VERSION "1.11.2"

NS_ :

BS_:

BU_: TCU BRK ESP MCU RDD GP TMS GW KPD1 RDE FNR ECU KPD2 ATSGO ACU IMU1 IMU2 IMU3 IMU4 IMU5 AGW PMI HDOQS EGOQS OBC EEC CBSW EJRH EJLH EPDLT EPDL2 EPDLR EPDLA TRBDZ ECU1 CLST LC510 EGDL JS SMB KPAC ACCU Audio TGU RDRR RDLH RDRH AVM CHMSL CTC SMK EVC MCU2 PHM MC3D AMBLMP RCTGU RDU PT3D XCU can1 can2

BO_ 2566879562 TGU_TGUID: 35 TGU
 SG_ ProdDt : 208|72@1+ (1,0) [0|4.72236648286965E+21] "ASCII-FN" Vector__XXX
 SG_ TguId : 48|160@1+ (1,0) [0|1.4615016373309E+48] "ASCII-FN" Vector__XXX
 SG_ TypeCd : 0|48@1+ (1,0) [0|281474976710655] "ASCII-FN" Vector__XXX

BO_ 2583645002 TGU_GPSINFO: 13 TGU
 SG_ GpsSt : 96|8@1+ (1,0) [0|255] "" Vector__XXX
 SG_ NoOfGpsSat : 88|8@1+ (1,0) [0|255] "" Vector__XXX
 SG_ Z : 64|16@1+ (0.125,-2500) [-2500|5531.875] "m" Vector__XXX
 SG_ Y : 32|32@1+ (1E-07,-210) [-210|211.1081215] "deg" Vector__XXX
 SG_ X : 0|32@1+ (1E-07,-210) [-210|211.1081215] "deg" Vector__XXX

BO_ 2583644490 TGU_CINFO: 145 TGU
 SG_ GsmdBm : 1128|32@1+ (1,0) [0|4294967295] "ASCII-FN" Vector__XXX
 SG_ GsmType : 1120|8@1+ (1,0) [0|255] "" Vector__XXX
 SG_ CurNw : 1048|72@1+ (1,0) [0|4.72236648286965E+21] "ASCII-FN" Vector__XXX
 SG_ TmnIpAdr : 920|128@1+ (1,0) [0|3.40282366920938E+38] "ASCII-FN" Vector__XXX
 SG_ ServerAdr : 792|128@1+ (1,0) [0|3.40282366920938E+38] "ASCII-FN" Vector__XXX
 SG_ Apn : 288|504@1+ (1,0) [0|5.23742497263383E+151] "ASCII-FN" Vector__XXX
 SG_ Imei : 168|120@1+ (1,0) [0|1.32922799578492E+36] "ASCII-FN" Vector__XXX
 SG_ SimIccid : 0|168@1+ (1,0) [0|3.74144419156711E+50] "ASCII-FN" Vector__XXX

BO_ 2566878282 TGU_SAT: 18 TGU
 SG_ Install : 136|4@1+ (1,0) [0|3] "" Vector__XXX
 SG_ Imei : 16|120@1+ (1,0) [0|1.32922799578492E+36] "ASCII" Vector__XXX
 SG_ Rssi : 8|8@1+ (1,0) [0|255] "" Vector__XXX
 SG_ Type : 4|4@1+ (1,0) [0|3] "" Vector__XXX
 SG_ Enable : 0|4@1+ (1,0) [0|3] "" Vector__XXX

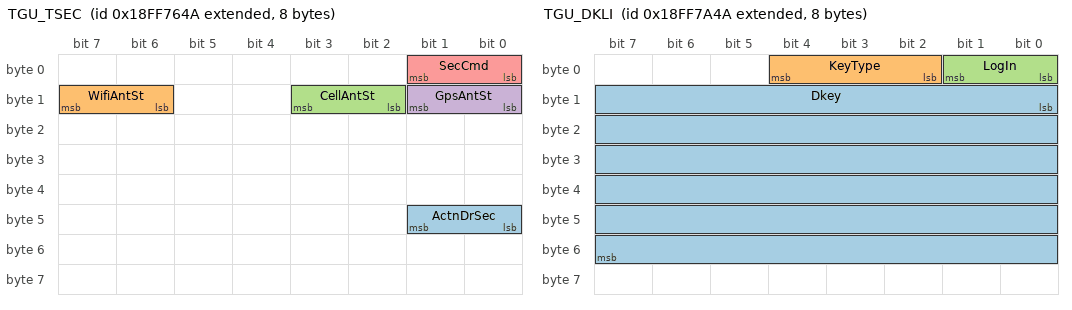
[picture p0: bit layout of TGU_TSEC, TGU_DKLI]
BO_ 2566878794 TGU_TSEC: 8 TGU
 SG_ ActnDrSec : 40|2@1+ (1,0) [0|3] "" Vector__XXX
 SG_ WifiAntSt : 14|2@1+ (1,0) [0|3] "" Vector__XXX
 SG_ CellAntSt : 10|2@1+ (1,0) [0|3] "" Vector__XXX
 SG_ GpsAntSt : 8|2@1+ (1,0) [0|3] "" Vector__XXX
 SG_ SecCmd : 0|2@1+ (1,0) [0|3] "" Vector__XXX

BO_ 2583644746 TGU_TGUTM: 8 TGU
 SG_ UtcTm : 32|32@1+ (1,0) [0|4294967295] "sec" Vector__XXX
 SG_ LocalTmOffset : 0|32@1+ (1,0) [-2147483647|2147483647] "sec" Vector__XXX

BO_ 2566879272 GP_TMSTP: 8 GP

BO_ 2566879306 TGU_TMSTP: 8 TGU

BO_ 2566879818 TGU_DKLI: 8 TGU
 SG_ Dkey : 8|48@1+ (1,0) [0|0] "binary" Vector__XXX
 SG_ KeyType : 2|3@1+ (1,0) [0|7] "" Vector__XXX
 SG_ LogIn : 0|2@1+ (1,0) [0|3] "" Vector__XXX

BO_ 2566880074 TGU_DKLD: 37 TGU
 SG_ DkeyList : 8|288@1+ (1,0) [0|4.97323236409787E+86] "binary" Vector__XXX
 SG_ Cnt : 0|8@1+ (1,0) [0|255] "" Vector__XXX

BO_ 2566880296 GP_DKSEL: 8 GP
 SG_ DigitalKey : 8|48@1+ (1,0) [0|281474976710655] "" Vector__XXX
 SG_ SelType : 0|3@1+ (1,0) [0|7] "" Vector__XXX

BO_ 2566880586 TGU_TACK: 8 TGU
 SG_ Ack : 0|2@1+ (1,0) [0|3] "" Vector__XXX

BO_ 2566880842 TGU_TMSPUC: 8 TGU
 SG_ TmsPmntUnlockCd : 0|32@1+ (1,0) [0|4294967295] "" Vector__XXX

BO_ 2566881064 GP_TMSPP: 8 GP

BO_ 2566881098 TGU_TMSPP: 8 TGU

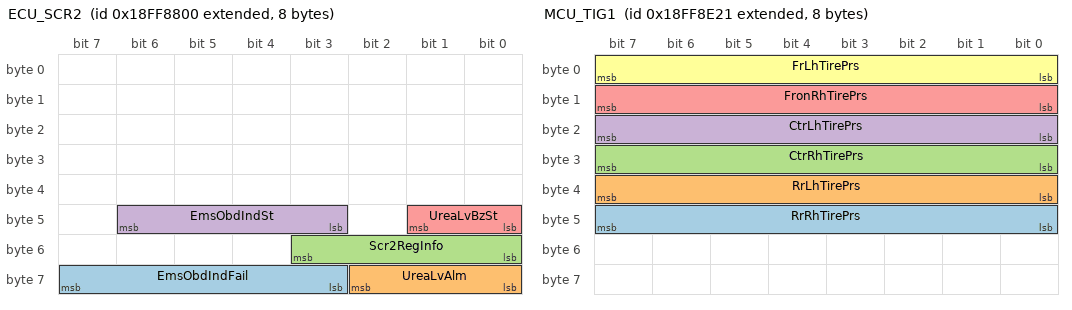
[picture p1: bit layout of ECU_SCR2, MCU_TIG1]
BO_ 2566883328 ECU_SCR2: 8 ECU
 SG_ EmsObdIndFail : 59|5@1+ (1,0) [0|31] "" Vector__XXX
 SG_ UreaLvAlm : 56|3@1+ (1,0) [0|7] "" Vector__XXX
 SG_ Scr2RegInfo : 48|4@1+ (1,0) [0|15] "" Vector__XXX
 SG_ EmsObdIndSt : 43|4@1+ (1,0) [0|15] "" Vector__XXX
 SG_ UreaLvBzSt : 40|2@1+ (1,0) [0|3] "" Vector__XXX

BO_ 2583625761 MCU_AASI: 70 MCU
 SG_ RrSspnLhSsPrs : 544|16@1+ (0.0625,0) [0|500] "bar" Vector__XXX
 SG_ RrSspnRhSsPrs : 528|16@1+ (0.0625,0) [0|500] "bar" Vector__XXX
 SG_ AcpSsPrs : 512|16@1+ (16,0) [0|4000] "kPa" Vector__XXX
 SG_ BatVlt : 496|16@1+ (1,0) [0|40000] "V" Vector__XXX
 SG_ AltVlt : 480|16@1+ (0.001,0) [0|64.255] "V" Vector__XXX
 SG_ Rr2BrkSsPrs : 464|16@1+ (0.0625,0) [0|500] "bar" Vector__XXX
 SG_ BoomCylRodSsPrs : 448|16@1+ (0.0625,0) [0|500] "bar" Vector__XXX
 SG_ BoomCylHeadSsPrs : 432|16@1+ (0.0625,0) [0|500] "bar" Vector__XXX
 SG_ CtrPinAngSs1Vlt : 416|16@1+ (0.001,0) [0|64.255] "V" Vector__XXX
 SG_ AccPdlSs2Vlt : 400|16@1+ (0.001,0) [0|64.255] "V" Vector__XXX
 SG_ DumpBedAngSs2Vlt : 384|16@1+ (0.001,0) [0|64.255] "V" Vector__XXX
 SG_ DumpBedAngSs1Vlt : 368|16@1+ (0.001,0) [0|64.255] "V" Vector__XXX
 SG_ BrkInchPdlSs1Vlt : 352|16@1+ (0.001,0) [0|64.255] "V" Vector__XXX
 SG_ TipJoySs1Vlt : 336|16@1+ (0.001,0) [0|64.255] "V" Vector__XXX
 SG_ RhCylSsPrs : 320|16@1+ (0.0625,0) [0|500] "bar" Vector__XXX
 SG_ EmgStrSsPrs : 304|16@1+ (0.0625,0) [0|500] "bar" Vector__XXX
 SG_ AxleOilSsTmp : 288|16@1- (1,-40) [-40|210] "celsius" Vector__XXX
 SG_ FuelSsLv : 272|16@1+ (1,0) [0|250] "percent" Vector__XXX
 SG_ Rr1BrkSsPrs : 256|16@1+ (0.0625,0) [0|500] "bar" Vector__XXX
 SG_ FrBrkSsPrs : 240|16@1+ (0.0625,0) [0|500] "bar" Vector__XXX
 SG_ AccPdlSs1Vlt : 224|16@1+ (0.001,0) [0|64.255] "V" Vector__XXX
 SG_ CtrPinAngSs2Vlt : 208|16@1+ (0.001,0) [0|64.255] "V" Vector__XXX
 SG_ TmsSecVlt : 192|16@1+ (0.001,0) [0|64.255] "V" Vector__XXX
 SG_ LhCylSsPrs : 176|16@1+ (0.0625,0) [0|500] "bar" Vector__XXX
 SG_ Acc3SsPrs : 160|16@1+ (0.0625,0) [0|500] "bar" Vector__XXX
 SG_ BrkInchPdlSs2Vlt : 144|16@1+ (0.001,0) [0|64.255] "V" Vector__XXX
 SG_ CacFanSsPrs : 128|16@1+ (0.0625,0) [0|500] "bar" Vector__XXX
 SG_ Acc2SsPrs : 112|16@1+ (0.0625,0) [0|500] "bar" Vector__XXX
 SG_ TipJoySs2Vlt : 96|16@1+ (0.001,0) [0|64.255] "V" Vector__XXX
 SG_ TocFanSsPrs : 80|16@1+ (0.0625,0) [0|500] "bar" Vector__XXX
 SG_ Acc1SsPrs : 64|16@1+ (0.0625,0) [0|500] "bar" Vector__XXX
 SG_ PrkBrkSsPrs : 48|16@1+ (0.0625,0) [0|500] "bar" Vector__XXX
 SG_ MainSsPrs : 32|16@1+ (0.0625,0) [0|500] "bar" Vector__XXX
 SG_ WifSsVlt : 16|16@1+ (0.001,0) [0|64.255] "V" Vector__XXX
 SG_ HydOilSsTmp : 0|16@1- (1,-40) [-40|210] "celsius" Vector__XXX

BO_ 2583626017 MCU_AAAI: 16 MCU
 SG_ FanDrvTocEvc : 112|16@1+ (1,0) [0|2000] "mA" Vector__XXX
 SG_ eFan2DutyRatio : 96|16@1- (0.01,-321.27) [-321.27|321.28] "percent" Vector__XXX
 SG_ eFan3DutyRatio : 80|16@1- (0.01,-321.27) [-321.27|321.28] "percent" Vector__XXX
 SG_ eBrkEvc : 64|16@1+ (1,0) [0|2000] "mA" Vector__XXX
 SG_ eFan1DutyRatio : 48|16@1- (0.01,-321.27) [-321.27|321.28] "percent" Vector__XXX
 SG_ FanDrvRadCacEvc : 32|16@1+ (1,0) [0|2000] "mA" Vector__XXX
 SG_ BodyDnEvc : 16|16@1+ (1,0) [0|2000] "mA" Vector__XXX
 SG_ BodyUpEvc : 0|16@1+ (1,0) [0|2000] "mA" Vector__XXX

BO_ 2583626273 MCU_ADSI: 250 MCU
 SG_ BrkholdSw : 44|2@1+ (1,0) [0|3] "" Vector__XXX
 SG_ DhlMnSw : 42|2@1+ (1,0) [0|3] "" Vector__XXX
 SG_ CoolTankLvSw : 40|2@1+ (1,0) [0|3] "" Vector__XXX
 SG_ StartCrkSw : 38|2@1+ (1,0) [0|3] "" Vector__XXX
 SG_ GrSelSw : 36|2@1+ (1,0) [0|3] "" Vector__XXX
 SG_ GrSelNtrlSw : 34|2@1+ (1,0) [0|3] "" Vector__XXX
 SG_ PrkSw : 32|2@1+ (1,0) [0|3] "" Vector__XXX
 SG_ GrSelRvsSw : 30|2@1+ (1,0) [0|3] "" Vector__XXX
 SG_ GrSelShftDnSw : 28|2@1+ (1,0) [0|3] "" Vector__XXX
 SG_ GrSelShftUpSw : 26|2@1+ (1,0) [0|3] "" Vector__XXX
 SG_ GrSelFwdSw : 24|2@1+ (1,0) [0|3] "" Vector__XXX
 SG_ DustIndSw : 22|2@1+ (1,0) [0|3] "" Vector__XXX
 SG_ StartAccSw : 20|2@1+ (1,0) [0|3] "" Vector__XXX
 SG_ AtsForceRgnSw : 18|2@1+ (1,0) [0|3] "" Vector__XXX
 SG_ AtsRgnIhbsw : 16|2@1+ (1,0) [0|3] "" Vector__XXX
 SG_ eFan3ErrSt : 14|2@1+ (1,0) [0|3] "" Vector__XXX
 SG_ KeyBrSw : 12|2@1+ (1,0) [0|3] "" Vector__XXX
 SG_ TipJoySw : 10|2@1+ (1,0) [0|3] "" Vector__XXX
 SG_ AgsSw : 8|2@1+ (1,0) [0|3] "" Vector__XXX
 SG_ eFan2ErrSt : 6|2@1+ (1,0) [0|3] "" Vector__XXX
 SG_ eFan1ErrSt : 4|2@1+ (1,0) [0|3] "" Vector__XXX
 SG_ SeatBeltSt : 2|2@1+ (1,0) [0|3] "" Vector__XXX
 SG_ FrWiperStpSw : 0|2@1+ (1,0) [0|3] "" Vector__XXX

BO_ 2583626529 MCU_ADAI: 250 MCU
 SG_ RrSspnRhDn : 48|2@1+ (1,0) [0|3] "" Vector__XXX
 SG_ RrSspnRhUp : 46|2@1+ (1,0) [0|3] "" Vector__XXX
 SG_ RrSspnLhDn : 44|2@1+ (1,0) [0|3] "" Vector__XXX
 SG_ RrSspnLhUp : 42|2@1+ (1,0) [0|3] "" Vector__XXX
 SG_ SusRhDn : 40|2@1+ (1,0) [0|3] "" Vector__XXX
 SG_ TocRvs : 38|2@1+ (1,0) [0|3] "" Vector__XXX
 SG_ TurnSigRhRly : 36|2@1+ (1,0) [0|3] "" Vector__XXX
 SG_ TurnSigLhRly : 34|2@1+ (1,0) [0|3] "" Vector__XXX
 SG_ SusRhUp : 32|2@1+ (1,0) [0|3] "" Vector__XXX
 SG_ EgRunOutSig : 30|2@1+ (1,0) [0|3] "" Vector__XXX
 SG_ SusLhDn : 28|2@1+ (1,0) [0|3] "" Vector__XXX
 SG_ UreaSuperChgWrnSig : 26|2@1+ (1,0) [0|3] "" Vector__XXX
 SG_ FanStpSv : 24|2@1+ (1,0) [0|3] "" Vector__XXX
 SG_ SusLhUp : 18|2@1+ (1,0) [0|3] "" Vector__XXX
 SG_ PrkBrkRlsSv : 16|2@1+ (1,0) [0|3] "" Vector__XXX
 SG_ AxleOilCoolSv : 14|2@1+ (1,0) [0|3] "" Vector__XXX
 SG_ TocUnloading : 12|2@1+ (1,0) [0|3] "" Vector__XXX
 SG_ AccRly : 10|2@1+ (1,0) [0|3] "" Vector__XXX
 SG_ LiftArmFlt : 6|2@1+ (1,0) [0|3] "" Vector__XXX
 SG_ AutoShutOffRly : 4|2@1+ (1,0) [0|3] "" Vector__XXX
 SG_ BrkChgSv : 2|2@1+ (1,0) [0|3] "" Vector__XXX

BO_ 2566884897 MCU_TIG1: 8 MCU
 SG_ RrRhTirePrs : 40|8@1+ (4,0) [0|1000] "kPa" Vector__XXX
 SG_ RrLhTirePrs : 32|8@1+ (4,0) [0|1000] "kPa" Vector__XXX
 SG_ CtrRhTirePrs : 24|8@1+ (4,0) [0|1000] "kPa" Vector__XXX
 SG_ CtrLhTirePrs : 16|8@1+ (4,0) [0|1000] "kPa" Vector__XXX
 SG_ FronRhTirePrs : 8|8@1+ (4,0) [0|1000] "kPa" Vector__XXX
 SG_ FrLhTirePrs : 0|8@1+ (4,0) [0|1000] "kPa" Vector__XXX

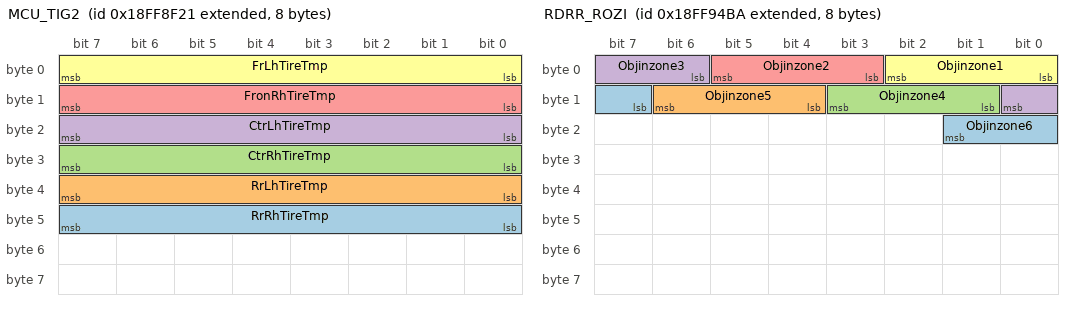
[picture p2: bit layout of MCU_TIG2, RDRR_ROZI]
BO_ 2566885153 MCU_TIG2: 8 MCU
 SG_ RrRhTireTmp : 40|8@1- (1,-40) [-40|210] "celsius" Vector__XXX
 SG_ RrLhTireTmp : 32|8@1- (1,-40) [-40|210] "celsius" Vector__XXX
 SG_ CtrRhTireTmp : 24|8@1- (1,-40) [-40|210] "celsius" Vector__XXX
 SG_ CtrLhTireTmp : 16|8@1- (1,-40) [-40|210] "celsius" Vector__XXX
 SG_ FronRhTireTmp : 8|8@1- (1,-40) [-40|210] "celsius" Vector__XXX
 SG_ FrLhTireTmp : 0|8@1- (1,-40) [-40|210] "celsius" Vector__XXX

BO_ 2566885409 MCU_QRCI: 55 MCU
 SG_ PartNo : 312|128@1+ (1,0) [0|3.40282366920938E+38] "ASCII-FN" Vector__XXX
 SG_ SerialNo : 184|128@1+ (1,0) [0|3.40282366920938E+38] "ASCII-FN" Vector__XXX
 SG_ MnftCode : 120|64@1+ (1,0) [0|1.84467440737096E+19] "ASCII-FN" Vector__XXX
 SG_ ComCode : 56|64@1+ (1,0) [0|1.84467440737096E+19] "ASCII-FN" Vector__XXX
 SG_ Year : 48|8@1+ (1,1985) [1985|2235] "year" Vector__XXX
 SG_ Day : 40|8@1+ (0.25,0) [0|62.5] "days" Vector__XXX
 SG_ Month : 32|8@1+ (1,0) [0|250] "month" Vector__XXX
 SG_ SwVer : 0|32@1+ (1,0) [0|4294967295] "ASCII" Vector__XXX

BO_ 2566885665 MCU_ECORI: 30 MCU
 SG_ TotAvgReliefOprPct : 232|8@1+ (1,0) [0|250] "percent" Vector__XXX
 SG_ TotAvgLwIdleOprPct : 224|8@1+ (1,0) [0|250] "percent" Vector__XXX
 SG_ TotAvgHhIdleOprPct : 216|8@1+ (1,0) [0|250] "percent" Vector__XXX
 SG_ Day7ReliefOprPct : 208|8@1+ (1,0) [0|250] "percent" Vector__XXX
 SG_ Day7LwIdleOprPct : 200|8@1+ (1,0) [0|250] "percent" Vector__XXX
 SG_ Day7HhIdleOprPct : 192|8@1+ (1,0) [0|250] "percent" Vector__XXX
 SG_ Day6ReliefOprPct : 184|8@1+ (1,0) [0|250] "percent" Vector__XXX
 SG_ Day6LwIdleOprPct : 176|8@1+ (1,0) [0|250] "percent" Vector__XXX
 SG_ Day6HhIdleOprPct : 168|8@1+ (1,0) [0|250] "percent" Vector__XXX
 SG_ Day5ReliefOprPct : 160|8@1+ (1,0) [0|250] "percent" Vector__XXX
 SG_ Day5LwIdleOprPct : 152|8@1+ (1,0) [0|250] "percent" Vector__XXX
 SG_ Day5HhIdleOprPct : 144|8@1+ (1,0) [0|250] "percent" Vector__XXX
 SG_ Day4ReliefOprPct : 136|8@1+ (1,0) [0|250] "percent" Vector__XXX
 SG_ Day4LwIdleOprPct : 128|8@1+ (1,0) [0|250] "percent" Vector__XXX
 SG_ Day4HhIdleOprPct : 120|8@1+ (1,0) [0|250] "percent" Vector__XXX
 SG_ Day3ReliefOprPct : 112|8@1+ (1,0) [0|250] "percent" Vector__XXX
 SG_ Day3LwIdleOprPct : 104|8@1+ (1,0) [0|250] "percent" Vector__XXX
 SG_ Day3HhIdleOprPct : 96|8@1+ (1,0) [0|250] "percent" Vector__XXX
 SG_ Day2ReliefOprPct : 88|8@1+ (1,0) [0|250] "percent" Vector__XXX
 SG_ Day2LwIdleOprPct : 80|8@1+ (1,0) [0|250] "percent" Vector__XXX
 SG_ Day2HhIdleOprPct : 72|8@1+ (1,0) [0|250] "percent" Vector__XXX
 SG_ Day1ReliefOprPct : 64|8@1+ (1,0) [0|250] "percent" Vector__XXX
 SG_ Day1LwIdleOprPct : 56|8@1+ (1,0) [0|250] "percent" Vector__XXX
 SG_ Day1HhIdleOprPct : 48|8@1+ (1,0) [0|250] "percent" Vector__XXX
 SG_ NowReliefOprLv : 40|8@1+ (1,0) [0|250] "percent" Vector__XXX
 SG_ NowLwIdleOprLv : 32|8@1+ (1,0) [0|250] "percent" Vector__XXX
 SG_ NowHhIdleOprLv : 24|8@1+ (1,0) [0|250] "percent" Vector__XXX
 SG_ NowReliefOprPct : 16|8@1+ (1,0) [0|250] "percent" Vector__XXX
 SG_ NowLwIdleOprPct : 8|8@1+ (1,0) [0|250] "percent" Vector__XXX
 SG_ NowHhIdleOprPct : 0|8@1+ (1,0) [0|250] "percent" Vector__XXX

BO_ 2566886586 RDRR_ROZI: 8 RDRR
 SG_ Objinzone6 : 15|3@1+ (1,0) [0|7] "" Vector__XXX
 SG_ Objinzone5 : 12|3@1+ (1,0) [0|7] "" Vector__XXX
 SG_ Objinzone4 : 9|3@1+ (1,0) [0|7] "" Vector__XXX
 SG_ Objinzone3 : 6|3@1+ (1,0) [0|7] "" Vector__XXX
 SG_ Objinzone2 : 3|3@1+ (1,0) [0|7] "" Vector__XXX
 SG_ Objinzone1 : 0|3@1+ (1,0) [0|7] "" Vector__XXX

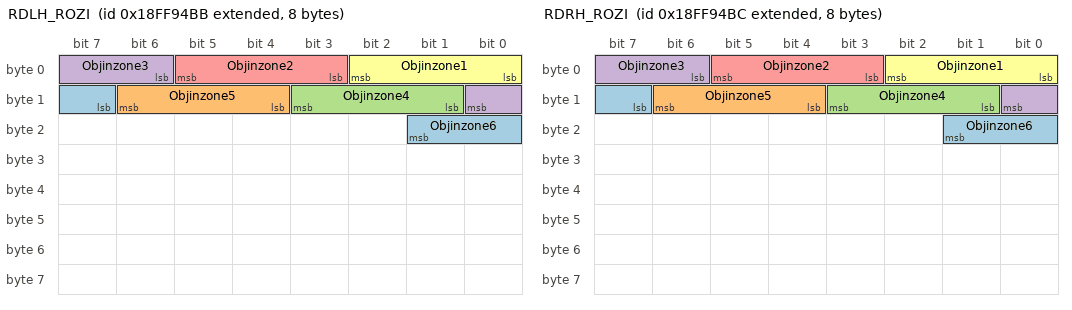
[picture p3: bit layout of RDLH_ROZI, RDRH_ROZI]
BO_ 2566886587 RDLH_ROZI: 8 RDLH
 SG_ Objinzone6 : 15|3@1+ (1,0) [0|7] "" Vector__XXX
 SG_ Objinzone5 : 12|3@1+ (1,0) [0|7] "" Vector__XXX
 SG_ Objinzone4 : 9|3@1+ (1,0) [0|7] "" Vector__XXX
 SG_ Objinzone3 : 6|3@1+ (1,0) [0|7] "" Vector__XXX
 SG_ Objinzone2 : 3|3@1+ (1,0) [0|7] "" Vector__XXX
 SG_ Objinzone1 : 0|3@1+ (1,0) [0|7] "" Vector__XXX

BO_ 2566886588 RDRH_ROZI: 8 RDRH
 SG_ Objinzone6 : 15|3@1+ (1,0) [0|7] "" Vector__XXX
 SG_ Objinzone5 : 12|3@1+ (1,0) [0|7] "" Vector__XXX
 SG_ Objinzone4 : 9|3@1+ (1,0) [0|7] "" Vector__XXX
 SG_ Objinzone3 : 6|3@1+ (1,0) [0|7] "" Vector__XXX
 SG_ Objinzone2 : 3|3@1+ (1,0) [0|7] "" Vector__XXX
 SG_ Objinzone1 : 0|3@1+ (1,0) [0|7] "" Vector__XXX

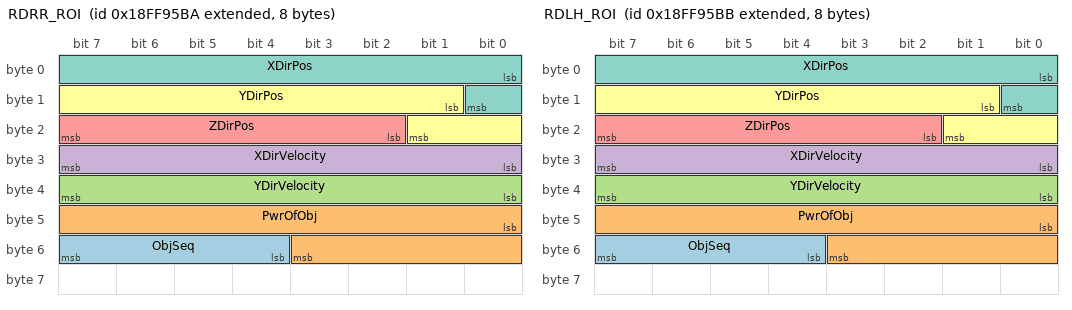
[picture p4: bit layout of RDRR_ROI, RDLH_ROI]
BO_ 2566886842 RDRR_ROI: 8 RDRR
 SG_ ObjSeq : 52|4@1+ (1,0) [0|10] "" Vector__XXX
 SG_ PwrOfObj : 40|12@1+ (1,0) [0|2500] "" Vector__XXX
 SG_ YDirVelocity : 32|8@1+ (0.2,-12) [-12|12] "mps" Vector__XXX
 SG_ XDirVelocity : 24|8@1+ (0.2,-12) [-12|12] "mps" Vector__XXX
 SG_ ZDirPos : 18|6@1+ (0.1,-3) [-3|3] "m" Vector__XXX
 SG_ YDirPos : 9|9@1+ (0.1,-16) [-16|16] "m" Vector__XXX
 SG_ XDirPos : 0|9@1+ (0.1,-16) [-16|16] "m" Vector__XXX

BO_ 2566886843 RDLH_ROI: 8 RDLH
 SG_ ObjSeq : 52|4@1+ (1,0) [0|10] "" Vector__XXX
 SG_ PwrOfObj : 40|12@1+ (1,0) [0|2500] "" Vector__XXX
 SG_ YDirVelocity : 32|8@1+ (0.2,-12) [-12|12] "mps" Vector__XXX
 SG_ XDirVelocity : 24|8@1+ (0.2,-12) [-12|12] "mps" Vector__XXX
 SG_ ZDirPos : 18|6@1+ (0.1,-3) [-3|3] "m" Vector__XXX
 SG_ YDirPos : 9|9@1+ (0.1,-16) [-16|16] "m" Vector__XXX
 SG_ XDirPos : 0|9@1+ (0.1,-16) [-16|16] "m" Vector__XXX

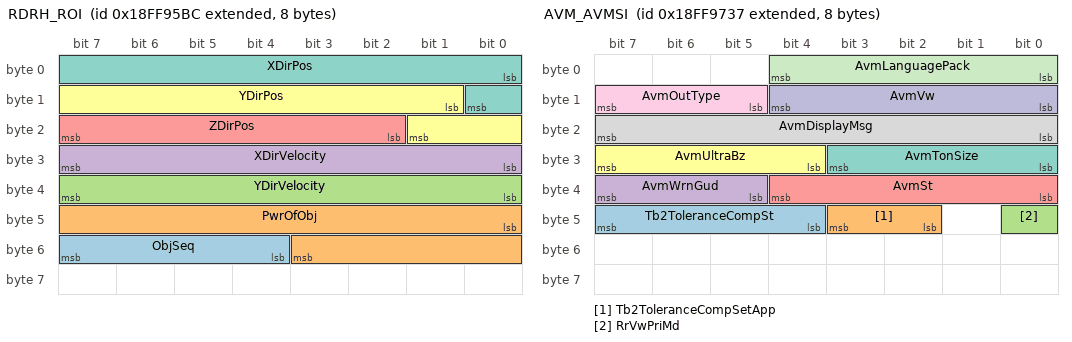
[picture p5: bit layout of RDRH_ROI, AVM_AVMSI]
BO_ 2566886844 RDRH_ROI: 8 RDRH
 SG_ ObjSeq : 52|4@1+ (1,0) [0|10] "" Vector__XXX
 SG_ PwrOfObj : 40|12@1+ (1,0) [0|2500] "" Vector__XXX
 SG_ YDirVelocity : 32|8@1+ (0.2,-12) [-12|12] "mps" Vector__XXX
 SG_ XDirVelocity : 24|8@1+ (0.2,-12) [-12|12] "mps" Vector__XXX
 SG_ ZDirPos : 18|6@1+ (0.1,-3) [-3|3] "m" Vector__XXX
 SG_ YDirPos : 9|9@1+ (0.1,-16) [-16|16] "m" Vector__XXX
 SG_ XDirPos : 0|9@1+ (0.1,-16) [-16|16] "m" Vector__XXX

BO_ 2566886952 GP_AVMVM: 8 GP
 SG_ RrVwPriMd : 4|1@1+ (1,0) [0|1] "" Vector__XXX
 SG_ VwMd : 0|4@1+ (1,0) [0|15] "" Vector__XXX

BO_ 2566887223 AVM_AVMSI: 8 AVM
 SG_ Tb2ToleranceCompSt : 44|4@1+ (1,0) [0|15] "" Vector__XXX
 SG_ Tb2ToleranceCompSetApp : 42|2@1+ (1,0) [0|3] "" Vector__XXX
 SG_ RrVwPriMd : 40|1@1+ (1,0) [0|1] "" Vector__XXX
 SG_ AvmWrnGud : 37|3@1+ (1,0) [0|7] "" Vector__XXX
 SG_ AvmSt : 32|5@1+ (1,0) [0|31] "" Vector__XXX
 SG_ AvmUltraBz : 28|4@1+ (1,0) [0|15] "" Vector__XXX
 SG_ AvmTonSize : 24|4@1+ (1,0) [0|15] "" Vector__XXX
 SG_ AvmDisplayMsg : 16|8@1+ (1,0) [0|255] "" Vector__XXX
 SG_ AvmOutType : 13|3@1+ (1,0) [0|7] "" Vector__XXX
 SG_ AvmVw : 8|5@1+ (1,0) [0|31] "" Vector__XXX
 SG_ AvmLanguagePack : 0|5@1+ (1,0) [0|31] "" Vector__XXX

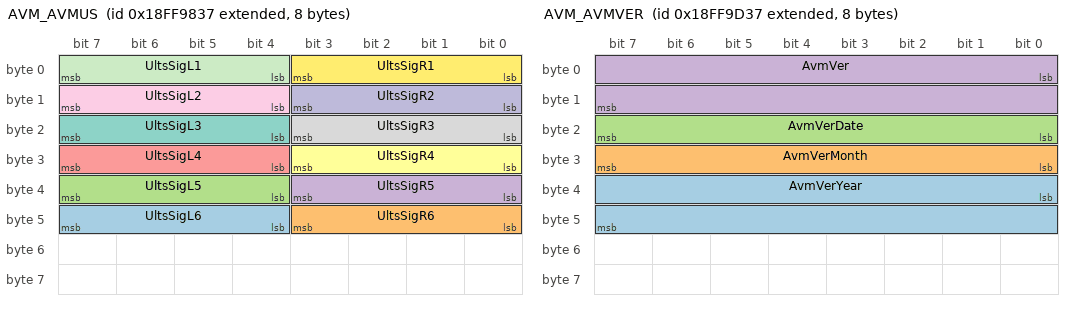
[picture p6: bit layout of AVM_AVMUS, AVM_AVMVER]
BO_ 2566887479 AVM_AVMUS: 8 AVM
 SG_ UltsSigL6 : 44|4@1+ (1,0) [0|15] "" Vector__XXX
 SG_ UltsSigR6 : 40|4@1+ (1,0) [0|15] "" Vector__XXX
 SG_ UltsSigL5 : 36|4@1+ (1,0) [0|15] "" Vector__XXX
 SG_ UltsSigR5 : 32|4@1+ (1,0) [0|15] "" Vector__XXX
 SG_ UltsSigL4 : 28|4@1+ (1,0) [0|15] "" Vector__XXX
 SG_ UltsSigR4 : 24|4@1+ (1,0) [0|15] "" Vector__XXX
 SG_ UltsSigL3 : 20|4@1+ (1,0) [0|15] "" Vector__XXX
 SG_ UltsSigR3 : 16|4@1+ (1,0) [0|15] "" Vector__XXX
 SG_ UltsSigL2 : 12|4@1+ (1,0) [0|15] "" Vector__XXX
 SG_ UltsSigR2 : 8|4@1+ (1,0) [0|15] "" Vector__XXX
 SG_ UltsSigL1 : 4|4@1+ (1,0) [0|15] "" Vector__XXX
 SG_ UltsSigR1 : 0|4@1+ (1,0) [0|15] "" Vector__XXX

BO_ 2566887720 GP_AVMRM: 8 GP
 SG_ CamPrmtCorCompleteSt : 63|1@1+ (1,0) [0|1] "" Vector__XXX
 SG_ CamPrmtVerMsb : 56|7@1+ (1,0) [0|127] "" Vector__XXX
 SG_ CamPrmtVerLsb : 48|8@1+ (1,0) [0|255] "" Vector__XXX
 SG_ Language : 42|6@1+ (1,0) [0|63] "" Vector__XXX
 SG_ ToleranceCorMenuentryCmd : 41|1@1+ (1,0) [0|1] "" Vector__XXX
 SG_ WrnGudSetCmd : 40|1@1+ (1,0) [0|1] "" Vector__XXX
 SG_ UltsSs08Cmd : 39|1@1+ (1,0) [0|1] "" Vector__XXX
 SG_ UltsSs07Cmd : 38|1@1+ (1,0) [0|1] "" Vector__XXX
 SG_ UltsSs06Cmd : 37|1@1+ (1,0) [0|1] "" Vector__XXX
 SG_ UltsSs05Cmd : 36|1@1+ (1,0) [0|1] "" Vector__XXX
 SG_ UltsSs04Cmd : 35|1@1+ (1,0) [0|1] "" Vector__XXX
 SG_ UltsSs03Cmd : 34|1@1+ (1,0) [0|1] "" Vector__XXX
 SG_ UltsSs02Cmd : 33|1@1+ (1,0) [0|1] "" Vector__XXX
 SG_ UltsSs01Cmd : 32|1@1+ (1,0) [0|1] "" Vector__XXX
 SG_ UltsSs12Cmd : 31|1@1+ (1,0) [0|1] "" Vector__XXX
 SG_ UltsSs11Cmd : 30|1@1+ (1,0) [0|1] "" Vector__XXX
 SG_ UltsSs10Cmd : 29|1@1+ (1,0) [0|1] "" Vector__XXX
 SG_ UltsSs09Cmd : 28|1@1+ (1,0) [0|1] "" Vector__XXX
 SG_ SetApplicationCmd : 27|1@1+ (1,0) [0|1] "" Vector__XXX
 SG_ ToleranceCorCmd : 25|2@1+ (1,0) [0|3] "" Vector__XXX
 SG_ FactoryReCmd : 24|1@1+ (1,0) [0|1] "" Vector__XXX
 SG_ UltsSsOpt : 23|1@1+ (1,0) [0|1] "" Vector__XXX
 SG_ UltsBuzzerStopSig : 22|1@1+ (1,0) [0|1] "" Vector__XXX
 SG_ BoomCamOpt : 21|1@1+ (1,0) [0|1] "" Vector__XXX
 SG_ UltsBzOffSig : 20|1@1+ (1,0) [0|1] "" Vector__XXX
 SG_ UltsRecognitionDistanceSet : 19|1@1+ (1,0) [0|1] "" Vector__XXX
 SG_ VhcType2 : 17|2@1+ (1,0) [0|3] "" Vector__XXX
 SG_ VhcType1 : 16|1@1+ (1,0) [0|1] "" Vector__XXX
 SG_ TonsOftheTensDigit : 12|4@1+ (1,0) [0|15] "" Vector__XXX
 SG_ TonsOftheUnitsDigit : 8|4@1+ (1,0) [0|15] "" Vector__XXX
 SG_ FactoryType : 4|4@1+ (1,0) [0|15] "" Vector__XXX
 SG_ VwMd : 0|4@1+ (1,0) [0|15] "" Vector__XXX

BO_ 2566887991 AVM_AVMSM: 8 AVM
 SG_ CamPrmtCorCompleteSt : 63|1@1+ (1,0) [0|1] "" Vector__XXX
 SG_ CamPrmtVerMsb : 56|7@1+ (1,0) [0|127] "" Vector__XXX
 SG_ CamPrmtVerLsb : 48|8@1+ (1,0) [0|255] "" Vector__XXX
 SG_ Language : 42|6@1+ (1,0) [0|63] "" Vector__XXX
 SG_ ToleranceCorMenuentryCmd : 41|1@1+ (1,0) [0|1] "" Vector__XXX
 SG_ WrnGudSetCmd : 40|1@1+ (1,0) [0|1] "" Vector__XXX
 SG_ UltsSs08Cmd : 39|1@1+ (1,0) [0|1] "" Vector__XXX
 SG_ UltsSs07Cmd : 38|1@1+ (1,0) [0|1] "" Vector__XXX
 SG_ UltsSs06Cmd : 37|1@1+ (1,0) [0|1] "" Vector__XXX
 SG_ UltsSs05Cmd : 36|1@1+ (1,0) [0|1] "" Vector__XXX
 SG_ UltsSs04Cmd : 35|1@1+ (1,0) [0|1] "" Vector__XXX
 SG_ UltsSs03Cmd : 34|1@1+ (1,0) [0|1] "" Vector__XXX
 SG_ UltsSs02Cmd : 33|1@1+ (1,0) [0|1] "" Vector__XXX
 SG_ UltsSs01Cmd : 32|1@1+ (1,0) [0|1] "" Vector__XXX
 SG_ UltsSs12Cmd : 31|1@1+ (1,0) [0|1] "" Vector__XXX
 SG_ UltsSs11Cmd : 30|1@1+ (1,0) [0|1] "" Vector__XXX
 SG_ UltsSs10Cmd : 29|1@1+ (1,0) [0|1] "" Vector__XXX
 SG_ UltsSs09Cmd : 28|1@1+ (1,0) [0|1] "" Vector__XXX
 SG_ SetAppCmd : 27|1@1+ (1,0) [0|1] "" Vector__XXX
 SG_ ToleranceCorCmd : 25|2@1+ (1,0) [0|3] "" Vector__XXX
 SG_ FactoryResetCmd : 24|1@1+ (1,0) [0|1] "" Vector__XXX
 SG_ UltsSsOpt : 23|1@1+ (1,0) [0|1] "" Vector__XXX
 SG_ UltsBzStopSig : 22|1@1+ (1,0) [0|1] "" Vector__XXX
 SG_ BoomCamOpt : 21|1@1+ (1,0) [0|1] "" Vector__XXX
 SG_ UltsBzOffSig : 20|1@1+ (1,0) [0|1] "" Vector__XXX
 SG_ UltsRecognitionDistanceSet : 19|1@1+ (1,0) [0|1] "" Vector__XXX
 SG_ VhcType2 : 17|2@1+ (1,0) [0|3] "" Vector__XXX
 SG_ VhcType1 : 16|1@1+ (1,0) [0|1] "" Vector__XXX
 SG_ TonsOftheTensDigit : 12|4@1+ (1,0) [0|15] "" Vector__XXX
 SG_ TonsOftheUnitsDigit : 8|4@1+ (1,0) [0|15] "" Vector__XXX
 SG_ FactoryType : 4|4@1+ (1,0) [0|15] "" Vector__XXX
 SG_ VwMd : 0|4@1+ (1,0) [0|15] "" Vector__XXX

BO_ 2566888503 AVM_AVMCP: 124 AVM

BO_ 2566888759 AVM_AVMVER: 8 AVM
 SG_ AvmVerYear : 32|16@1+ (16,0) [0|0] "" Vector__XXX
 SG_ AvmVerMonth : 24|8@1+ (8,0) [0|0] "" Vector__XXX
 SG_ AvmVerDate : 16|8@1+ (8,0) [0|0] "" Vector__XXX
 SG_ AvmVer : 0|16@1+ (16,0) [0|0] "" Vector__XXX

BO_ 2566889388 CHMSL_CHMSLI: 8 CHMSL

BO_ 2566889512 GP_GPCMD: 8 GP
 SG_ RvsWarnSt : 42|2@1+ (1,0) [0|3] "" Vector__XXX
 SG_ MirrorHtOprtgSig : 40|2@1+ (1,0) [0|3] "" Vector__XXX
 SG_ EvMdCmd : 38|2@1+ (1,0) [0|3] "" Vector__XXX
 SG_ ObjectSsChmsl : 37|1@1+ (1,0) [0|1] "" Vector__XXX
 SG_ KeylessCrankEnbSt : 36|1@1+ (1,0) [0|1] "" Vector__XXX
 SG_ DaacmdSt : 35|1@1+ (1,0) [0|1] "" Vector__XXX
 SG_ QuickCoolMdSt : 34|1@1+ (1,0) [0|1] "" Vector__XXX
 SG_ DzAstMdSt : 33|1@1+ (1,0) [0|1] "" Vector__XXX
 SG_ KeyPadPri : 32|1@1+ (1,0) [0|1] "" Vector__XXX
 SG_ RpmCmdbyJD : 16|16@1+ (0.001,0) [0|64.255] "" Vector__XXX
 SG_ TractionMdSt : 12|4@1+ (1,0) [0|15] "" Vector__XXX
 SG_ ExternalSoundCmd : 11|1@1+ (1,0) [0|1] "" Vector__XXX
 SG_ EgLckSt : 10|1@1+ (1,0) [0|1] "" Vector__XXX
 SG_ JduseStforRpm : 9|1@1+ (1,0) [0|1] "" Vector__XXX
 SG_ AutoIdleMdSt : 8|1@1+ (1,0) [0|1] "" Vector__XXX
 SG_ WrkMdSt : 4|4@1+ (1,0) [0|15] "" Vector__XXX
 SG_ PwrMdSt : 0|4@1+ (1,0) [0|15] "" Vector__XXX

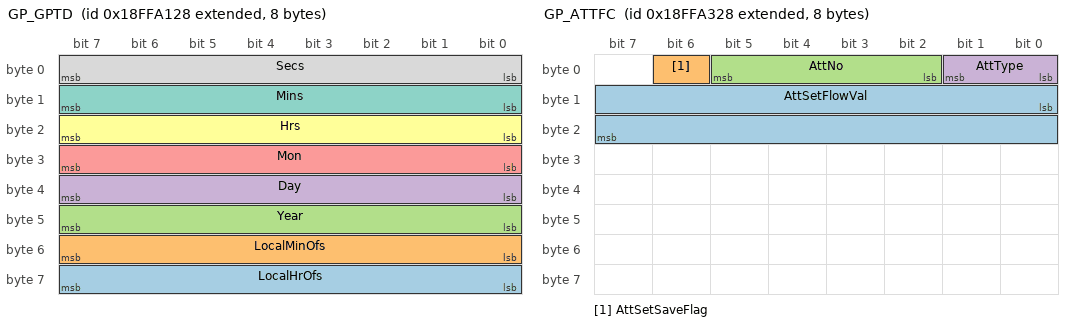
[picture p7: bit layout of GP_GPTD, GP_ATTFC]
BO_ 2566889768 GP_GPTD: 8 GP
 SG_ LocalHrOfs : 56|8@1- (1,-125) [-125|125] "" Vector__XXX
 SG_ LocalMinOfs : 48|8@1- (1,-125) [-125|125] "" Vector__XXX
 SG_ Year : 40|8@1+ (1,1985) [1985|2235] "" Vector__XXX
 SG_ Day : 32|8@1+ (0.25,0) [0|62.5] "" Vector__XXX
 SG_ Mon : 24|8@1+ (1,0) [0|250] "" Vector__XXX
 SG_ Hrs : 16|8@1+ (1,0) [0|250] "" Vector__XXX
 SG_ Mins : 8|8@1+ (1,0) [0|250] "" Vector__XXX
 SG_ Secs : 0|8@1+ (0.25,0) [0|62.5] "" Vector__XXX

BO_ 2566890024 GP_SVGP: 21 GP
 SG_ AvmSwVer : 136|32@1+ (1,0) [0|4294967295] "ASCII" Vector__XXX
 SG_ AvmSwVerYear : 128|8@1+ (1,1985) [1985|2235] "" Vector__XXX
 SG_ AvmSwVerDay : 120|8@1+ (0.25,0) [0|62.5] "" Vector__XXX
 SG_ AvmSwVerMon : 112|8@1+ (1,0) [0|250] "" Vector__XXX
 SG_ GpOsSwVer : 80|32@1+ (1,0) [0|4294967295] "ASCII" Vector__XXX
 SG_ GpOsSwVerYear : 72|8@1+ (1,1985) [1985|2235] "" Vector__XXX
 SG_ GpOsSwVerDay : 64|8@1+ (0.25,0) [0|62.5] "" Vector__XXX
 SG_ GpOsSwVerMon : 56|8@1+ (1,0) [0|250] "" Vector__XXX
 SG_ GpAppSwVer : 24|32@1+ (1,0) [0|4294967295] "ASCII" Vector__XXX
 SG_ GpAppSwVerYear : 16|8@1+ (1,1985) [1985|2235] "" Vector__XXX
 SG_ GpAppSwVerDay : 8|8@1+ (0.25,0) [0|62.5] "" Vector__XXX
 SG_ GpAppSwVerMon : 0|8@1+ (1,0) [0|250] "" Vector__XXX

BO_ 2566890280 GP_ATTFC: 8 GP
 SG_ AttSetFlowVal : 8|16@1+ (1,0) [0|65000] "lpm" Vector__XXX
 SG_ AttSetSaveFlag : 6|1@1+ (1,0) [0|1] "" Vector__XXX
 SG_ AttNo : 2|4@1+ (1,0) [0|15] "" Vector__XXX
 SG_ AttType : 0|2@1+ (1,0) [0|3] "" Vector__XXX

BO_ 2566890536 GP_MG2DBC: 8 GP
 SG_ MgSoundGudStep : 3|4@1+ (1,0) [0|15] "" Vector__XXX
 SG_ AlmSt : 0|3@1+ (1,0) [0|7] "" Vector__XXX

BO_ 2566890561 GW_MG2DBC: 11 GW
 SG_ MgSoundGudStep : 3|4@1+ (1,0) [0|15] "" Vector__XXX
 SG_ AlmSt : 0|3@1+ (1,0) [0|7] "" Vector__XXX

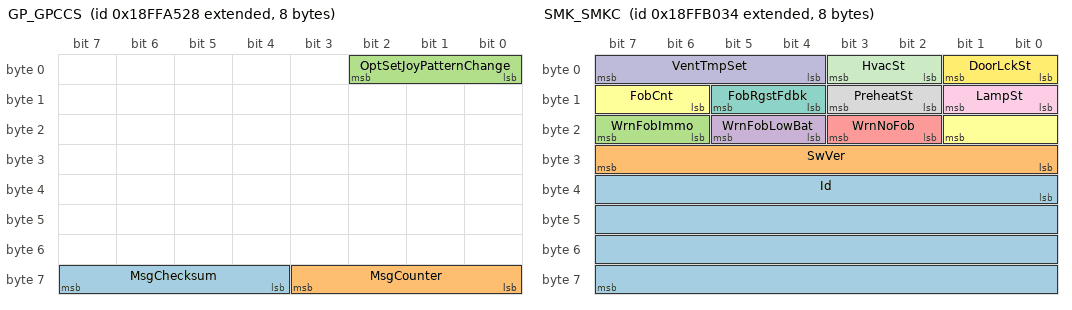
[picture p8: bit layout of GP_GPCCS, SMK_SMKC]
BO_ 2566890792 GP_GPCCS: 8 GP
 SG_ MsgChecksum : 60|4@1+ (1,0) [0|15] "count" Vector__XXX
 SG_ MsgCounter : 56|4@1+ (1,0) [0|15] "count" Vector__XXX
 SG_ OptSetJoyPatternChange : 0|3@1+ (1,0) [0|7] "" Vector__XXX

BO_ 2566891041 MCU_ZFIMP: 8 MCU

BO_ 2566891688 CTC_CAV: 8 CTC

BO_ 2566892072 GP_DCAP: 8 GP
 SG_ ReqCallIndex : 48|4@1+ (1,0) [0|15] "" Vector__XXX
 SG_ PairingReq : 46|2@1+ (1,0) [0|3] "" Vector__XXX
 SG_ HangUpBtn : 44|2@1+ (1,0) [0|3] "" Vector__XXX
 SG_ DabSel : 42|2@1+ (1,0) [0|3] "" Vector__XXX
 SG_ MdSel : 40|2@1+ (1,0) [0|3] "" Vector__XXX
 SG_ AdoVolDownSel : 38|2@1+ (1,0) [0|3] "" Vector__XXX
 SG_ AdoVolUpSel : 36|2@1+ (1,0) [0|3] "" Vector__XXX
 SG_ BandSel : 34|2@1+ (1,0) [0|3] "" Vector__XXX
 SG_ TalkBtn : 32|2@1+ (1,0) [0|3] "" Vector__XXX
 SG_ AdoTuneDownSel : 30|2@1+ (1,0) [0|3] "" Vector__XXX
 SG_ AdoCallListPopupSt : 28|2@1+ (1,0) [0|3] "" Vector__XXX
 SG_ AdoMenuSel : 26|2@1+ (1,0) [0|3] "" Vector__XXX
 SG_ AdoPowerSel : 24|2@1+ (1,0) [0|3] "" Vector__XXX
 SG_ AdoP5Sel : 22|2@1+ (1,0) [0|3] "" Vector__XXX
 SG_ AdoP6Sel : 20|2@1+ (1,0) [0|3] "" Vector__XXX
 SG_ AdoTuneSel : 18|2@1+ (1,0) [0|3] "" Vector__XXX
 SG_ AdoTuneUpSel : 16|2@1+ (1,0) [0|3] "" Vector__XXX
 SG_ AdoP1Sel : 14|2@1+ (1,0) [0|3] "" Vector__XXX
 SG_ AdoP2Sel : 12|2@1+ (1,0) [0|3] "" Vector__XXX
 SG_ AdoP3Sel : 10|2@1+ (1,0) [0|3] "" Vector__XXX
 SG_ AdoP4Sel : 8|2@1+ (1,0) [0|3] "" Vector__XXX
 SG_ AdoAmSel : 6|2@1+ (1,0) [0|3] "" Vector__XXX
 SG_ AdoFmSel : 4|2@1+ (1,0) [0|3] "" Vector__XXX
 SG_ AdoUsbSel : 2|2@1+ (1,0) [0|3] "" Vector__XXX
 SG_ AdoAuxSel : 0|2@1+ (1,0) [0|3] "" Vector__XXX

BO_ 2566892448 Audio_APLGP: 1785 Audio
 SG_ PhoneBookListText : 0|64@1+ (1,0) [0|0] "ASCII-VN" Vector__XXX

BO_ 2566892704 Audio_ALITGP: 1785 Audio
 SG_ LargeIndexText : 0|64@1+ (1,0) [0|0] "ASCII-VN" Vector__XXX

BO_ 2566892960 Audio_ADLSGP: 1785 Audio
 SG_ DabDlsMsg : 0|64@1+ (1,0) [0|0] "ASCII-VN" Vector__XXX

BO_ 2566893216 Audio_AICTGP: 1785 Audio
 SG_ IncomingCallText : 0|64@1+ (1,0) [0|0] "ASCII-VN" Vector__XXX

BO_ 2566893472 Audio_ATG: 1785 Audio

BO_ 2566893620 SMK_SMKC: 8 SMK
 SG_ Id : 32|32@1+ (1,0) [0|999999999] "" Vector__XXX
 SG_ SwVer : 24|8@1+ (0.01,0) [0|255] "Ver" Vector__XXX
 SG_ WrnFobImmo : 22|2@1+ (1,0) [0|3] "" Vector__XXX
 SG_ WrnFobLowBat : 20|2@1+ (1,0) [0|3] "" Vector__XXX
 SG_ WrnNoFob : 18|2@1+ (1,0) [0|3] "" Vector__XXX
 SG_ FobCnt : 14|4@1+ (1,0) [0|15] "count" Vector__XXX
 SG_ FobRgstFdbk : 12|2@1+ (1,0) [0|3] "" Vector__XXX
 SG_ PreheatSt : 10|2@1+ (1,0) [0|3] "" Vector__XXX
 SG_ LampSt : 8|2@1+ (1,0) [0|3] "" Vector__XXX
 SG_ VentTmpSet : 4|4@1+ (1,17) [17|31] "celsius" Vector__XXX
 SG_ HvacSt : 2|2@1+ (1,0) [0|3] "" Vector__XXX
 SG_ DoorLckSt : 0|2@1+ (1,0) [0|3] "" Vector__XXX

BO_ 2566893876 SMK_SMKFOB: 8 SMK

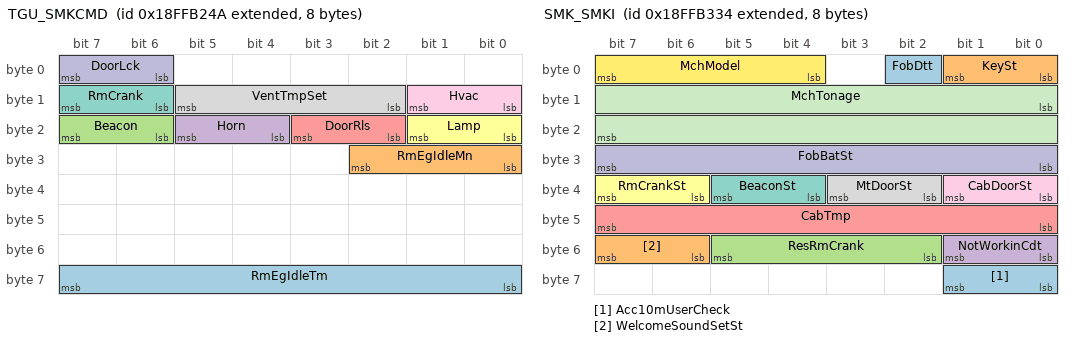
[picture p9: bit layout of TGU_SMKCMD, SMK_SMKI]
BO_ 2566894154 TGU_SMKCMD: 8 TGU
 SG_ RmEgIdleTm : 56|8@1+ (1,0) [0|250] "minutes" Vector__XXX
 SG_ RmEgIdleMn : 24|3@1+ (1,0) [0|7] "" Vector__XXX
 SG_ Beacon : 22|2@1+ (1,0) [0|3] "" Vector__XXX
 SG_ Horn : 20|2@1+ (1,0) [0|3] "" Vector__XXX
 SG_ DoorRls : 18|2@1+ (1,0) [0|3] "" Vector__XXX
 SG_ Lamp : 16|2@1+ (1,0) [0|3] "" Vector__XXX
 SG_ RmCrank : 14|2@1+ (1,0) [0|3] "" Vector__XXX
 SG_ VentTmpSet : 10|4@1+ (1,17) [17|31] "celsius" Vector__XXX
 SG_ Hvac : 8|2@1+ (1,0) [0|3] "" Vector__XXX
 SG_ DoorLck : 6|2@1+ (1,0) [0|3] "" Vector__XXX

BO_ 2566894388 SMK_SMKI: 8 SMK
 SG_ Acc10mUserCheck : 56|2@1+ (1,0) [0|3] "" Vector__XXX
 SG_ WelcomeSoundSetSt : 54|2@1+ (1,0) [0|3] "" Vector__XXX
 SG_ ResRmCrank : 50|4@1+ (1,0) [0|15] "" Vector__XXX
 SG_ NotWorkinCdt : 48|2@1+ (1,0) [0|3] "" Vector__XXX
 SG_ CabTmp : 40|8@1- (0.5,-40) [-40|86] "celsius" Vector__XXX
 SG_ RmCrankSt : 38|2@1+ (1,0) [0|3] "" Vector__XXX
 SG_ BeaconSt : 36|2@1+ (1,0) [0|3] "" Vector__XXX
 SG_ MtDoorSt : 34|2@1+ (1,0) [0|3] "" Vector__XXX
 SG_ CabDoorSt : 32|2@1+ (1,0) [0|3] "" Vector__XXX
 SG_ FobBatSt : 24|8@1+ (0.1,0) [0|25] "V" Vector__XXX
 SG_ MchTonage : 8|16@1+ (0.1,0) [0|6502.3] "" Vector__XXX
 SG_ MchModel : 4|4@1+ (1,0) [0|15] "" Vector__XXX
 SG_ FobDtt : 2|1@1+ (1,0) [0|1] "" Vector__XXX
 SG_ KeySt : 0|2@1+ (1,0) [0|3] "" Vector__XXX

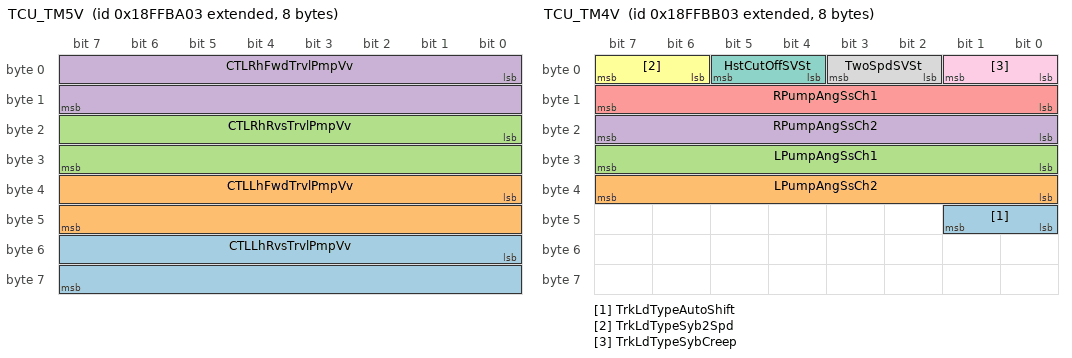
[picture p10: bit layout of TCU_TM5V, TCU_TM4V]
BO_ 2566896131 TCU_TM5V: 8 TCU
 SG_ CTLLhRvsTrvlPmpVv : 48|16@1+ (1,0) [0|64255] "mA" Vector__XXX
 SG_ CTLLhFwdTrvlPmpVv : 32|16@1+ (1,0) [0|64255] "mA" Vector__XXX
 SG_ CTLRhRvsTrvlPmpVv : 16|16@1+ (1,0) [0|64255] "mA" Vector__XXX
 SG_ CTLRhFwdTrvlPmpVv : 0|16@1+ (1,0) [0|64255] "mA" Vector__XXX

BO_ 2566896387 TCU_TM4V: 8 TCU
 SG_ TrkLdTypeAutoShift : 40|2@1+ (1,0) [0|3] "" Vector__XXX
 SG_ LPumpAngSsCh2 : 32|8@1+ (0.025,0) [0|6.25] "V" Vector__XXX
 SG_ LPumpAngSsCh1 : 24|8@1+ (0.025,0) [0|6.25] "V" Vector__XXX
 SG_ RPumpAngSsCh2 : 16|8@1+ (0.025,0) [0|6.25] "V" Vector__XXX
 SG_ RPumpAngSsCh1 : 8|8@1+ (0.025,0) [0|6.25] "V" Vector__XXX
 SG_ TrkLdTypeSyb2Spd : 6|2@1+ (1,0) [0|3] "" Vector__XXX
 SG_ HstCutOffSVSt : 4|2@1+ (1,0) [0|3] "" Vector__XXX
 SG_ TwoSpdSVSt : 2|2@1+ (1,0) [0|3] "" Vector__XXX
 SG_ TrkLdTypeSybCreep : 0|2@1+ (1,0) [0|3] "" Vector__XXX

BO_ 2566896643 TCU_TCUHG: 17 TCU
 SG_ TrvlSpdPreset4RvsExtd : 128|8@1+ (1,0) [0|250] "" Vector__XXX
 SG_ TrvlSpdPreset4FwdExtd : 120|8@1+ (1,0) [0|250] "" Vector__XXX
 SG_ TrvlSpdPreset3RvsExtd : 112|8@1+ (1,0) [0|250] "" Vector__XXX
 SG_ TrvlSpdPreset3FwdExtd : 104|8@1+ (1,0) [0|250] "" Vector__XXX
 SG_ TrvlSpdPreset2RvsExtd : 96|8@1+ (1,0) [0|250] "" Vector__XXX
 SG_ TrvlSpdPreset2FwdExtd : 88|8@1+ (1,0) [0|250] "" Vector__XXX
 SG_ TrvlSpdPreset1RvsExtd : 80|8@1+ (1,0) [0|250] "" Vector__XXX
 SG_ TrvlSpdPreset1FwdExtd : 72|8@1+ (1,0) [0|250] "" Vector__XXX
 SG_ JoyStrSsAdj : 66|4@1+ (1,0) [0|15] "" Vector__XXX
 SG_ TrvlSpdPrmtCor : 56|8@1+ (1,0) [0|250] "" Vector__XXX
 SG_ SetMaxSpdLimit : 48|8@1+ (1,0) [0|250] "" Vector__XXX
 SG_ SetStrDriftCompensation : 43|5@1+ (1,0) [0|31] "" Vector__XXX
 SG_ SetCreepMaxSpd : 38|5@1+ (1,0) [0|31] "" Vector__XXX
 SG_ SetJoyTrvlRLTrk : 36|2@1+ (1,0) [0|3] "" Vector__XXX
 SG_ TrvlSpdPreset4Rvs : 32|4@1+ (1,0) [0|15] "" Vector__XXX
 SG_ TrvlSpdPreset4Fwd : 28|4@1+ (1,0) [0|15] "" Vector__XXX
 SG_ TrvlSpdPreset3Rvs : 24|4@1+ (1,0) [0|15] "" Vector__XXX
 SG_ TrvlSpdPreset3Fwd : 20|4@1+ (1,0) [0|15] "" Vector__XXX
 SG_ TrvlSpdPreset2Rvs : 16|4@1+ (1,0) [0|15] "" Vector__XXX
 SG_ TrvlSpdPreset2Fwd : 12|4@1+ (1,0) [0|15] "" Vector__XXX
 SG_ TrvlSpdPreset1Rvs : 8|4@1+ (1,0) [0|15] "" Vector__XXX
 SG_ TrvlSpdPreset1Fwd : 4|4@1+ (1,0) [0|15] "" Vector__XXX
 SG_ TrvlSpdSet : 1|3@1+ (1,0) [0|7] "" Vector__XXX
 SG_ BrkPdlDecel : 0|1@1+ (1,0) [0|1] "" Vector__XXX

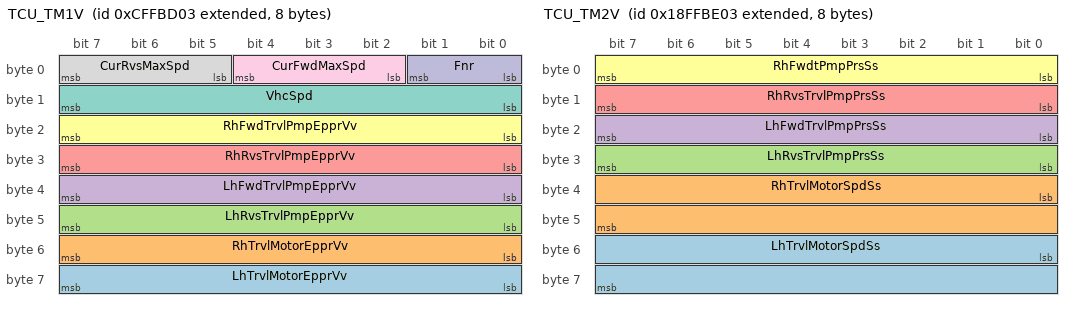
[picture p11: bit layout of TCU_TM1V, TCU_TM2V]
BO_ 2365570307 TCU_TM1V: 8 TCU
 SG_ LhTrvlMotorEpprVv : 56|8@1+ (5,0) [0|1250] "mA" Vector__XXX
 SG_ RhTrvlMotorEpprVv : 48|8@1+ (5,0) [0|1250] "mA" Vector__XXX
 SG_ LhRvsTrvlPmpEpprVv : 40|8@1+ (5,0) [0|1250] "mA" Vector__XXX
 SG_ LhFwdTrvlPmpEpprVv : 32|8@1+ (5,0) [0|1250] "mA" Vector__XXX
 SG_ RhRvsTrvlPmpEpprVv : 24|8@1+ (5,0) [0|1250] "mA" Vector__XXX
 SG_ RhFwdTrvlPmpEpprVv : 16|8@1+ (5,0) [0|1250] "mA" Vector__XXX
 SG_ VhcSpd : 8|8@1+ (0.125,0) [0|31.25] "kmph" Vector__XXX
 SG_ CurRvsMaxSpd : 5|3@1+ (1,0) [0|7] "" Vector__XXX
 SG_ CurFwdMaxSpd : 2|3@1+ (1,0) [0|7] "" Vector__XXX
 SG_ Fnr : 0|2@1+ (1,0) [0|3] "" Vector__XXX

BO_ 2566897155 TCU_TM2V: 8 TCU
 SG_ LhTrvlMotorSpdSs : 48|16@1+ (0.0078125,0) [0|501.9921875] "Hz" Vector__XXX
 SG_ RhTrvlMotorSpdSs : 32|16@1+ (0.0078125,0) [0|501.9921875] "Hz" Vector__XXX
 SG_ LhRvsTrvlPmpPrsSs : 24|8@1+ (0.025,0) [0|6.25] "V" Vector__XXX
 SG_ LhFwdTrvlPmpPrsSs : 16|8@1+ (0.025,0) [0|6.25] "V" Vector__XXX
 SG_ RhRvsTrvlPmpPrsSs : 8|8@1+ (0.025,0) [0|6.25] "V" Vector__XXX
 SG_ RhFwdtPmpPrsSs : 0|8@1+ (0.025,0) [0|6.25] "V" Vector__XXX

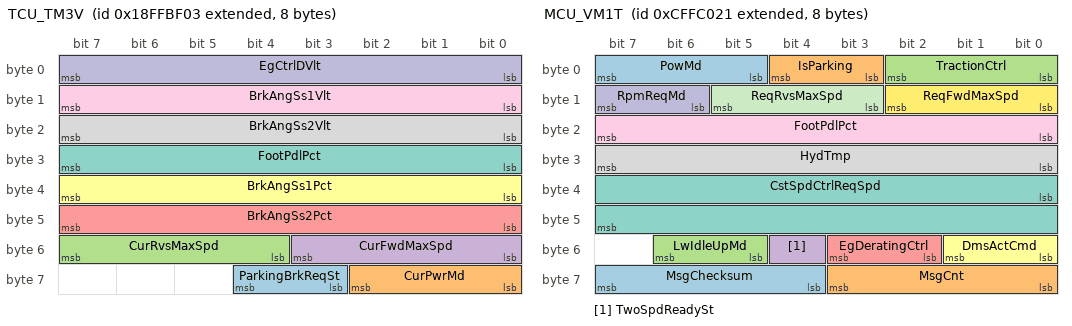
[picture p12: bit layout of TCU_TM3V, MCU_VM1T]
BO_ 2566897411 TCU_TM3V: 8 TCU
 SG_ ParkingBrkReqSt : 59|2@1+ (1,0) [0|3] "" Vector__XXX
 SG_ CurPwrMd : 56|3@1+ (1,0) [0|7] "" Vector__XXX
 SG_ CurRvsMaxSpd : 52|4@1+ (1,0) [0|15] "" Vector__XXX
 SG_ CurFwdMaxSpd : 48|4@1+ (1,0) [0|15] "" Vector__XXX
 SG_ BrkAngSs2Pct : 40|8@1+ (0.4,0) [0|100] "percent" Vector__XXX
 SG_ BrkAngSs1Pct : 32|8@1+ (0.4,0) [0|100] "percent" Vector__XXX
 SG_ FootPdlPct : 24|8@1+ (0.4,0) [0|100] "percent" Vector__XXX
 SG_ BrkAngSs2Vlt : 16|8@1+ (0.025,0) [0|6.25] "V" Vector__XXX
 SG_ BrkAngSs1Vlt : 8|8@1+ (0.025,0) [0|6.25] "V" Vector__XXX
 SG_ EgCtrlDVlt : 0|8@1+ (0.025,0) [0|6.25] "V" Vector__XXX

BO_ 2365571105 MCU_VM1T: 8 MCU
 SG_ MsgChecksum : 60|4@1+ (1,0) [0|15] "" Vector__XXX
 SG_ MsgCnt : 56|4@1+ (1,0) [0|15] "" Vector__XXX
 SG_ LwIdleUpMd : 53|2@1+ (1,0) [0|3] "" Vector__XXX
 SG_ TwoSpdReadySt : 52|1@1+ (1,0) [0|1] "" Vector__XXX
 SG_ EgDeratingCtrl : 50|2@1+ (1,0) [0|3] "" Vector__XXX
 SG_ DmsActCmd : 48|2@1+ (1,0) [0|3] "" Vector__XXX
 SG_ CstSpdCtrlReqSpd : 32|16@1+ (0.125,0) [0|8031.875] "rpm" Vector__XXX
 SG_ HydTmp : 24|8@1- (1,-40) [-40|210] "celsius" Vector__XXX
 SG_ FootPdlPct : 16|8@1+ (0.4,0) [0|100] "percent" Vector__XXX
 SG_ RpmReqMd : 14|2@1+ (1,0) [0|3] "" Vector__XXX
 SG_ ReqRvsMaxSpd : 11|3@1+ (1,0) [0|7] "" Vector__XXX
 SG_ ReqFwdMaxSpd : 8|3@1+ (1,0) [0|7] "" Vector__XXX
 SG_ PowMd : 5|3@1+ (1,0) [0|7] "" Vector__XXX
 SG_ IsParking : 3|2@1+ (1,0) [0|3] "" Vector__XXX
 SG_ TractionCtrl : 0|3@1+ (1,0) [0|7] "" Vector__XXX

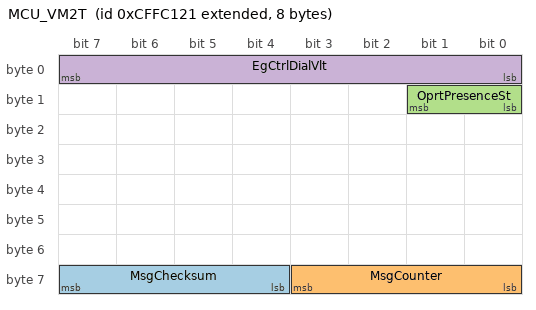
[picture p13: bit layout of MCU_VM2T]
BO_ 2365571361 MCU_VM2T: 8 MCU
 SG_ MsgChecksum : 60|4@1+ (1,0) [0|15] "" Vector__XXX
 SG_ MsgCounter : 56|4@1+ (1,0) [0|15] "" Vector__XXX
 SG_ OprtPresenceSt : 8|2@1+ (1,0) [0|3] "" Vector__XXX
 SG_ EgCtrlDialVlt : 0|8@1+ (0.02044,0) [0|5.11] "" Vector__XXX

BO_ 2365572608 ECU_VGTPosCmd: 8 ECU
 SG_ VgtCmdSt : 16|8@1+ (1,0) [0|26] "" Vector__XXX
 SG_ VgtNzPos : 0|16@1+ (0.1,0) [0|100] "" Vector__XXX

BO_ 2566901763 TCU_HSDI: 250 TCU
 SG_ RandomVal : 0|16@1+ (1,0) [0|65535] "" Vector__XXX

BO_ 2566901793 MCU_HSDI: 250 MCU
 SG_ RandomVal : 0|16@1+ (1,0) [0|65535] "" Vector__XXX

BO_ 2566902049 MCU_FSDI: 131 MCU
 SG_ DacTiltAutoMdSel : 1044|4@1+ (1,0) [0|15] "" Vector__XXX
 SG_ DacLiftAutoMdSel : 1040|4@1+ (1,0) [0|15] "" Vector__XXX
 SG_ BladeLoadTgSet : 1032|8@1+ (1,0) [0|255] "" Vector__XXX
 SG_ OverturnWarn : 1028|2@1+ (1,0) [0|3] "" Vector__XXX
 SG_ EmcvBckSsSet : 1024|4@1+ (1,0) [0|15] "" Vector__XXX
 SG_ MaxFlwRateofElecPwrStrSet : 1016|8@1+ (1,0) [0|255] "" Vector__XXX
 SG_ EmcvArmSsSet : 1012|4@1+ (1,0) [0|15] "" Vector__XXX
 SG_ ElecPwrStrSsSet : 1008|4@1+ (1,0) [0|15] "" Vector__XXX
 SG_ PriLogicValve : 1006|2@1+ (1,0) [0|3] "" Vector__XXX
 SG_ AdvancedWgh : 1004|2@1+ (1,0) [0|3] "" Vector__XXX
 SG_ HydAux2 : 1002|2@1+ (1,0) [0|3] "" Vector__XXX
 SG_ HhSpdDrvMd : 1000|2@1+ (1,0) [0|3] "" Vector__XXX
 SG_ SocChgLmt : 992|8@1+ (1,0) [0|255] "" Vector__XXX
 SG_ HeavyAtt : 988|4@1+ (1,0) [0|15] "" Vector__XXX
 SG_ AutoReturntoDig : 986|2@1+ (1,0) [0|3] "" Vector__XXX
 SG_ ExtraOilCool : 984|2@1+ (1,0) [0|3] "" Vector__XXX
 SG_ ArmDumpSplCmdOffset : 980|4@1+ (1,-5) [-5|5] "" Vector__XXX
 SG_ ArmCrowdSplCmdOffset : 976|4@1+ (1,-5) [-5|5] "" Vector__XXX
 SG_ BckDumpSplCmdOffset : 972|4@1+ (1,-5) [-5|5] "" Vector__XXX
 SG_ BckCrowdSplCmdOffset : 968|4@1+ (1,-5) [-5|5] "" Vector__XXX
 SG_ BoomDnSplCmdOffset : 964|4@1+ (1,-5) [-5|5] "" Vector__XXX
 SG_ BoomUpSplCmdOffset : 960|4@1+ (1,-5) [-5|5] "" Vector__XXX
 SG_ NonStdTireWhlSizeMn : 944|16@1+ (1,0) [0|64255] "" Vector__XXX
 SG_ StdTireSizeSel : 936|8@1+ (1,0) [0|255] "" Vector__XXX
 SG_ TireMaker : 932|4@1+ (1,0) [0|15] "" Vector__XXX
 SG_ FourthCstFlwStep : 928|4@1+ (1,0) [0|15] "" Vector__XXX
 SG_ ParallelLiftSsSet : 926|2@1+ (1,0) [0|3] "" Vector__XXX
 SG_ RlsofFlwRstrforCombiOpr : 924|2@1+ (1,0) [0|3] "" Vector__XXX
 SG_ RedPrsRmv : 918|2@1+ (1,0) [0|3] "" Vector__XXX
 SG_ GreenBeacon : 916|2@1+ (1,0) [0|3] "" Vector__XXX
 SG_ LockValve : 906|2@1+ (1,0) [0|3] "" Vector__XXX
 SG_ TiltRttExtra2Ivt : 900|2@1+ (1,0) [0|3] "" Vector__XXX
 SG_ TiltRttExtra1Ivt : 898|2@1+ (1,0) [0|3] "" Vector__XXX
 SG_ TiltRttIvt : 896|2@1+ (1,0) [0|3] "" Vector__XXX
 SG_ TiltRttTiltIvt : 894|2@1+ (1,0) [0|3] "" Vector__XXX
 SG_ AutoDig : 892|2@1+ (1,0) [0|3] "" Vector__XXX
 SG_ ShtShiftAst : 890|2@1+ (1,0) [0|3] "" Vector__XXX
 SG_ OptShtShiftAst : 888|2@1+ (1,0) [0|3] "" Vector__XXX
 SG_ Actjoy : 884|3@1+ (1,0) [0|7] "" Vector__XXX
 SG_ MultiFncBtnSelforWld : 880|4@1+ (1,0) [0|15] "" Vector__XXX
 SG_ KickDnShiftMd : 878|2@1+ (1,0) [0|3] "" Vector__XXX
 SG_ BckShake : 876|2@1+ (1,0) [0|3] "" Vector__XXX
 SG_ ElecExcvCableType : 874|2@1+ (1,0) [0|3] "" Vector__XXX
 SG_ EStop : 872|2@1+ (1,0) [0|3] "" Vector__XXX
 SG_ LineRedPrsRmvSet : 870|2@1+ (1,0) [0|3] "" Vector__XXX
 SG_ OutTrgFR : 868|2@1+ (1,0) [0|3] "" Vector__XXX
 SG_ OutTrgFL : 866|2@1+ (1,0) [0|3] "" Vector__XXX
 SG_ RrDz : 864|2@1+ (1,0) [0|3] "" Vector__XXX
 SG_ FrDz : 862|2@1+ (1,0) [0|3] "" Vector__XXX
 SG_ RrDzorOutTrg : 859|3@1+ (1,0) [0|7] "" Vector__XXX
 SG_ FrDzorOutTrg : 856|3@1+ (1,0) [0|7] "" Vector__XXX
 SG_ APMdPwrRngMax : 852|4@1+ (1,0) [0|15] "" Vector__XXX
 SG_ APMdPwrRngMin : 848|4@1+ (1,0) [0|15] "" Vector__XXX
 SG_ AgsIntervalTm : 832|16@1+ (0.1,0) [0|6425.5] "" Vector__XXX
 SG_ AgsOprTm : 824|8@1+ (1,0) [0|250] "" Vector__XXX
 SG_ RrAxleTirePrsTh : 816|8@1+ (4,0) [0|1000] "" Vector__XXX
 SG_ FrAxleTirePrsTh : 808|8@1+ (4,0) [0|1000] "" Vector__XXX
 SG_ OutTrgRR : 806|2@1+ (1,0) [0|3] "" Vector__XXX
 SG_ OutTrgRL : 804|2@1+ (1,0) [0|3] "" Vector__XXX
 SG_ CTLCanopy : 802|2@1+ (1,0) [0|3] "" Vector__XXX
 SG_ Radar : 800|2@1+ (1,0) [0|3] "" Vector__XXX
 SG_ Savm : 798|2@1+ (1,0) [0|3] "" Vector__XXX
 SG_ FineSwg : 796|2@1+ (1,0) [0|3] "" Vector__XXX
 SG_ HhlandOpt : 794|2@1+ (1,0) [0|3] "" Vector__XXX
 SG_ SmartAssist : 792|2@1+ (1,0) [0|3] "" Vector__XXX
 SG_ PhmPremium : 790|2@1+ (1,0) [0|3] "" Vector__XXX
 SG_ PhmBasic : 788|2@1+ (1,0) [0|3] "" Vector__XXX
 SG_ RrSspnAutoMd : 786|2@1+ (1,0) [0|3] "" Vector__XXX
 SG_ FrSspnMd : 784|2@1+ (1,0) [0|3] "" Vector__XXX
 SG_ AdtMaxCriterionWghVal : 768|16@1+ (2,0) [0|128510] "" Vector__XXX
 SG_ SetOwdActn : 766|2@1+ (1,0) [0|3] "" Vector__XXX
 SG_ RvsFanDurationTmData : 760|6@1+ (1,0) [0|63] "" Vector__XXX
 SG_ OptSetMaterialHandlerFr : 756|3@1+ (1,0) [0|7] "" Vector__XXX
 SG_ LHJoyStrSet : 755|1@1+ (1,0) [0|1] "" Vector__XXX
 SG_ AutoHold : 753|2@1+ (1,0) [0|3] "" Vector__XXX
 SG_ SetStickStr : 752|1@1+ (1,0) [0|1] "" Vector__XXX
 SG_ OptSetCdsRvsFanAutoPrd : 744|8@1+ (1,0) [0|250] "minutes" Vector__XXX
 SG_ OptSetTrailer : 742|1@1+ (1,0) [0|1] "" Vector__XXX
 SG_ OptSetEscortWrkLmp : 741|1@1+ (1,0) [0|1] "" Vector__XXX
 SG_ OptSetCdsRvsFanMd : 732|1@1+ (1,0) [0|1] "" Vector__XXX
 SG_ OptSetRttDir : 731|1@1+ (1,0) [0|1] "" Vector__XXX
 SG_ OptSetAdvLv : 730|1@1+ (1,0) [0|1] "" Vector__XXX
 SG_ OptSetGndSaw : 729|1@1+ (1,0) [0|1] "" Vector__XXX
 SG_ OptSetTpms : 728|1@1+ (1,0) [0|1] "" Vector__XXX
 SG_ OptSetAutoBrkrSens : 720|8@1+ (1,0) [0|255] "" Vector__XXX
 SG_ OptSetAntiBlankFire : 719|1@1+ (1,0) [0|1] "" Vector__XXX
 SG_ OptSetJoyBoom : 717|2@1+ (1,0) [0|3] "" Vector__XXX
 SG_ OptSetJoyTilt : 715|2@1+ (1,0) [0|3] "" Vector__XXX
 SG_ OptSetCoolFanType : 712|3@1+ (1,0) [0|7] "" Vector__XXX
 SG_ FourthCstFlwSet : 711|1@1+ (1,0) [0|1] "" Vector__XXX
 SG_ OptParallelLiftActn : 709|2@1+ (1,0) [0|3] "" Vector__XXX
 SG_ OptSetHhFw : 708|1@1+ (1,0) [0|1] "" Vector__XXX
 SG_ OptSet3DMgMc3rd : 704|4@1+ (1,0) [0|15] "" Vector__XXX
 SG_ OptSetRrCabLmp : 703|1@1+ (1,0) [0|1] "" Vector__XXX
 SG_ OptSetDzMc : 700|3@1+ (1,0) [0|7] "" Vector__XXX
 SG_ OptSetTrqCvtLckUp : 699|1@1+ (1,0) [0|1] "" Vector__XXX
 SG_ OptSetTwThwDir : 698|1@1+ (1,0) [0|1] "" Vector__XXX
 SG_ OptSetOptPdlType2 : 696|2@1+ (1,0) [0|3] "" Vector__XXX
 SG_ OptSetMaxTrvlSpd : 688|8@1+ (1,0) [0|250] "kmph" Vector__XXX
 SG_ OptSetRollSlope : 672|16@1- (1,-125) [-125|125] "percent" Vector__XXX
 SG_ OptSetDaac : 671|1@1+ (1,0) [0|1] "" Vector__XXX
 SG_ OptSetRvsLmpFuncAct : 670|1@1+ (1,0) [0|1] "" Vector__XXX
 SG_ OptSetBladeAngSens : 668|2@1+ (1,0) [0|3] "" Vector__XXX
 SG_ OptSetRaiseDnSens : 666|2@1+ (1,0) [0|3] "" Vector__XXX
 SG_ OptSetBladeTiltSens : 664|2@1+ (1,0) [0|3] "" Vector__XXX
 SG_ OptSetPchSlope : 648|16@1- (0.01,-321.27) [-321.27|321.28] "percent" Vector__XXX
 SG_ OptSetMrrHt : 647|1@1+ (1,0) [0|1] "" Vector__XXX
 SG_ OptSetQckCoolMd : 646|1@1+ (1,0) [0|1] "" Vector__XXX
 SG_ RttOptSet : 644|2@1+ (1,0) [0|3] "" Vector__XXX
 SG_ OptSetTrvlStrgtPdl : 643|1@1+ (1,0) [0|1] "" Vector__XXX
 SG_ OptSetJoyType : 640|3@1+ (1,0) [0|7] "" Vector__XXX
 SG_ OptSetAttCtrl : 638|2@1+ (1,0) [0|3] "" Vector__XXX
 SG_ OptSetTiltRttType : 635|3@1+ (1,0) [0|7] "" Vector__XXX
 SG_ OptSetArtiBoom : 634|1@1+ (1,0) [0|1] "" Vector__XXX
 SG_ OptSetDzBlade : 633|1@1+ (1,0) [0|1] "" Vector__XXX
 SG_ OptSetHhLift : 632|1@1+ (1,0) [0|1] "" Vector__XXX
 SG_ OptSetJoyPtnChange : 629|3@1+ (1,0) [0|7] "" Vector__XXX
 SG_ OptSetTrqCvtLookUp : 628|1@1+ (1,0) [0|1] "" Vector__XXX
 SG_ OptSetDhlAuto : 627|1@1+ (1,0) [0|1] "" Vector__XXX
 SG_ OptSet3DMG : 626|1@1+ (1,0) [0|1] "" Vector__XXX
 SG_ OptSetTrvlSwgAlm : 624|2@1+ (1,0) [0|3] "" Vector__XXX
 SG_ OptSetLaserReceiver : 622|2@1+ (1,0) [0|3] "" Vector__XXX
 SG_ OptSetMgMc : 619|3@1+ (1,0) [0|7] "" Vector__XXX
 SG_ OptSetDKey : 616|2@1+ (1,0) [0|3] "" Vector__XXX
 SG_ WghWith3D : 614|2@1+ (1,0) [0|3] "" Vector__XXX
 SG_ OptSetWirelessChg : 612|2@1+ (1,0) [0|3] "" Vector__XXX
 SG_ OptSetAgs : 610|2@1+ (1,0) [0|3] "" Vector__XXX
 SG_ OptSetCamLmp : 608|2@1+ (1,0) [0|3] "" Vector__XXX
 SG_ OptSetWiperType : 601|3@1+ (1,0) [0|7] "" Vector__XXX
 SG_ OptSetPrsCtrl : 600|1@1+ (1,0) [0|1] "" Vector__XXX
 SG_ OptSetRollOvr : 599|1@1+ (1,0) [0|1] "" Vector__XXX
 SG_ OptSet4WhlStr : 598|1@1+ (1,0) [0|1] "" Vector__XXX
 SG_ OptSetSpool4 : 597|1@1+ (1,0) [0|1] "" Vector__XXX
 SG_ ThirdCstFlwSet : 596|1@1+ (1,0) [0|1] "" Vector__XXX
 SG_ ThirdCstFlwStep : 592|4@1+ (1,0) [0|15] "" Vector__XXX
 SG_ OptSetLisRvsOprSpd : 584|8@1+ (1,0) [0|250] "kmph" Vector__XXX
 SG_ OptSetFrCabLmp : 583|1@1+ (1,0) [0|1] "" Vector__XXX
 SG_ OptSetOutRr : 582|1@1+ (1,0) [0|1] "" Vector__XXX
 SG_ OptSetOutRlRrDz : 581|1@1+ (1,0) [0|1] "" Vector__XXX
 SG_ OptSetOutFr : 580|1@1+ (1,0) [0|1] "" Vector__XXX
 SG_ OptSetOutFlFrDz : 579|1@1+ (1,0) [0|1] "" Vector__XXX
 SG_ OptSetJoyStr : 578|1@1+ (1,0) [0|1] "" Vector__XXX
 SG_ OptSetRvsTrvlSpdLmt : 577|1@1+ (1,0) [0|1] "" Vector__XXX
 SG_ OptSetEmcvBoomDnImpactPrevent : 576|1@1+ (1,0) [0|1] "" Vector__XXX
 SG_ OptSetEmcvBoomUpImpactPrevent : 575|1@1+ (1,0) [0|1] "" Vector__XXX
 SG_ OptSetEmcvBckDumpImpactPrevent : 574|1@1+ (1,0) [0|1] "" Vector__XXX
 SG_ OptSetEmcvBckCrowdImpactPrevent : 573|1@1+ (1,0) [0|1] "" Vector__XXX
 SG_ OptSetEmcvBckSens : 572|1@1+ (1,0) [0|1] "" Vector__XXX
 SG_ OptSetEmcvBoomSens : 571|1@1+ (1,0) [0|1] "" Vector__XXX
 SG_ OptSetEstrJoySens : 569|2@1+ (1,0) [0|3] "" Vector__XXX
 SG_ OptSetWrkLis : 568|1@1+ (1,0) [0|1] "" Vector__XXX
 SG_ OptSetLcInVal : 552|16@1+ (0.1,0) [0|6425.5] "mm" Vector__XXX
 SG_ OptSetR2InVal : 536|16@1+ (0.1,0) [0|6425.5] "mm" Vector__XXX
 SG_ OptSetR1InVal : 520|16@1+ (0.1,0) [0|6425.5] "mm" Vector__XXX
 SG_ OptSetBckWghInVlue : 504|16@1+ (0.1,0) [0|6425.5] "kg" Vector__XXX
 SG_ OptSetBoomWghInVal : 488|16@1+ (0.1,0) [0|6425.5] "kg" Vector__XXX
 SG_ OptSetMaxCritWghVal : 472|16@1+ (0.5,0) [0|32127.5] "kg" Vector__XXX
 SG_ OptSetHalfCritWghVal : 456|16@1+ (0.5,0) [0|32127.5] "kg" Vector__XXX
 SG_ OptSetElecStr : 455|1@1+ (1,0) [0|1] "" Vector__XXX
 SG_ OptSetRvsFan : 454|1@1+ (1,0) [0|1] "" Vector__XXX
 SG_ OptSetRcw : 453|1@1+ (1,0) [0|1] "" Vector__XXX
 SG_ OptSetQckCoupler : 452|1@1+ (1,0) [0|1] "" Vector__XXX
 SG_ OptSetTrvlOrSwgAlm : 451|1@1+ (1,0) [0|1] "" Vector__XXX
 SG_ OptSetSmk : 450|1@1+ (1,0) [0|1] "" Vector__XXX
 SG_ OptSetOwd : 449|1@1+ (1,0) [0|1] "" Vector__XXX
 SG_ OptSetMchNameInit : 448|1@1+ (1,0) [0|250] "" Vector__XXX
 SG_ OptSetEmvcPmcv : 447|1@1+ (1,0) [0|1] "" Vector__XXX
 SG_ OptSetAebReq : 446|1@1+ (1,0) [0|1] "" Vector__XXX
 SG_ OptSetRvsFanOn : 445|1@1+ (1,0) [0|1] "" Vector__XXX
 SG_ OptSetRvsFanMd : 444|1@1+ (1,0) [0|1] "" Vector__XXX
 SG_ OptSetWhgWld : 443|1@1+ (1,0) [0|1] "" Vector__XXX
 SG_ OptSetHydrostatCalbCmd : 442|1@1+ (1,0) [0|1] "" Vector__XXX
 SG_ OptSetClutchCalbCmd : 441|1@1+ (1,0) [0|1] "" Vector__XXX
 SG_ OptSetEmgMd : 440|1@1+ (1,0) [0|1] "" Vector__XXX
 SG_ OptSetCreepAct : 439|1@1+ (1,0) [0|1] "" Vector__XXX
 SG_ OptSetThw : 438|1@1+ (1,0) [0|1] "" Vector__XXX
 SG_ OptSetAxleOilCool : 437|1@1+ (1,0) [0|1] "" Vector__XXX
 SG_ OptSetAngSs : 434|3@1+ (1,0) [0|7] "" Vector__XXX
 SG_ OptSetBrkPdlCalb : 432|2@1+ (1,0) [0|3] "" Vector__XXX
 SG_ OptSetCreepGr : 424|8@1+ (1,0) [0|250] "" Vector__XXX
 SG_ OptSetLisOprSpd : 416|8@1+ (1,0) [0|250] "kmph" Vector__XXX
 SG_ OptSetRvsFanTm : 408|8@1+ (1,0) [0|250] "minutes" Vector__XXX
 SG_ OptSetLis : 407|1@1+ (1,0) [0|1] "" Vector__XXX
 SG_ OptSetEmgStr : 406|1@1+ (1,0) [0|1] "" Vector__XXX
 SG_ OptSetDhl : 405|1@1+ (1,0) [0|1] "" Vector__XXX
 SG_ OptSetFnr2LeverType : 403|2@1+ (1,0) [0|3] "" Vector__XXX
 SG_ OptSetTrmsLmtGr : 400|3@1+ (1,0) [0|7] "" Vector__XXX
 SG_ OptSetTransBck : 399|1@1+ (1,0) [0|1] "" Vector__XXX
 SG_ OptSetItgtFltBoom : 398|1@1+ (1,0) [0|1] "" Vector__XXX
 SG_ OptSetBeacon : 397|1@1+ (1,0) [0|1] "" Vector__XXX
 SG_ OptSetMultiFuncBtnSel : 393|4@1+ (1,0) [0|15] "" Vector__XXX
 SG_ OptSetAutoIdle : 392|1@1+ (1,0) [0|1] "" Vector__XXX
 SG_ MchNo11 : 384|8@1+ (1,0) [0|255] "" Vector__XXX
 SG_ MchNo10 : 376|8@1+ (1,0) [0|255] "" Vector__XXX
 SG_ MchNo9 : 368|8@1+ (1,0) [0|255] "" Vector__XXX
 SG_ MchNo8 : 360|8@1+ (1,0) [0|255] "" Vector__XXX
 SG_ MchNo7 : 352|8@1+ (1,0) [0|255] "" Vector__XXX
 SG_ MchNo6 : 344|8@1+ (1,0) [0|255] "" Vector__XXX
 SG_ MchNo5 : 336|8@1+ (1,0) [0|255] "" Vector__XXX
 SG_ MchNo4 : 328|8@1+ (1,0) [0|255] "" Vector__XXX
 SG_ MchNo3 : 320|8@1+ (1,0) [0|255] "" Vector__XXX
 SG_ MchNo2 : 312|8@1+ (1,0) [0|255] "" Vector__XXX
 SG_ MchNo1 : 304|8@1+ (1,0) [0|255] "" Vector__XXX
 SG_ AutoIdleTm : 288|16@1+ (1,0) [0|64255] "sec" Vector__XXX
 SG_ BrkrOprTm : 272|16@1+ (1,0) [0|64255] "sec" Vector__XXX
 SG_ OptSetAutoShutOffTm : 264|8@1+ (1,0) [0|250] "minutes" Vector__XXX
 SG_ OptSetAutoShutOff : 263|1@1+ (1,0) [0|1] "" Vector__XXX
 SG_ OptSetAutoShutOffCancel : 262|1@1+ (1,0) [0|1] "" Vector__XXX
 SG_ OptSetAutoIdleRpmTmp : 261|1@1+ (1,0) [0|1] "" Vector__XXX
 SG_ OptSetSpc : 260|1@1+ (1,0) [0|1] "" Vector__XXX
 SG_ OptSetVoiceWrnCmd : 259|1@1+ (1,0) [0|1] "" Vector__XXX
 SG_ OptSetBoomSwgUSe : 258|1@1+ (1,0) [0|1] "" Vector__XXX
 SG_ OptSetTrvl2PmpCmbRls : 257|1@1+ (1,0) [0|1] "" Vector__XXX
 SG_ OptSetTrvl1PmpUse : 256|1@1+ (1,0) [0|1] "" Vector__XXX
 SG_ OptSetTrmsMaxSpdLmtChk : 255|1@1+ (1,0) [0|1] "" Vector__XXX
 SG_ OptSetHhAlt : 254|1@1+ (1,0) [0|1] "" Vector__XXX
 SG_ OptSetRipperOpt : 253|1@1+ (1,0) [0|1] "" Vector__XXX
 SG_ OptSetRttOpt : 252|1@1+ (1,0) [0|1] "" Vector__XXX
 SG_ OptSetJoyThwRtt : 250|2@1+ (1,0) [0|3] "" Vector__XXX
 SG_ OptSetJoyThwTw : 248|2@1+ (1,0) [0|3] "" Vector__XXX
 SG_ OptSetTw : 246|2@1+ (1,0) [0|3] "" Vector__XXX
 SG_ OptSetOptPdl : 245|1@1+ (1,0) [0|1] "" Vector__XXX
 SG_ OptSetAttPdlJoySel : 243|2@1+ (1,0) [0|3] "" Vector__XXX
 SG_ OptSet2Pmp : 242|1@1+ (1,0) [0|1] "" Vector__XXX
 SG_ OptSetAttTw : 241|1@1+ (1,0) [0|1] "" Vector__XXX
 SG_ OptSetAttBrkr : 240|1@1+ (1,0) [0|1] "" Vector__XXX
 SG_ OptSetKeylessUse : 191|1@1+ (1,0) [0|1] "" Vector__XXX
 SG_ OptSetKeyless : 190|1@1+ (1,0) [0|1] "" Vector__XXX
 SG_ OptSetWiper : 189|1@1+ (1,0) [0|1] "" Vector__XXX
 SG_ OptSetTrvlMotOvrHtWrn : 188|1@1+ (1,0) [0|1] "" Vector__XXX
 SG_ OptSetFnrDefault : 187|1@1+ (1,0) [0|1] "" Vector__XXX
 SG_ OptSetFnrSel : 186|1@1+ (1,0) [0|1] "" Vector__XXX
 SG_ OptSetCanTypeCmbSw : 185|1@1+ (1,0) [0|1] "" Vector__XXX
 SG_ UserDtIdx : 176|8@1+ (1,0) [0|255] "" Vector__XXX
 SG_ VhcSerialNo : 120|56@1+ (1,0) [0|255] "" Vector__XXX
 SG_ OptSetAttWghFactor : 100|4@1+ (1,0) [0|15] "" Vector__XXX
 SG_ OptSetCanTypeFuelSs : 99|1@1+ (1,0) [0|1] "" Vector__XXX
 SG_ OptSetSubBrkLmp : 98|1@1+ (1,0) [0|1] "" Vector__XXX
 SG_ TiltRttMd : 97|1@1+ (1,0) [0|1] "" Vector__XXX
 SG_ USerLckUnlockSt : 96|1@1+ (1,0) [0|1] "" Vector__XXX
 SG_ UserPw : 64|32@1+ (1,0) [0|255] "" Vector__XXX
 SG_ OptWgh2D : 63|1@1+ (1,0) [0|1] "" Vector__XXX
 SG_ OptMC : 62|1@1+ (1,0) [0|1] "" Vector__XXX
 SG_ OptEgPostHtAct : 61|1@1+ (1,0) [0|1] "" Vector__XXX
 SG_ Opt2DMG : 60|1@1+ (1,0) [0|1] "" Vector__XXX
 SG_ AdminUse2 : 56|3@1+ (1,0) [0|7] "" Vector__XXX
 SG_ AdminUse1 : 48|3@1+ (1,0) [0|7] "" Vector__XXX
 SG_ AdminUse0 : 40|3@1+ (1,0) [0|7] "" Vector__XXX
 SG_ OwnerPw0UpTm : 33|2@1+ (1,0) [0|3] "" Vector__XXX
 SG_ OwnerPw0Use : 32|1@1+ (1,0) [0|1] "" Vector__XXX
 SG_ OwnerPw0 : 0|32@1+ (1,0) [0|255] "" Vector__XXX

CM_ BO_ 2566879562 "TGU Identification";
CM_ SG_ 2566879562 ProdDt "Production Date";
CM_ SG_ 2566879562 TguId "Terminal Serial Number";
CM_ SG_ 2566879562 TypeCd "Terminal Type Code";
CM_ BO_ 2583645002 "GPS Information";
CM_ SG_ 2583645002 GpsSt "GPS State";
CM_ SG_ 2583645002 NoOfGpsSat "Number of GPS Satellites";
CM_ SG_ 2583645002 Z "Altitude";
CM_ SG_ 2583645002 Y "Longitude";
CM_ SG_ 2583645002 X "Latitude";
CM_ BO_ 2583644490 "Cellular Information";
CM_ SG_ 2583644490 GsmdBm "GSM dBm";
CM_ SG_ 2583644490 GsmType "GSM Type Connected Details";
CM_ SG_ 2583644490 CurNw "Current Network";
CM_ SG_ 2583644490 TmnIpAdr "Terminal IP Address";
CM_ SG_ 2583644490 ServerAdr "Server Address";
CM_ SG_ 2583644490 Apn "APN";
CM_ SG_ 2583644490 Imei "Cell IMEI";
CM_ SG_ 2583644490 SimIccid "SIM ICCID";
CM_ BO_ 2566878282 "Satelite Info";
CM_ SG_ 2566878282 Install "Install";
CM_ SG_ 2566878282 Imei "IMEI";
CM_ SG_ 2566878282 Rssi "RSSI";
CM_ SG_ 2566878282 Type "Type";
CM_ SG_ 2566878282 Enable "Enable";
CM_ BO_ 2566878794 "Telematics Security";
CM_ SG_ 2566878794 ActnDrSec "Activation DR security";
CM_ SG_ 2566878794 WifiAntSt "WiFi Antenna Status";
CM_ SG_ 2566878794 CellAntSt "Cell Antenna Status";
CM_ SG_ 2566878794 GpsAntSt "GPS Antenna Status";
CM_ SG_ 2566878794 SecCmd "Security Command";
CM_ BO_ 2583644746 "TGU Time";
CM_ SG_ 2583644746 UtcTm "UTC Time";
CM_ SG_ 2583644746 LocalTmOffset "Local Time Offset";
CM_ BO_ 2566879272 "TMS Temporary Unlock Password Information";
CM_ BO_ 2566879306 "Temp Unlock";
CM_ BO_ 2566879818 "Digital Key Log In";
CM_ SG_ 2566879818 Dkey "DigitalKeyLoggedIn";
CM_ SG_ 2566879818 KeyType "KeyType";
CM_ SG_ 2566879818 LogIn "LogIn";
CM_ BO_ 2566880074 "Digital Key List Detected";
CM_ SG_ 2566880074 DkeyList "DigitalKeyList";
CM_ SG_ 2566880074 Cnt "DigitalKeyCount";
CM_ BO_ 2566880296 "Digital Key Select";
CM_ SG_ 2566880296 DigitalKey "DigitalKeySelected";
CM_ SG_ 2566880296 SelType "SelectType";
CM_ BO_ 2566880586 "Ack/Nack or Status";
CM_ SG_ 2566880586 Ack "Ack_Nack";
CM_ BO_ 2566880842 "P.Unlock Seed EPOS->GP/DMS/TGU";
CM_ SG_ 2566880842 TmsPmntUnlockCd "TMSPermanentUnlockCode";
CM_ BO_ 2566881064 "Security Status Information";
CM_ BO_ 2566881098 "Security Status Information";
CM_ BO_ 2566883328 "Transmission of Proprietary SCR2 frame over CAN";
CM_ SG_ 2566883328 EmsObdIndFail "EmissionOBDInducementfailurereason";
CM_ SG_ 2566883328 UreaLvAlm "Urealevelalarm";
CM_ SG_ 2566883328 Scr2RegInfo "SCR2RegulationInformation";
CM_ SG_ 2566883328 EmsObdIndSt "Emission-OBDinducementstate";
CM_ SG_ 2566883328 UreaLvBzSt "Urealevelbuzzerstatus";
CM_ BO_ 2583625761 "ADT Analog Sensor Information";
CM_ SG_ 2583625761 RrSspnLhSsPrs "Rear Suspension LH Sensor Press.";
CM_ SG_ 2583625761 RrSspnRhSsPrs "Rear Suspension RH Sensor Press.";
CM_ SG_ 2583625761 AcpSsPrs "ACP Sensor Pressure";
CM_ SG_ 2583625761 BatVlt "Battery Voltage [Default]";
CM_ SG_ 2583625761 AltVlt "AlternaterVoltage";
CM_ SG_ 2583625761 Rr2BrkSsPrs "Rear2BrakePress.SensorPress.";
CM_ SG_ 2583625761 BoomCylRodSsPrs "BoomCyclinderPress.(Rod)SensorPress.";
CM_ SG_ 2583625761 BoomCylHeadSsPrs "BoomCyclinderPress.(Head)SensorPress.";
CM_ SG_ 2583625761 CtrPinAngSs1Vlt "CenterPinAngleSensor1Voltage";
CM_ SG_ 2583625761 AccPdlSs2Vlt "AccelPedalSensor2Voltage";
CM_ SG_ 2583625761 DumpBedAngSs2Vlt "DumpBedAngleSensor2Voltage";
CM_ SG_ 2583625761 DumpBedAngSs1Vlt "DumpBedAngleSensor1Voltage";
CM_ SG_ 2583625761 BrkInchPdlSs1Vlt "Brake/InchPedalSensor1Voltage";
CM_ SG_ 2583625761 TipJoySs1Vlt "TipJoystickSensor1Voltage";
CM_ SG_ 2583625761 RhCylSsPrs "RHCyclinderPress.SensorPress.";
CM_ SG_ 2583625761 EmgStrSsPrs "EmergencySteer.Press.SensorPress.";
CM_ SG_ 2583625761 AxleOilSsTmp "AxleOilTemp.SensorTemp.";
CM_ SG_ 2583625761 FuelSsLv "FuelSensorLevel";
CM_ SG_ 2583625761 Rr1BrkSsPrs "Rear1BrakePress.SensorPress.";
CM_ SG_ 2583625761 FrBrkSsPrs "FrontBrakePress.SensorPress.";
CM_ SG_ 2583625761 AccPdlSs1Vlt "AccelPedalSensor1Voltage";
CM_ SG_ 2583625761 CtrPinAngSs2Vlt "CenterPinAngleSensor2Voltage";
CM_ SG_ 2583625761 TmsSecVlt "TMS3.5VLineVoltage";
CM_ SG_ 2583625761 LhCylSsPrs "LHCyclinderPress.SensorPress.";
CM_ SG_ 2583625761 Acc3SsPrs "ACC3Press.SensorPress.";
CM_ SG_ 2583625761 BrkInchPdlSs2Vlt "Brake/InchPedalSensor2Voltage";
CM_ SG_ 2583625761 CacFanSsPrs "CACFanPressSensorPress.";
CM_ SG_ 2583625761 Acc2SsPrs "ACC2Press.SensorPress.";
CM_ SG_ 2583625761 TipJoySs2Vlt "TipJoystickSensor2Voltage";
CM_ SG_ 2583625761 TocFanSsPrs "TOCFanPressSensorPress.";
CM_ SG_ 2583625761 Acc1SsPrs "ACC1Press.SensorPress.";
CM_ SG_ 2583625761 PrkBrkSsPrs "ParkingBrakeSensorPress.";
CM_ SG_ 2583625761 MainSsPrs "MainPress.SensorPress.";
CM_ SG_ 2583625761 WifSsVlt "WIFSensorVoltage";
CM_ SG_ 2583625761 HydOilSsTmp "HydraulicOilTemp.SensorTemp.";
CM_ BO_ 2583626017 "ADT Analog Actuator Information";
CM_ SG_ 2583626017 FanDrvTocEvc "FanDrive(TOC)EPPRV/VCurrent";
CM_ SG_ 2583626017 eFan2DutyRatio "E-Fan2DutyRatio";
CM_ SG_ 2583626017 eFan3DutyRatio "E-Fan3DutyRatio";
CM_ SG_ 2583626017 eBrkEvc "E-BrakeEPPRV/VCurrent";
CM_ SG_ 2583626017 eFan1DutyRatio "E-Fan1DutyRatio";
CM_ SG_ 2583626017 FanDrvRadCacEvc "FanDrive(RAD/CAC)EPPRV/VCurrent";
CM_ SG_ 2583626017 BodyDnEvc "BodyDownEPPRV/VCurrent";
CM_ SG_ 2583626017 BodyUpEvc "BodyUpEPPRV/VCurrent";
CM_ BO_ 2583626273 "ADT Digital Sensor Information";
CM_ SG_ 2583626273 BrkholdSw "Brake hold Switch";
CM_ SG_ 2583626273 DhlMnSw "DHL Manual Switch";
CM_ SG_ 2583626273 CoolTankLvSw "Coolant tank level Switch";
CM_ SG_ 2583626273 StartCrkSw "StarterCrankingSwitch";
CM_ SG_ 2583626273 GrSelSw "GearSelectorSwitch";
CM_ SG_ 2583626273 GrSelNtrlSw "GearSelectorNeutrualSwitch";
CM_ SG_ 2583626273 PrkSw "ParkingSwitch";
CM_ SG_ 2583626273 GrSelRvsSw "GearSelectorReverseSwitch";
CM_ SG_ 2583626273 GrSelShftDnSw "GearSelectorShiftDownSwitch";
CM_ SG_ 2583626273 GrSelShftUpSw "GearSelectorShiftUpSwitch";
CM_ SG_ 2583626273 GrSelFwdSw "GearSelectorForwardSwitch";
CM_ SG_ 2583626273 DustIndSw "DustIndicatorSwitch";
CM_ SG_ 2583626273 StartAccSw "StarterACCSwitch";
CM_ SG_ 2583626273 AtsForceRgnSw "ATSForcedRegenerationSwitch";
CM_ SG_ 2583626273 AtsRgnIhbsw "ATSRegenerationInhibitSwitch";
CM_ SG_ 2583626273 eFan3ErrSt "E-Fan3ErrorState";
CM_ SG_ 2583626273 KeyBrSw "Key(Br)Switch";
CM_ SG_ 2583626273 TipJoySw "TipJoystickSwitch";
CM_ SG_ 2583626273 AgsSw "AGSSwitch";
CM_ SG_ 2583626273 eFan2ErrSt "E-Fan2ErrorState";
CM_ SG_ 2583626273 eFan1ErrSt "E-Fan1ErrorState";
CM_ SG_ 2583626273 SeatBeltSt "SeatBeltState";
CM_ SG_ 2583626273 FrWiperStpSw "FrontWiperStopSwitch";
CM_ BO_ 2583626529 "ADT Digital Actuator Information";
CM_ SG_ 2583626529 RrSspnRhDn "Rear Suspension RH Down";
CM_ SG_ 2583626529 RrSspnRhUp "Rear Suspension RH Up";
CM_ SG_ 2583626529 RrSspnLhDn "Rear Suspension LH Down";
CM_ SG_ 2583626529 RrSspnLhUp "Rear Suspension LH Up";
CM_ SG_ 2583626529 SusRhDn "Sus.RHDown";
CM_ SG_ 2583626529 TocRvs "TOCReverse";
CM_ SG_ 2583626529 TurnSigRhRly "TurnSignalRHRelay";
CM_ SG_ 2583626529 TurnSigLhRly "TurnSignalLHRelay";
CM_ SG_ 2583626529 SusRhUp "Sus.RHUp";
CM_ SG_ 2583626529 EgRunOutSig "EngineRunningOutputSignal";
CM_ SG_ 2583626529 SusLhDn "Sus.LHDown";
CM_ SG_ 2583626529 UreaSuperChgWrnSig "UreaSuperchargingWarningSignal";
CM_ SG_ 2583626529 FanStpSv "FanStopS/V";
CM_ SG_ 2583626529 SusLhUp "Sus.LHUp";
CM_ SG_ 2583626529 PrkBrkRlsSv "ParkingBrakeReleaseS/V";
CM_ SG_ 2583626529 AxleOilCoolSv "AxleOilCoolerS/V";
CM_ SG_ 2583626529 TocUnloading "TOCUnloading";
CM_ SG_ 2583626529 AccRly "ACCRelay";
CM_ SG_ 2583626529 LiftArmFlt "LiftArmFloat";
CM_ SG_ 2583626529 AutoShutOffRly "AutoShutOffRelay";
CM_ SG_ 2583626529 BrkChgSv "BrakeChargeS/V";
CM_ BO_ 2566884897 "Tire Information Group 1";
CM_ SG_ 2566884897 RrRhTirePrs "RearRightTirePressure";
CM_ SG_ 2566884897 RrLhTirePrs "RearLeftTirePressure";
CM_ SG_ 2566884897 CtrRhTirePrs "CenterRightTirePressure";
CM_ SG_ 2566884897 CtrLhTirePrs "CenterLeftTirePressure";
CM_ SG_ 2566884897 FronRhTirePrs "FrontRightTirePressure";
CM_ SG_ 2566884897 FrLhTirePrs "FrontLeftTirePressure";
CM_ BO_ 2566885153 "Tire Information Group 2";
CM_ SG_ 2566885153 RrRhTireTmp "RearRightTireTemperature";
CM_ SG_ 2566885153 RrLhTireTmp "RearLeftTireTemperature";
CM_ SG_ 2566885153 CtrRhTireTmp "CenterRightTireTemperature";
CM_ SG_ 2566885153 CtrLhTireTmp "CenterLeftTireTemperature";
CM_ SG_ 2566885153 FronRhTireTmp "FrontRightTireTemperature";
CM_ SG_ 2566885153 FrLhTireTmp "FrontLeftTireTemperature";
CM_ BO_ 2566885409 "QR Code Information";
CM_ SG_ 2566885409 PartNo "PartNumber";
CM_ SG_ 2566885409 SerialNo "SerialNumber";
CM_ SG_ 2566885409 MnftCode "ManufacturerCode";
CM_ SG_ 2566885409 ComCode "ComponentCode";
CM_ SG_ 2566885409 Year "Year";
CM_ SG_ 2566885409 Day "Day";
CM_ SG_ 2566885409 Month "Month";
CM_ SG_ 2566885409 SwVer "SWVersion";
CM_ BO_ 2566885665 "ECO Report Information";
CM_ SG_ 2566885665 TotAvgReliefOprPct "TotalAverageofReliefIdleOperationPercentage";
CM_ SG_ 2566885665 TotAvgLwIdleOprPct "TotalAverageofLowIdleOperationPercentage";
CM_ SG_ 2566885665 TotAvgHhIdleOprPct "TotalAverageofHighIdleOperationPercentage";
CM_ SG_ 2566885665 Day7ReliefOprPct "7stDayReliefOperationPercentage";
CM_ SG_ 2566885665 Day7LwIdleOprPct "7stDayLowIdleOperationPercentage";
CM_ SG_ 2566885665 Day7HhIdleOprPct "7stDayHighIdleOperationPercentage";
CM_ SG_ 2566885665 Day6ReliefOprPct "6stDayReliefOperationPercentage";
CM_ SG_ 2566885665 Day6LwIdleOprPct "6stDayLowIdleOperationPercentage";
CM_ SG_ 2566885665 Day6HhIdleOprPct "6stDayHighIdleOperationPercentage";
CM_ SG_ 2566885665 Day5ReliefOprPct "5stDayReliefOperationPercentage";
CM_ SG_ 2566885665 Day5LwIdleOprPct "5stDayLowIdleOperationPercentage";
CM_ SG_ 2566885665 Day5HhIdleOprPct "5stDayHighIdleOperationPercentage";
CM_ SG_ 2566885665 Day4ReliefOprPct "4stDayReliefOperationPercentage";
CM_ SG_ 2566885665 Day4LwIdleOprPct "4stDayLowIdleOperationPercentage";
CM_ SG_ 2566885665 Day4HhIdleOprPct "4stDayHighIdleOperationPercentage";
CM_ SG_ 2566885665 Day3ReliefOprPct "3stDayReliefOperationPercentage";
CM_ SG_ 2566885665 Day3LwIdleOprPct "3stDayLowIdleOperationPercentage";
CM_ SG_ 2566885665 Day3HhIdleOprPct "3stDayHighIdleOperationPercentage";
CM_ SG_ 2566885665 Day2ReliefOprPct "2stDayReliefOperationPercentage";
CM_ SG_ 2566885665 Day2LwIdleOprPct "2stDayLowIdleOperationPercentage";
CM_ SG_ 2566885665 Day2HhIdleOprPct "2stDayHighIdleOperationPercentage";
CM_ SG_ 2566885665 Day1ReliefOprPct "1stDayReliefOperationPercentage";
CM_ SG_ 2566885665 Day1LwIdleOprPct "1stDayLowIdleOperationPercentage";
CM_ SG_ 2566885665 Day1HhIdleOprPct "1stDayHighIdleOperationPercentage";
CM_ SG_ 2566885665 NowReliefOprLv "ReliefOperationLevel";
CM_ SG_ 2566885665 NowLwIdleOprLv "LowIdleOperationLevel";
CM_ SG_ 2566885665 NowHhIdleOprLv "HighIdleOperationLevel";
CM_ SG_ 2566885665 NowReliefOprPct "ReliefOperationPercentage";
CM_ SG_ 2566885665 NowLwIdleOprPct "LowIdleOperationPercentage";
CM_ SG_ 2566885665 NowHhIdleOprPct "HighIdleOperationPercentage";
CM_ BO_ 2566886586 "Radar Object Zone Index ";
CM_ SG_ 2566886586 Objinzone6 "Object in zone 6";
CM_ SG_ 2566886586 Objinzone5 "Object in zone 5";
CM_ SG_ 2566886586 Objinzone4 "Object in zone 4";
CM_ SG_ 2566886586 Objinzone3 "Object in zone 3";
CM_ SG_ 2566886586 Objinzone2 "Object in zone 2";
CM_ SG_ 2566886586 Objinzone1 "Object in zone 1";
CM_ BO_ 2566886587 "Radar Object Zone Index ";
CM_ SG_ 2566886587 Objinzone6 "Object in zone 6";
CM_ SG_ 2566886587 Objinzone5 "Object in zone 5";
CM_ SG_ 2566886587 Objinzone4 "Object in zone 4";
CM_ SG_ 2566886587 Objinzone3 "Object in zone 3";
CM_ SG_ 2566886587 Objinzone2 "Object in zone 2";
CM_ SG_ 2566886587 Objinzone1 "Object in zone 1";
CM_ BO_ 2566886588 "Radar Object Zone Index ";
CM_ SG_ 2566886588 Objinzone6 "Object in zone 6";
CM_ SG_ 2566886588 Objinzone5 "Object in zone 5";
CM_ SG_ 2566886588 Objinzone4 "Object in zone 4";
CM_ SG_ 2566886588 Objinzone3 "Object in zone 3";
CM_ SG_ 2566886588 Objinzone2 "Object in zone 2";
CM_ SG_ 2566886588 Objinzone1 "Object in zone 1";
CM_ BO_ 2566886842 "Radar Object Information ";
CM_ SG_ 2566886842 ObjSeq "Object Sequence";
CM_ SG_ 2566886842 PwrOfObj "Power of Object";
CM_ SG_ 2566886842 YDirVelocity "Y-Direction Velocity";
CM_ SG_ 2566886842 XDirVelocity "X-Direction Velocity";
CM_ SG_ 2566886842 ZDirPos "Z-Direction Position";
CM_ SG_ 2566886842 YDirPos "Y-Direction Position";
CM_ SG_ 2566886842 XDirPos "X-Direction Position";
CM_ BO_ 2566886843 "Radar Object Information ";
CM_ SG_ 2566886843 ObjSeq "Object Sequence";
CM_ SG_ 2566886843 PwrOfObj "Power of Object";
CM_ SG_ 2566886843 YDirVelocity "Y-Direction Velocity";
CM_ SG_ 2566886843 XDirVelocity "X-Direction Velocity";
CM_ SG_ 2566886843 ZDirPos "Z-Direction Position";
CM_ SG_ 2566886843 YDirPos "Y-Direction Position";
CM_ SG_ 2566886843 XDirPos "X-Direction Position";
CM_ BO_ 2566886844 "Radar Object Information ";
CM_ SG_ 2566886844 ObjSeq "Object Sequence";
CM_ SG_ 2566886844 PwrOfObj "Power of Object";
CM_ SG_ 2566886844 YDirVelocity "Y-Direction Velocity";
CM_ SG_ 2566886844 XDirVelocity "X-Direction Velocity";
CM_ SG_ 2566886844 ZDirPos "Z-Direction Position";
CM_ SG_ 2566886844 YDirPos "Y-Direction Position";
CM_ SG_ 2566886844 XDirPos "X-Direction Position";
CM_ BO_ 2566886952 "AVM View Mode";
CM_ SG_ 2566886952 RrVwPriMd "RearViewPriorityMode";
CM_ SG_ 2566886952 VwMd "ViewMode";
CM_ BO_ 2566887223 "AVM Setting Information";
CM_ SG_ 2566887223 Tb2ToleranceCompSt "TB2.0 Tolerance Compensation Status";
CM_ SG_ 2566887223 Tb2ToleranceCompSetApp "TB2.0 Tolerance Compensation Setting Applied Status";
CM_ SG_ 2566887223 RrVwPriMd "RearViewPriorityMode";
CM_ SG_ 2566887223 AvmWrnGud "AVMWarningGuide";
CM_ SG_ 2566887223 AvmSt "AVMStatus";
CM_ SG_ 2566887223 AvmUltraBz "AVMUltraBuzzer";
CM_ SG_ 2566887223 AvmTonSize "AVMTonSize";
CM_ SG_ 2566887223 AvmDisplayMsg "AVMDisplayMessage";
CM_ SG_ 2566887223 AvmOutType "AVMOutputType";
CM_ SG_ 2566887223 AvmVw "AVMView";
CM_ SG_ 2566887223 AvmLanguagePack "AVMLanguagePack";
CM_ BO_ 2566887479 "AVM Ultral Sonic Sensor signal";
CM_ SG_ 2566887479 UltsSigL6 "UltraSonicSignalL6";
CM_ SG_ 2566887479 UltsSigR6 "UltraSonicSignalR6";
CM_ SG_ 2566887479 UltsSigL5 "UltraSonicSignalL5";
CM_ SG_ 2566887479 UltsSigR5 "UltraSonicSignalR5";
CM_ SG_ 2566887479 UltsSigL4 "UltraSonicSignalL4";
CM_ SG_ 2566887479 UltsSigR4 "UltraSonicSignalR4";
CM_ SG_ 2566887479 UltsSigL3 "UltraSonicSignalL3";
CM_ SG_ 2566887479 UltsSigR3 "UltraSonicSignalR3";
CM_ SG_ 2566887479 UltsSigL2 "UltraSonicSignalL2";
CM_ SG_ 2566887479 UltsSigR2 "UltraSonicSignalR2";
CM_ SG_ 2566887479 UltsSigL1 "UltraSonicSignalL1";
CM_ SG_ 2566887479 UltsSigR1 "UltraSonicSignalR1";
CM_ BO_ 2566887720 "AVM Cal Rx";
CM_ SG_ 2566887720 CamPrmtCorCompleteSt "CameraParametersCorrectionCompleteStatus";
CM_ SG_ 2566887720 CamPrmtVerMsb "CameraParametersVersion(MSB)";
CM_ SG_ 2566887720 CamPrmtVerLsb "CameraParametersVersion(LSB)";
CM_ SG_ 2566887720 Language "Language";
CM_ SG_ 2566887720 ToleranceCorMenuentryCmd "ToleranceCorrectionMenuentryCommand";
CM_ SG_ 2566887720 WrnGudSetCmd "WariningGuideSettingCommand";
CM_ SG_ 2566887720 UltsSs08Cmd "UltrasonicSensor08Command";
CM_ SG_ 2566887720 UltsSs07Cmd "UltrasonicSensor07Command";
CM_ SG_ 2566887720 UltsSs06Cmd "UltrasonicSensor06Command";
CM_ SG_ 2566887720 UltsSs05Cmd "UltrasonicSensor05Command";
CM_ SG_ 2566887720 UltsSs04Cmd "UltrasonicSensor04Command";
CM_ SG_ 2566887720 UltsSs03Cmd "UltrasonicSensor03Command";
CM_ SG_ 2566887720 UltsSs02Cmd "UltrasonicSensor02Command";
CM_ SG_ 2566887720 UltsSs01Cmd "UltrasonicSensor01Command";
CM_ SG_ 2566887720 UltsSs12Cmd "UltrasonicSensor12Command";
CM_ SG_ 2566887720 UltsSs11Cmd "UltrasonicSensor11Command";
CM_ SG_ 2566887720 UltsSs10Cmd "UltrasonicSensor10Command";
CM_ SG_ 2566887720 UltsSs09Cmd "UltrasonicSensor09Command";
CM_ SG_ 2566887720 SetApplicationCmd "SettingApplicationCommand";
CM_ SG_ 2566887720 ToleranceCorCmd "ToleranceCorrectionCommand";
CM_ SG_ 2566887720 FactoryReCmd "FactoryReset";
CM_ SG_ 2566887720 UltsSsOpt "UltrasonicSensorOption";
CM_ SG_ 2566887720 UltsBuzzerStopSig "UltrasonicBuzzerStopSignal";
CM_ SG_ 2566887720 BoomCamOpt "BoomCameraOption";
CM_ SG_ 2566887720 UltsBzOffSig "UltrasonicBuzzerOFFSignal";
CM_ SG_ 2566887720 UltsRecognitionDistanceSet "UltrasonicRecognitionDistanceSetting";
CM_ SG_ 2566887720 VhcType2 "VehicleType02";
CM_ SG_ 2566887720 VhcType1 "VehicleType01";
CM_ SG_ 2566887720 TonsOftheTensDigit "TonsOftheTensDigit";
CM_ SG_ 2566887720 TonsOftheUnitsDigit "TonsOftheUnitsDigit";
CM_ SG_ 2566887720 FactoryType "FactoryType";
CM_ SG_ 2566887720 VwMd "ViewMode";
CM_ BO_ 2566887991 "AVM Cal Tx";
CM_ SG_ 2566887991 CamPrmtCorCompleteSt "CameraParametersCorrectionCompleteStatus";
CM_ SG_ 2566887991 CamPrmtVerMsb "CameraParametersVersion(MSB)";
CM_ SG_ 2566887991 CamPrmtVerLsb "CameraParametersVersion(LSB)";
CM_ SG_ 2566887991 Language "Language";
CM_ SG_ 2566887991 ToleranceCorMenuentryCmd "ToleranceCorrectionMenuentryCommand";
CM_ SG_ 2566887991 WrnGudSetCmd "WariningGuideSettingCommand";
CM_ SG_ 2566887991 UltsSs08Cmd "UltraSonicSensor08Command";
CM_ SG_ 2566887991 UltsSs07Cmd "UltraSonicSensor07Command";
CM_ SG_ 2566887991 UltsSs06Cmd "UltraSonicSensor06Command";
CM_ SG_ 2566887991 UltsSs05Cmd "UltraSonicSensor05Command";
CM_ SG_ 2566887991 UltsSs04Cmd "UltraSonicSensor04Command";
CM_ SG_ 2566887991 UltsSs03Cmd "UltraSonicSensor03Command";
CM_ SG_ 2566887991 UltsSs02Cmd "UltraSonicSensor02Command";
CM_ SG_ 2566887991 UltsSs01Cmd "UltraSonicSensor01Command";
CM_ SG_ 2566887991 UltsSs12Cmd "UltraSonicSensor12Command";
CM_ SG_ 2566887991 UltsSs11Cmd "UltraSonicSensor11Command";
CM_ SG_ 2566887991 UltsSs10Cmd "UltraSonicSensor10Command";
CM_ SG_ 2566887991 UltsSs09Cmd "UltraSonicSensor09Command";
CM_ SG_ 2566887991 SetAppCmd "SettingApplicationCommand";
CM_ SG_ 2566887991 ToleranceCorCmd "ToleranceCorrectionCommand";
CM_ SG_ 2566887991 FactoryResetCmd "FactoryResetCommand";
CM_ SG_ 2566887991 UltsSsOpt "UltrasonicSensorOption";
CM_ SG_ 2566887991 UltsBzStopSig "UltrasonicBuzzerStopSignal";
CM_ SG_ 2566887991 BoomCamOpt "BoomCameraOption";
CM_ SG_ 2566887991 UltsBzOffSig "UltrasonicBuzzerOFFSignal";
CM_ SG_ 2566887991 UltsRecognitionDistanceSet "UltrasonicRecognitionDistanceSetting";
CM_ SG_ 2566887991 VhcType2 "VehicleType02";
CM_ SG_ 2566887991 VhcType1 "VehicleType01";
CM_ SG_ 2566887991 TonsOftheTensDigit "TonsOftheTensDigit";
CM_ SG_ 2566887991 TonsOftheUnitsDigit "TonsOftheUnitsDigit";
CM_ SG_ 2566887991 FactoryType "FactoryType";
CM_ SG_ 2566887991 VwMd "ViewMode";
CM_ BO_ 2566888503 "Camera Parameter";
CM_ BO_ 2566888759 "AVM Version";
CM_ SG_ 2566888759 AvmVerYear "AVMVersionYear";
CM_ SG_ 2566888759 AvmVerMonth "AVMVersionMonth";
CM_ SG_ 2566888759 AvmVerDate "AVMVersionDate";
CM_ SG_ 2566888759 AvmVer "AVMVersion";
CM_ BO_ 2566889388 "CHMSL Information";
CM_ BO_ 2566889512 "GP Command";
CM_ SG_ 2566889512 RvsWarnSt "Reverse Warning State";
CM_ SG_ 2566889512 MirrorHtOprtgSig "Mirror Heater Operating Signal";
CM_ SG_ 2566889512 EvMdCmd "EVModeCommand";
CM_ SG_ 2566889512 ObjectSsChmsl "ObjectSensing;CHMSL";
CM_ SG_ 2566889512 KeylessCrankEnbSt "KeylessCrankEnableState";
CM_ SG_ 2566889512 DaacmdSt "DAACModeState";
CM_ SG_ 2566889512 QuickCoolMdSt "QuickCoolingModeState";
CM_ SG_ 2566889512 DzAstMdSt "DozingAssistModeState";
CM_ SG_ 2566889512 KeyPadPri "KeyPadPriority";
CM_ SG_ 2566889512 RpmCmdbyJD "RpmCommandbyJogDial";
CM_ SG_ 2566889512 TractionMdSt "TractionModeState";
CM_ SG_ 2566889512 ExternalSoundCmd "ExternalVoiceCMD(ExternalSound)";
CM_ SG_ 2566889512 EgLckSt "EngineLockState";
CM_ SG_ 2566889512 JduseStforRpm "JogDialUseStateforRpm";
CM_ SG_ 2566889512 AutoIdleMdSt "AutoIdleModeState";
CM_ SG_ 2566889512 WrkMdSt "WorkModeState";
CM_ SG_ 2566889512 PwrMdSt "PowerModeState";
CM_ BO_ 2566889768 "GP Time/Date";
CM_ SG_ 2566889768 LocalHrOfs "Localhouroffset";
CM_ SG_ 2566889768 LocalMinOfs "Localminuteoffset";
CM_ SG_ 2566889768 Year "Year";
CM_ SG_ 2566889768 Day "Day";
CM_ SG_ 2566889768 Mon "Month";
CM_ SG_ 2566889768 Hrs "Hours";
CM_ SG_ 2566889768 Mins "Minutes";
CM_ SG_ 2566889768 Secs "Seconds";
CM_ BO_ 2566890024 "Software Version";
CM_ SG_ 2566890024 AvmSwVer "AVMSWVersion";
CM_ SG_ 2566890024 AvmSwVerYear "AVMSWVersion;Year";
CM_ SG_ 2566890024 AvmSwVerDay "AVMSWVersion;Day";
CM_ SG_ 2566890024 AvmSwVerMon "AVMSWVersion;Month";
CM_ SG_ 2566890024 GpOsSwVer "GPOSSWVersion";
CM_ SG_ 2566890024 GpOsSwVerYear "GPOSSWVersion;Year";
CM_ SG_ 2566890024 GpOsSwVerDay "GPOSSWVersion;Day";
CM_ SG_ 2566890024 GpOsSwVerMon "GPOSSWVersion;Month";
CM_ SG_ 2566890024 GpAppSwVer "GPAPPSWVersion";
CM_ SG_ 2566890024 GpAppSwVerYear "GPAPPSWVersion;Year";
CM_ SG_ 2566890024 GpAppSwVerDay "GPAPPSWVersion;Day";
CM_ SG_ 2566890024 GpAppSwVerMon "GPAPPSWVersion;Month";
CM_ BO_ 2566890280 "Attachment  Flow Command";
CM_ SG_ 2566890280 AttSetFlowVal "AttachmentSettingFlowValue";
CM_ SG_ 2566890280 AttSetSaveFlag "AttachmentSettingSaveFlag";
CM_ SG_ 2566890280 AttNo "AttachmentNumber";
CM_ SG_ 2566890280 AttType "AttachmentType";
CM_ BO_ 2566890536 "2D MG Buzzer Command";
CM_ SG_ 2566890536 MgSoundGudStep "MGSoundGuidanceStep";
CM_ SG_ 2566890536 AlmSt "AlarmState";
CM_ BO_ 2566890561 "2D MG Buzzer Command";
CM_ SG_ 2566890561 MgSoundGudStep "MGSoundGuidanceStep";
CM_ SG_ 2566890561 AlmSt "AlarmState";
CM_ BO_ 2566890792 "GP Command with check sum";
CM_ SG_ 2566890792 MsgChecksum "MessageChecksum";
CM_ SG_ 2566890792 MsgCounter "MessageCounter";
CM_ SG_ 2566890792 OptSetJoyPatternChange "OptSetting;JoystickPatternChange";
CM_ BO_ 2566891041 "ZFIMP";
CM_ BO_ 2566891688 "Converting Angle Value";
CM_ BO_ 2566892072 "Doosan CAN Audio Panel";
CM_ SG_ 2566892072 ReqCallIndex "RequestCallIndex";
CM_ SG_ 2566892072 PairingReq "PairingRequest";
CM_ SG_ 2566892072 HangUpBtn "HangUpButton";
CM_ SG_ 2566892072 DabSel "DABSelect";
CM_ SG_ 2566892072 MdSel "ModeSelect";
CM_ SG_ 2566892072 AdoVolDownSel "AudioVolumeDownSelect";
CM_ SG_ 2566892072 AdoVolUpSel "AudioVolumeUpSelect";
CM_ SG_ 2566892072 BandSel "BandSelect";
CM_ SG_ 2566892072 TalkBtn "TalkButton";
CM_ SG_ 2566892072 AdoTuneDownSel "AudioTuneDownSelect";
CM_ SG_ 2566892072 AdoCallListPopupSt "AudioCallListPopupState";
CM_ SG_ 2566892072 AdoMenuSel "AudioMenuSelect";
CM_ SG_ 2566892072 AdoPowerSel "AudioPowerSelect";
CM_ SG_ 2566892072 AdoP5Sel "AudioP5Select";
CM_ SG_ 2566892072 AdoP6Sel "AudioP6Select";
CM_ SG_ 2566892072 AdoTuneSel "AudioTuneSelect";
CM_ SG_ 2566892072 AdoTuneUpSel "AudioTuneUpSelect";
CM_ SG_ 2566892072 AdoP1Sel "AudioP1Select";
CM_ SG_ 2566892072 AdoP2Sel "AudioP2Select";
CM_ SG_ 2566892072 AdoP3Sel "AudioP3Select";
CM_ SG_ 2566892072 AdoP4Sel "AudioP4Select";
CM_ SG_ 2566892072 AdoAmSel "AudioAMSelect";
CM_ SG_ 2566892072 AdoFmSel "AudioFMSelect";
CM_ SG_ 2566892072 AdoUsbSel "AudioUSBSelect";
CM_ SG_ 2566892072 AdoAuxSel "AudioAUXSelect";
CM_ BO_ 2566892448 "Audio Phone Book List to GP";
CM_ SG_ 2566892448 PhoneBookListText "Phone Book List Text";
CM_ BO_ 2566892704 "Audio Large Index Text";
CM_ SG_ 2566892704 LargeIndexText "Large Index Text";
CM_ BO_ 2566892960 "Audio DLS Text";
CM_ SG_ 2566892960 DabDlsMsg "DAB DLS Message";
CM_ BO_ 2566893216 "Audio Incoming Call Text to GP";
CM_ SG_ 2566893216 IncomingCallText "Incoming Call Text";
CM_ BO_ 2566893472 "Audio Text to GP";
CM_ BO_ 2566893620 "Smart Key Command";
CM_ SG_ 2566893620 Id "SMK ID";
CM_ SG_ 2566893620 SwVer "Software Version";
CM_ SG_ 2566893620 WrnFobImmo "FOB Immobilizer Warning";
CM_ SG_ 2566893620 WrnFobLowBat "FOB Low Battery Warning";
CM_ SG_ 2566893620 WrnNoFob "No Detection FOB Inside Cabin Warning";
CM_ SG_ 2566893620 FobCnt "FOB Counts Registered";
CM_ SG_ 2566893620 FobRgstFdbk "FOB Registration Feedback";
CM_ SG_ 2566893620 PreheatSt "Preheat Status";
CM_ SG_ 2566893620 LampSt "Lamp Status";
CM_ SG_ 2566893620 VentTmpSet "Ventilation Temperature Setting";
CM_ SG_ 2566893620 HvacSt "HVAC Status";
CM_ SG_ 2566893620 DoorLckSt "Door Lock Status";
CM_ BO_ 2566893876 "Smart Key FOB";
CM_ BO_ 2566894154 "TMS Request to Smart Key Data";
CM_ SG_ 2566894154 RmEgIdleTm "Remote Engine Idle Time";
CM_ SG_ 2566894154 RmEgIdleMn "Remote Engine Idle Minutes";
CM_ SG_ 2566894154 Beacon "Beacon";
CM_ SG_ 2566894154 Horn "Horn";
CM_ SG_ 2566894154 DoorRls "Door Release";
CM_ SG_ 2566894154 Lamp "Lamp";
CM_ SG_ 2566894154 RmCrank "Remote Engine Start";
CM_ SG_ 2566894154 VentTmpSet "Ventilation Temperature Setting";
CM_ SG_ 2566894154 Hvac "HVAC";
CM_ SG_ 2566894154 DoorLck "Door Lock";
CM_ BO_ 2566894388 "Smart Key Info";
CM_ SG_ 2566894388 Acc10mUserCheck "ACC 10min User Check";
CM_ SG_ 2566894388 WelcomeSoundSetSt "Welcome Sound Setting Status";
CM_ SG_ 2566894388 ResRmCrank "Result Of Crank";
CM_ SG_ 2566894388 NotWorkinCdt "Not working in this condition";
CM_ SG_ 2566894388 CabTmp "Current Cabin Temperature";
CM_ SG_ 2566894388 RmCrankSt "RemoteRunningStatus";
CM_ SG_ 2566894388 BeaconSt "Beacon State";
CM_ SG_ 2566894388 MtDoorSt "MaintenanceDoorStatus";
CM_ SG_ 2566894388 CabDoorSt "CabinDoorStatus";
CM_ SG_ 2566894388 FobBatSt "FOBBatteryStatus";
CM_ SG_ 2566894388 MchTonage "MachineTonage";
CM_ SG_ 2566894388 MchModel "MachineModel";
CM_ SG_ 2566894388 FobDtt "FOBDetect";
CM_ SG_ 2566894388 KeySt "KeyStatus";
CM_ BO_ 2566896131 "TCU Message5 to VCU";
CM_ SG_ 2566896131 CTLLhRvsTrvlPmpVv "[CTL]LHReverseTravelPumpV/V";
CM_ SG_ 2566896131 CTLLhFwdTrvlPmpVv "[CTL]LHForwardTravelPumpV/V";
CM_ SG_ 2566896131 CTLRhRvsTrvlPmpVv "[CTL]RHReverseTravelPumpV/V";
CM_ SG_ 2566896131 CTLRhFwdTrvlPmpVv "[CTL]RHForwardTravelPumpV/V";
CM_ BO_ 2566896387 "TCU Message4 to VCU";
CM_ SG_ 2566896387 TrkLdTypeAutoShift "Track Loader Type Symbol; Auto shifting";
CM_ SG_ 2566896387 LPumpAngSsCh2 "Left Pump Angle Sensor Ch2";
CM_ SG_ 2566896387 LPumpAngSsCh1 "Left Pump Angle Sensor Ch1";
CM_ SG_ 2566896387 RPumpAngSsCh2 "Right Pump Angle Sensor Ch2";
CM_ SG_ 2566896387 RPumpAngSsCh1 "Right Pump Angle Sensor Ch1";
CM_ SG_ 2566896387 TrkLdTypeSyb2Spd "Track Loader Type Symbol; 2 speed";
CM_ SG_ 2566896387 HstCutOffSVSt "HSTCutOffS/VStatus";
CM_ SG_ 2566896387 TwoSpdSVSt "TwoSpeedS/VStatus";
CM_ SG_ 2566896387 TrkLdTypeSybCreep "TrackLoaderTypeSymbol;Creep";
CM_ BO_ 2566896643 "TCU Handshake Group";
CM_ SG_ 2566896643 TrvlSpdPreset4RvsExtd "Travel Speed Preset 4 Reverse Extended";
CM_ SG_ 2566896643 TrvlSpdPreset4FwdExtd "Travel Speed Preset 4 Forward Extended";
CM_ SG_ 2566896643 TrvlSpdPreset3RvsExtd "Travel Speed Preset 3 Reverse Extended";
CM_ SG_ 2566896643 TrvlSpdPreset3FwdExtd "Travel Speed Preset 3 Forward Extended";
CM_ SG_ 2566896643 TrvlSpdPreset2RvsExtd "Travel Speed Preset 2 Reverse Extended";
CM_ SG_ 2566896643 TrvlSpdPreset2FwdExtd "Travel Speed Preset 2 Forward Extended";
CM_ SG_ 2566896643 TrvlSpdPreset1RvsExtd "Travel Speed Preset 1 Reverse Extended";
CM_ SG_ 2566896643 TrvlSpdPreset1FwdExtd "Travel Speed Preset 1 Forward Extended";
CM_ SG_ 2566896643 JoyStrSsAdj "Joystick Steering Sensitivity Adjustment";
CM_ SG_ 2566896643 TrvlSpdPrmtCor "Setting; Travel Speed Parameter Correction";
CM_ SG_ 2566896643 SetMaxSpdLimit "Setting;MaxSpeedLimit";
CM_ SG_ 2566896643 SetStrDriftCompensation "Setting;SteeringDriftCompensation";
CM_ SG_ 2566896643 SetCreepMaxSpd "Setting;CreepMaxSpeed";
CM_ SG_ 2566896643 SetJoyTrvlRLTrk "Setting;JoystickTravelAct;Right,LeftTrack";
CM_ SG_ 2566896643 TrvlSpdPreset4Rvs "TravelSpeedPreset4Reverse";
CM_ SG_ 2566896643 TrvlSpdPreset4Fwd "TravelSpeedPreset4Forward";
CM_ SG_ 2566896643 TrvlSpdPreset3Rvs "TravelSpeedPreset3Reverse";
CM_ SG_ 2566896643 TrvlSpdPreset3Fwd "TravelSpeedPreset3Forward";
CM_ SG_ 2566896643 TrvlSpdPreset2Rvs "TravelSpeedPreset2Reverse";
CM_ SG_ 2566896643 TrvlSpdPreset2Fwd "TravelSpeedPreset2Forward";
CM_ SG_ 2566896643 TrvlSpdPreset1Rvs "TravelSpeedPreset1Reverse";
CM_ SG_ 2566896643 TrvlSpdPreset1Fwd "TravelSpeedPreset1Forward";
CM_ SG_ 2566896643 TrvlSpdSet "TravelSpeedSet";
CM_ SG_ 2566896643 BrkPdlDecel "BrakePedalDeceleration";
CM_ BO_ 2365570307 "TCU Message1 to VCU";
CM_ SG_ 2365570307 LhTrvlMotorEpprVv "LHTravelMotorEPPRV/V";
CM_ SG_ 2365570307 RhTrvlMotorEpprVv "RHTravelMotorEPPRV/V";
CM_ SG_ 2365570307 LhRvsTrvlPmpEpprVv "LHReverseTravelPumpEPPRV/V";
CM_ SG_ 2365570307 LhFwdTrvlPmpEpprVv "LHForwardTravelPumpEPPRV/V";
CM_ SG_ 2365570307 RhRvsTrvlPmpEpprVv "RHReverseTravelPumpEPPRV/V";
CM_ SG_ 2365570307 RhFwdTrvlPmpEpprVv "RHForwardTravelPumpEPPRV/V";
CM_ SG_ 2365570307 VhcSpd "VehicleSpeed";
CM_ SG_ 2365570307 CurRvsMaxSpd "CurrentReverseMax.Speed";
CM_ SG_ 2365570307 CurFwdMaxSpd "CurrentForwardMax.Speed";
CM_ SG_ 2365570307 Fnr "FNR";
CM_ BO_ 2566897155 "TCU Message2 to VCU";
CM_ SG_ 2566897155 LhTrvlMotorSpdSs "LHTravelMotorSpeedSensor";
CM_ SG_ 2566897155 RhTrvlMotorSpdSs "RHTravelMotorSpeedSensor";
CM_ SG_ 2566897155 LhRvsTrvlPmpPrsSs "LHReverseTravelPumpPressureSensor";
CM_ SG_ 2566897155 LhFwdTrvlPmpPrsSs "LHForwardTravelPumpPressureSensor";
CM_ SG_ 2566897155 RhRvsTrvlPmpPrsSs "RHReverseTravelPumpPressureSensor";
CM_ SG_ 2566897155 RhFwdtPmpPrsSs "RHForwardTravelPumpPressureSensor";
CM_ BO_ 2566897411 "TCU Message3 to VCU";
CM_ SG_ 2566897411 ParkingBrkReqSt "ParkingBrakeRequestState";
CM_ SG_ 2566897411 CurPwrMd "CurrentPowerMode";
CM_ SG_ 2566897411 CurRvsMaxSpd "CurrentReverseMax.Speed";
CM_ SG_ 2566897411 CurFwdMaxSpd "CurrentForwardMax.Speed";
CM_ SG_ 2566897411 BrkAngSs2Pct "BrakeAngleSensor2Percentage";
CM_ SG_ 2566897411 BrkAngSs1Pct "BrakeAngleSensor1Percentage";
CM_ SG_ 2566897411 FootPdlPct "FootPedalPercentage";
CM_ SG_ 2566897411 BrkAngSs2Vlt "BrakeAngleSensor2Voltage";
CM_ SG_ 2566897411 BrkAngSs1Vlt "BrakeAngleSensor1Voltage";
CM_ SG_ 2566897411 EgCtrlDVlt "EngineControlDialVoltage";
CM_ BO_ 2365571105 "VCU Message1 to TCU";
CM_ SG_ 2365571105 MsgChecksum "Message Checksum";
CM_ SG_ 2365571105 MsgCnt "Message Counter";
CM_ SG_ 2365571105 LwIdleUpMd "Low Idle Up Mode";
CM_ SG_ 2365571105 TwoSpdReadySt "Two Speed Ready Status";
CM_ SG_ 2365571105 EgDeratingCtrl "Engine Derating Cotrol";
CM_ SG_ 2365571105 DmsActCmd "DMS Activation Command";
CM_ SG_ 2365571105 CstSpdCtrlReqSpd "Constant Speed Control Requested Speed";
CM_ SG_ 2365571105 HydTmp "HydraulicTemperature";
CM_ SG_ 2365571105 FootPdlPct "FootPedalPercentage";
CM_ SG_ 2365571105 RpmReqMd "RpmRequestMode";
CM_ SG_ 2365571105 ReqRvsMaxSpd "RequestReverseMax.Speed";
CM_ SG_ 2365571105 ReqFwdMaxSpd "RequestForwardMax.Speed";
CM_ SG_ 2365571105 PowMd "PowerMode";
CM_ SG_ 2365571105 IsParking "ParkingSignal";
CM_ SG_ 2365571105 TractionCtrl "TractionControl";
CM_ BO_ 2365571361 "VCU Message2 to TCU";
CM_ SG_ 2365571361 MsgChecksum "Message Checksum";
CM_ SG_ 2365571361 MsgCounter "Message Counter";
CM_ SG_ 2365571361 OprtPresenceSt "Operator Presence Status";
CM_ SG_ 2365571361 EgCtrlDialVlt "Engine Control Dial Voltage";
CM_ BO_ 2365572608 "Transmission of VGT nozzle position frame over CAN";
CM_ SG_ 2365572608 VgtCmdSt "VGTCommandstate";
CM_ SG_ 2365572608 VgtNzPos "VGTnozzleposition(LSB)";
CM_ BO_ 2566901763 "Handshake Data Information";
CM_ SG_ 2566901763 RandomVal "RandomValue";
CM_ BO_ 2566901793 "Handshake Data Information";
CM_ SG_ 2566901793 RandomVal "RandomValue";
CM_ BO_ 2566902049 "Function Setting Data Information";
CM_ SG_ 2566902049 DacTiltAutoMdSel "Setting; DAC Tilt Auto Mode Select";
CM_ SG_ 2566902049 DacLiftAutoMdSel "Setting; DAC Lift Auto Mode Select";
CM_ SG_ 2566902049 BladeLoadTgSet "Blade Load Target Set";
CM_ SG_ 2566902049 OverturnWarn "Option Setting; overturn warning 2.0";
CM_ SG_ 2566902049 EmcvBckSsSet "Setting; eMCV Bucket Sensitivity Setting";
CM_ SG_ 2566902049 MaxFlwRateofElecPwrStrSet "Setting; Maximum flow rate of electric power steering Setting";
CM_ SG_ 2566902049 EmcvArmSsSet "Setting; eMCV Arm Sensitivity Setting";
CM_ SG_ 2566902049 ElecPwrStrSsSet "Setting; electric power steering sensitivity Setting";
CM_ SG_ 2566902049 PriLogicValve "OptionSetting; Priorirty Logic Valve";
CM_ SG_ 2566902049 AdvancedWgh "Option Setting; Advanced Weighing";
CM_ SG_ 2566902049 HydAux2 "OptionSetting; Hydraulic Aux 2	 	";
CM_ SG_ 2566902049 HhSpdDrvMd "OptionSetting; High speed driving mode";
CM_ SG_ 2566902049 SocChgLmt "Setting;SOC charging limit";
CM_ SG_ 2566902049 HeavyAtt "Setting; Heavy Attachment";
CM_ SG_ 2566902049 AutoReturntoDig "Setting; Auto Return to Dig";
CM_ SG_ 2566902049 ExtraOilCool "OptionSetting; Extra Oil Cooler";
CM_ SG_ 2566902049 ArmDumpSplCmdOffset "Arm Dump Spool Command Offset";
CM_ SG_ 2566902049 ArmCrowdSplCmdOffset "Arm Crowd Spool Command Offset";
CM_ SG_ 2566902049 BckDumpSplCmdOffset "Bucket Dump Spool Command Offset";
CM_ SG_ 2566902049 BckCrowdSplCmdOffset "Bucket Crowd Spool Command Offset";
CM_ SG_ 2566902049 BoomDnSplCmdOffset "Boom Down Spool Command Offset";
CM_ SG_ 2566902049 BoomUpSplCmdOffset "Boom Up Spool Command Offset";
CM_ SG_ 2566902049 NonStdTireWhlSizeMn "OptionSetting; Non Standard Tire Wheel Size Manual";
CM_ SG_ 2566902049 StdTireSizeSel "OptionSetting; Standard Tire Size Select";
CM_ SG_ 2566902049 TireMaker "OptionSetting; Tire Maker";
CM_ SG_ 2566902049 FourthCstFlwStep "4th Constant Flow Step";
CM_ SG_ 2566902049 ParallelLiftSsSet "Setting; Parallel Lift Sensitivity Setting";
CM_ SG_ 2566902049 RlsofFlwRstrforCombiOpr "Setting; Option Release of flow restriction for combined operation";
CM_ SG_ 2566902049 RedPrsRmv "Setting; residual pressure removal";
CM_ SG_ 2566902049 GreenBeacon "OptionSetting; Green Beacon";
CM_ SG_ 2566902049 LockValve "OptionSetting; Lock Valve";
CM_ SG_ 2566902049 TiltRttExtra2Ivt "Tilt Rotator - Extra2 inverted";
CM_ SG_ 2566902049 TiltRttExtra1Ivt "Tilt Rotator - Extra1 inverted";
CM_ SG_ 2566902049 TiltRttIvt "Tilt Rotator - Rotate inverted";
CM_ SG_ 2566902049 TiltRttTiltIvt "Tilt Rotator - Tilt inverted";
CM_ SG_ 2566902049 AutoDig "Setting; Auto Digging (Digging Assist)";
CM_ SG_ 2566902049 ShtShiftAst "Setting; Shuttle Shift Assist";
CM_ SG_ 2566902049 OptShtShiftAst "OptionSetting; Shuttle Shift Assist";
CM_ SG_ 2566902049 Actjoy "Setting; the active joystick";
CM_ SG_ 2566902049 MultiFncBtnSelforWld "Multi Function Button Select for WLD";
CM_ SG_ 2566902049 KickDnShiftMd "Setting; Kick Down Shift Mode";
CM_ SG_ 2566902049 BckShake "Setting; Bucket Shake";
CM_ SG_ 2566902049 ElecExcvCableType "OptionSetting; Electric Excavator (Cable Type)";
CM_ SG_ 2566902049 EStop "OptionSetting; E-stop";
CM_ SG_ 2566902049 LineRedPrsRmvSet "OptionSetting; Option line residual pressure removal Setting";
CM_ SG_ 2566902049 OutTrgFR "Setting; Outrigger FR";
CM_ SG_ 2566902049 OutTrgFL "Setting; Outrigger FL";
CM_ SG_ 2566902049 RrDz "Setting; Rear Dozer";
CM_ SG_ 2566902049 FrDz "Setting; Front Dozer";
CM_ SG_ 2566902049 RrDzorOutTrg "OptionSetting; Rear Dozer or Outrigger ";
CM_ SG_ 2566902049 FrDzorOutTrg "OptionSetting; Front Dozer or Outrigger ";
CM_ SG_ 2566902049 APMdPwrRngMax "Setting; AP Mode Power Range(Max)";
CM_ SG_ 2566902049 APMdPwrRngMin "Setting; AP Mode Power Range(Min)";
CM_ SG_ 2566902049 AgsIntervalTm "Setting; AGS Interval Time";
CM_ SG_ 2566902049 AgsOprTm "Setting; AGS Operating Time";
CM_ SG_ 2566902049 RrAxleTirePrsTh "Setting; Rear Axle Tire Pressure Threshold";
CM_ SG_ 2566902049 FrAxleTirePrsTh "Setting; Front Axle Tire Pressure Threshold";
CM_ SG_ 2566902049 OutTrgRR "Setting; Outrigger RR";
CM_ SG_ 2566902049 OutTrgRL "Setting; Outrigger RL";
CM_ SG_ 2566902049 CTLCanopy "Option Setting; CTL Canopy";
CM_ SG_ 2566902049 Radar "Option Setting; Radar";
CM_ SG_ 2566902049 Savm "Option Setting; SAVM";
CM_ SG_ 2566902049 FineSwg "Option Setting; Fine Swing";
CM_ SG_ 2566902049 HhlandOpt "Setting; Highland Option(ETP)";
CM_ SG_ 2566902049 SmartAssist "Option Setting; Smart Assist";
CM_ SG_ 2566902049 PhmPremium "OptionSetting; PHM Premium";
CM_ SG_ 2566902049 PhmBasic "OptionSetting; PHM Basic";
CM_ SG_ 2566902049 RrSspnAutoMd "Setting; Rear Suspension Auto Mode";
CM_ SG_ 2566902049 FrSspnMd "Setting; Front Suspension Mode";
CM_ SG_ 2566902049 AdtMaxCriterionWghVal "ADT Max Criterion Weight Value";
CM_ SG_ 2566902049 SetOwdActn "Setting; OWD Activation";
CM_ SG_ 2566902049 RvsFanDurationTmData "Reverse Fan Duration Time Data";
CM_ SG_ 2566902049 OptSetMaterialHandlerFr "OptionSetting; Material Handler Front Option";
CM_ SG_ 2566902049 LHJoyStrSet "LH Joystick Steering Setting";
CM_ SG_ 2566902049 AutoHold "Setting; Auto Hold";
CM_ SG_ 2566902049 SetStickStr "Setting; Stick Steering";
CM_ SG_ 2566902049 OptSetCdsRvsFanAutoPrd "Setting;CondenserReverseFanAutomaticActPeriod";
CM_ SG_ 2566902049 OptSetTrailer "OptSetting;Trailer";
CM_ SG_ 2566902049 OptSetEscortWrkLmp "Setting;EscortWorkingLamp";
CM_ SG_ 2566902049 OptSetCdsRvsFanMd "Setting;CondenserReverseFanMode";
CM_ SG_ 2566902049 OptSetRttDir "Setting;RotatingActDirection";
CM_ SG_ 2566902049 OptSetAdvLv "Setting;AdvancedLeveling";
CM_ SG_ 2566902049 OptSetGndSaw "OptSetting;GroundSAW";
CM_ SG_ 2566902049 OptSetTpms "Setting;TPMS";
CM_ SG_ 2566902049 OptSetAutoBrkrSens "Setting;AutoBreakerSensitivity";
CM_ SG_ 2566902049 OptSetAntiBlankFire "CMD;AntiBlankFireActivate";
CM_ SG_ 2566902049 OptSetJoyBoom "Setting;JoystickWorkAct;Boom";
CM_ SG_ 2566902049 OptSetJoyTilt "Setting;JoystickWorkAct;Tilt";
CM_ SG_ 2566902049 OptSetCoolFanType "OptionSetting; Cooling FAN Type";
CM_ SG_ 2566902049 FourthCstFlwSet "4th Constant Flow Setting";
CM_ SG_ 2566902049 OptParallelLiftActn "Setting; Parallel Lift Activation ";
CM_ SG_ 2566902049 OptSetHhFw "OptSetting;HighFlow";
CM_ SG_ 2566902049 OptSet3DMgMc3rd "OptSetting;3rdParty3DMGMC";
CM_ SG_ 2566902049 OptSetRrCabLmp "OptSetting;ReverseCabinLamp";
CM_ SG_ 2566902049 OptSetDzMc "OptSetting;DozingMCSetting";
CM_ SG_ 2566902049 OptSetTrqCvtLckUp "OptSetting;TorqueConverterLockUp";
CM_ SG_ 2566902049 OptSetTwThwDir "2wayThumb WheelActDirectionSetting";
CM_ SG_ 2566902049 OptSetOptPdlType2 "OptSetting;OptPedalType2";
CM_ SG_ 2566902049 OptSetMaxTrvlSpd "MaxTravelSpeedSet";
CM_ SG_ 2566902049 OptSetRollSlope "SetRollSlope";
CM_ SG_ 2566902049 OptSetDaac "OptSetting;DAACSetting";
CM_ SG_ 2566902049 OptSetRvsLmpFuncAct "Setting;ReverseLampFunctionActivation";
CM_ SG_ 2566902049 OptSetBladeAngSens "BladeAngleSensitivity";
CM_ SG_ 2566902049 OptSetRaiseDnSens "BladeRaiseDownSensitivity";
CM_ SG_ 2566902049 OptSetBladeTiltSens "BladeTiltSensitivity";
CM_ SG_ 2566902049 OptSetPchSlope "SetPitchSlope";
CM_ SG_ 2566902049 OptSetMrrHt "OptSetting;MirrorHeater";
CM_ SG_ 2566902049 OptSetQckCoolMd "Setting;QuickCoolingMode";
CM_ SG_ 2566902049 RttOptSet "RotatingOptSetting";
CM_ SG_ 2566902049 OptSetTrvlStrgtPdl "OptSetting;TravelStraightPedal";
CM_ SG_ 2566902049 OptSetJoyType "Setting;JoystickType";
CM_ SG_ 2566902049 OptSetAttCtrl "OptSetting;Attachment조작Opt;PedalJoystickSelect;Rotating";
CM_ SG_ 2566902049 OptSetTiltRttType "Setting;TiltRotatorType";
CM_ SG_ 2566902049 OptSetArtiBoom "OptSetting;ArtiBoom";
CM_ SG_ 2566902049 OptSetDzBlade "OptSetting;DozerBlade";
CM_ SG_ 2566902049 OptSetHhLift "OptSetting;HighLift";
CM_ SG_ 2566902049 OptSetJoyPtnChange "OptSetting;JoystickPatternChange";
CM_ SG_ 2566902049 OptSetTrqCvtLookUp "TorqueConvertorLockUpSetting";
CM_ SG_ 2566902049 OptSetDhlAuto "DHLAutoSetting";
CM_ SG_ 2566902049 OptSet3DMG "OptSetting;3DMG";
CM_ SG_ 2566902049 OptSetTrvlSwgAlm "Setting;TravelSwingAlarmSetting";
CM_ SG_ 2566902049 OptSetLaserReceiver "OptionSetting; Laser Receiver";
CM_ SG_ 2566902049 OptSetMgMc "OptionSetting; MG/MC";
CM_ SG_ 2566902049 OptSetDKey "OptionSetting; Digital key";
CM_ SG_ 2566902049 WghWith3D "Option Setting; Weighing with 3D";
CM_ SG_ 2566902049 OptSetWirelessChg "OptionSetting; Wireless Charger";
CM_ SG_ 2566902049 OptSetAgs "OptionSetting; AGS";
CM_ SG_ 2566902049 OptSetCamLmp "OptionSetting; Camera Lamp";
CM_ SG_ 2566902049 OptSetWiperType "OptionSetting; Wiper Type";
CM_ SG_ 2566902049 OptSetPrsCtrl "OptSetting;PressureControlActivation";
CM_ SG_ 2566902049 OptSetRollOvr "OptSetting;Rollover";
CM_ SG_ 2566902049 OptSet4WhlStr "OptSetting;4WheelSteering";
CM_ SG_ 2566902049 OptSetSpool4 "OptSetting;4THSPOOL";
CM_ SG_ 2566902049 ThirdCstFlwSet "3rd Constant Flow Setting";
CM_ SG_ 2566902049 ThirdCstFlwStep "3rd Constant Flow Step";
CM_ SG_ 2566902049 OptSetLisRvsOprSpd "LISReverseOperationVelocity";
CM_ SG_ 2566902049 OptSetFrCabLmp "OptSetting;FrontCabinLamp";
CM_ SG_ 2566902049 OptSetOutRr "OptSetting;OutriggerRR";
CM_ SG_ 2566902049 OptSetOutRlRrDz "OptSetting;OutriggerRLorRearDozer";
CM_ SG_ 2566902049 OptSetOutFr "OptSetting;OutriggerFR";
CM_ SG_ 2566902049 OptSetOutFlFrDz "OptSetting;OutriggerFLorFrontDozer";
CM_ SG_ 2566902049 OptSetJoyStr "Joystick Steering Setting";
CM_ SG_ 2566902049 OptSetRvsTrvlSpdLmt "Reverse TravelingSpeedLimit";
CM_ SG_ 2566902049 OptSetEmcvBoomDnImpactPrevent "eMCVSetting;BoomDownImpactPreventionFunctionActivation";
CM_ SG_ 2566902049 OptSetEmcvBoomUpImpactPrevent "eMCVSetting;BoomUpImpactPreventionFunctionActivation";
CM_ SG_ 2566902049 OptSetEmcvBckDumpImpactPrevent "eMCVSetting;BucketDumpImpactPreventionFunctionActivation";
CM_ SG_ 2566902049 OptSetEmcvBckCrowdImpactPrevent "eMCVSetting;BucketCrowdImpactPreventionFunctionActivation";
CM_ SG_ 2566902049 OptSetEmcvBckSens "eMCVSetting;BucketSensitivity";
CM_ SG_ 2566902049 OptSetEmcvBoomSens "eMCVSetting;BoomSensitivity";
CM_ SG_ 2566902049 OptSetEstrJoySens "E-SteeringJoystickSensitivity";
CM_ SG_ 2566902049 OptSetWrkLis "WorkingLISSet";
CM_ SG_ 2566902049 OptSetLcInVal "LCInputValue";
CM_ SG_ 2566902049 OptSetR2InVal "R2InputValue";
CM_ SG_ 2566902049 OptSetR1InVal "R1InputValue";
CM_ SG_ 2566902049 OptSetBckWghInVlue "BucketWeightInputValue";
CM_ SG_ 2566902049 OptSetBoomWghInVal "BoomWeightInputValue";
CM_ SG_ 2566902049 OptSetMaxCritWghVal "MaxCriterionWeightValue";
CM_ SG_ 2566902049 OptSetHalfCritWghVal "HalfCriterionWeightValue";
CM_ SG_ 2566902049 OptSetElecStr "OptSetting;Electric Steering";
CM_ SG_ 2566902049 OptSetRvsFan "OptSetting;ReverseFan";
CM_ SG_ 2566902049 OptSetRcw "OptSetting;RCW(RemovalCounterWeight)";
CM_ SG_ 2566902049 OptSetQckCoupler "OptSetting;QuickCoupler";
CM_ SG_ 2566902049 OptSetTrvlOrSwgAlm "OptSetting;Travel/SwingAlarm";
CM_ SG_ 2566902049 OptSetSmk "OptSetting;SmartKey";
CM_ SG_ 2566902049 OptSetOwd "OptSetting;OWD";
CM_ SG_ 2566902049 OptSetMchNameInit "MachineNameInitializing";
CM_ SG_ 2566902049 OptSetEmvcPmcv "OptSetting;eMCV/pMCV";
CM_ SG_ 2566902049 OptSetAebReq "Setting:AEBRequest";
CM_ SG_ 2566902049 OptSetRvsFanOn "ReverseFanActRequest";
CM_ SG_ 2566902049 OptSetRvsFanMd "ReverseFanModeSetting";
CM_ SG_ 2566902049 OptSetWhgWld "OptSetting;Weighing for WLD";
CM_ SG_ 2566902049 OptSetHydrostatCalbCmd "HydrostatCalibrationCMD";
CM_ SG_ 2566902049 OptSetClutchCalbCmd "ClutchCalibrationCMD";
CM_ SG_ 2566902049 OptSetEmgMd "Activation;EmergencyMode";
CM_ SG_ 2566902049 OptSetCreepAct "Activation;CreepActivation";
CM_ SG_ 2566902049 OptSetThw "OptSetting;ThumbWheel";
CM_ SG_ 2566902049 OptSetAxleOilCool "OptSetting;AxleOilCooler";
CM_ SG_ 2566902049 OptSetAngSs "Setting:AngleSensorTuning";
CM_ SG_ 2566902049 OptSetBrkPdlCalb "Setting:BrakePedalCalibation";
CM_ SG_ 2566902049 OptSetCreepGr "CreepGear";
CM_ SG_ 2566902049 OptSetLisOprSpd "LISOperationVelocity";
CM_ SG_ 2566902049 OptSetRvsFanTm "ReverseFanTimeData";
CM_ SG_ 2566902049 OptSetLis "OptSetting;LIS";
CM_ SG_ 2566902049 OptSetEmgStr "OptSetting;EmergencySteering";
CM_ SG_ 2566902049 OptSetDhl "OptSetting;DHL";
CM_ SG_ 2566902049 OptSetFnr2LeverType "2ndFnRLeverType";
CM_ SG_ 2566902049 OptSetTrmsLmtGr "TransmissionLimitGear";
CM_ SG_ 2566902049 OptSetTransBck "OptSetting;TransparentBucket";
CM_ SG_ 2566902049 OptSetItgtFltBoom "OptSetting;InteligentFloatingBoom";
CM_ SG_ 2566902049 OptSetBeacon "OptSetting;Beacon";
CM_ SG_ 2566902049 OptSetMultiFuncBtnSel "MultiFunctionButtonSelect";
CM_ SG_ 2566902049 OptSetAutoIdle "AutoidleFunctionActivation";
CM_ SG_ 2566902049 MchNo11 "Machine Name #11";
CM_ SG_ 2566902049 MchNo10 "Machine Name #10";
CM_ SG_ 2566902049 MchNo9 "Machine Name #9";
CM_ SG_ 2566902049 MchNo8 "Machine Name #8";
CM_ SG_ 2566902049 MchNo7 "Machine Name #7";
CM_ SG_ 2566902049 MchNo6 "Machine Name #6";
CM_ SG_ 2566902049 MchNo5 "Machine Name #5";
CM_ SG_ 2566902049 MchNo4 "Machine Name #4";
CM_ SG_ 2566902049 MchNo3 "Machine Name #3";
CM_ SG_ 2566902049 MchNo2 "Machine Name #2";
CM_ SG_ 2566902049 MchNo1 "MachineName#1";
CM_ SG_ 2566902049 AutoIdleTm "AutoIldeTimedata";
CM_ SG_ 2566902049 BrkrOprTm "BreakerOperationTimedata";
CM_ SG_ 2566902049 OptSetAutoShutOffTm "AutoShutOffTimeData";
CM_ SG_ 2566902049 OptSetAutoShutOff "AutoShutOffEnableState";
CM_ SG_ 2566902049 OptSetAutoShutOffCancel "AutoShutOffCancelCMD";
CM_ SG_ 2566902049 OptSetAutoIdleRpmTmp "TemperatureAutoIdleRpmChangeActivation";
CM_ SG_ 2566902049 OptSetSpc "SPCSetting";
CM_ SG_ 2566902049 OptSetVoiceWrnCmd "ExternalVoiceWarningCMD";
CM_ SG_ 2566902049 OptSetBoomSwgUSe "BoomSwingFunctionUsed or not";
CM_ SG_ 2566902049 OptSetTrvl2PmpCmbRls "Travel2PumpCombinationRelease";
CM_ SG_ 2566902049 OptSetTrvl1PmpUse "Travel1PumpUsed or not";
CM_ SG_ 2566902049 OptSetTrmsMaxSpdLmtChk "OptSetting;TMMaxSpeedLimitSetting";
CM_ SG_ 2566902049 OptSetHhAlt "OptSetting;High MountainOpt";
CM_ SG_ 2566902049 OptSetRipperOpt "OptSetting;RipperOpt";
CM_ SG_ 2566902049 OptSetRttOpt "OptSetting;RotatingOpt";
CM_ SG_ 2566902049 OptSetJoyThwRtt "JoystickThumb WheelSwitchAct;Rotating";
CM_ SG_ 2566902049 OptSetJoyThwTw "JoystickThumb WheelSwitchAct;2Way";
CM_ SG_ 2566902049 OptSetTw "2WayOptSetting";
CM_ SG_ 2566902049 OptSetOptPdl "OptSetting;OptPedal";
CM_ SG_ 2566902049 OptSetAttPdlJoySel "OptSetting;AttachmentOpt;PedalJoystickSelect";
CM_ SG_ 2566902049 OptSet2Pmp "OptSetting;2PumpOpt";
CM_ SG_ 2566902049 OptSetAttTw "OptSetting;AttachmentOpt;Twoway";
CM_ SG_ 2566902049 OptSetAttBrkr "OptSetting;AttachmentOpt;Breaker";
CM_ SG_ 2566902049 OptSetKeylessUse "OptSetting:KeylessUse(UserMenu)";
CM_ SG_ 2566902049 OptSetKeyless "OptSetting;KeylessSetting";
CM_ SG_ 2566902049 OptSetWiper "OptSetting;WiperSetting";
CM_ SG_ 2566902049 OptSetTrvlMotOvrHtWrn "OptSetting;TravelMotorOverHeatWarning";
CM_ SG_ 2566902049 OptSetFnrDefault "Setting;FNRDefaultSetting";
CM_ SG_ 2566902049 OptSetFnrSel "Setting;FNR Select";
CM_ SG_ 2566902049 OptSetCanTypeCmbSw "OptSetting;CANtypeCombi.Switch";
CM_ SG_ 2566902049 UserDtIdx "UserDataIndex[0]";
CM_ SG_ 2566902049 VhcSerialNo "VehicleSerialNumber";
CM_ SG_ 2566902049 OptSetAttWghFactor "Setting;AttachmentWeightFactor";
CM_ SG_ 2566902049 OptSetCanTypeFuelSs "Setting;CANTypeFuelSensor";
CM_ SG_ 2566902049 OptSetSubBrkLmp "Setting;Sub Breaker Lamp";
CM_ SG_ 2566902049 TiltRttMd "TiltRotatorMode";
CM_ SG_ 2566902049 USerLckUnlockSt "UserLOCK/UNLOCKState";
CM_ SG_ 2566902049 UserPw "UserPASSWORD";
CM_ SG_ 2566902049 OptWgh2D "OptSetting;Weighing with 2D";
CM_ SG_ 2566902049 OptMC "OptSetting;MCOption";
CM_ SG_ 2566902049 OptEgPostHtAct "OptSetting;EnginePost-HeatingActivation";
CM_ SG_ 2566902049 Opt2DMG "OptSetting;2DMG";
CM_ SG_ 2566902049 AdminUse2 "AdminUse";
CM_ SG_ 2566902049 AdminUse1 "AdminUse";
CM_ SG_ 2566902049 AdminUse0 "AdminUse";
CM_ SG_ 2566902049 OwnerPw0UpTm "OwnerPASSWORD_Up Time";
CM_ SG_ 2566902049 OwnerPw0Use "OwnerPASSWORD_User Used or not";
CM_ SG_ 2566902049 OwnerPw0 "OwnerPASSWORD[0]";
BA_DEF_ BO_  "Channel" STRING ;
BA_DEF_ BO_  "VssMsg" STRING ;
BA_DEF_ SG_  "VssSig" STRING ;
BA_DEF_ BO_  "GenMsgCycleTime" INT 0 65535;
BA_DEF_ SG_  "SystemSignalLongSymbol" STRING ;
BA_DEF_DEF_  "Channel" "";
BA_DEF_DEF_  "VssMsg" "";
BA_DEF_DEF_  "VssSig" "";
BA_DEF_DEF_  "GenMsgCycleTime" 0;
BA_DEF_DEF_  "SystemSignalLongSymbol" "";
BA_ "VssMsg" BO_ 2566879562 "Mch.TGU.TGUID";
BA_ "Channel" BO_ 2566879562 "can1";
BA_ "VssMsg" BO_ 2583645002 "Mch.TGU.GPSINFO";
BA_ "Channel" BO_ 2583645002 "can1";
BA_ "VssMsg" BO_ 2583644490 "Mch.TGU.CINFO";
BA_ "Channel" BO_ 2583644490 "can1";
BA_ "VssMsg" BO_ 2566878282 "Mch.TGU.SAT";
BA_ "Channel" BO_ 2566878282 "can1";
BA_ "GenMsgCycleTime" BO_ 2566878794 100;
BA_ "VssMsg" BO_ 2566878794 "Mch.TGU.TSEC";
BA_ "Channel" BO_ 2566878794 "can1";
BA_ "GenMsgCycleTime" BO_ 2583644746 1000;
BA_ "VssMsg" BO_ 2583644746 "Mch.TGU.TGUTM";
BA_ "Channel" BO_ 2583644746 "can1";
BA_ "VssMsg" BO_ 2566879272 "Mch.GP.TMSTP";
BA_ "Channel" BO_ 2566879272 "can1";
BA_ "VssMsg" BO_ 2566879306 "Mch.TGU.TMSTP";
BA_ "Channel" BO_ 2566879306 "can1";
BA_ "GenMsgCycleTime" BO_ 2566879818 100;
BA_ "VssMsg" BO_ 2566879818 "Mch.TGU.DKLI";
BA_ "Channel" BO_ 2566879818 "can1";
BA_ "VssMsg" BO_ 2566880074 "Mch.TGU.DKLD";
BA_ "Channel" BO_ 2566880074 "can1";
BA_ "VssMsg" BO_ 2566880296 "Mch.GP.DKSEL";
BA_ "Channel" BO_ 2566880296 "can1";
BA_ "VssMsg" BO_ 2566880586 "Mch.TGU.TACK";
BA_ "Channel" BO_ 2566880586 "can1";
BA_ "VssMsg" BO_ 2566880842 "Mch.TGU.TMSPUC";
BA_ "Channel" BO_ 2566880842 "can1";
BA_ "VssMsg" BO_ 2566881064 "Mch.GP.TMSPP";
BA_ "Channel" BO_ 2566881064 "can1";
BA_ "VssMsg" BO_ 2566881098 "Mch.TGU.TMSPP";
BA_ "Channel" BO_ 2566881098 "can1";
BA_ "GenMsgCycleTime" BO_ 2566883328 1000;
BA_ "VssMsg" BO_ 2566883328 "Mch.ECU.SCR2";
BA_ "Channel" BO_ 2566883328 "can1";
BA_ "VssMsg" BO_ 2583625761 "Mch.MCU.AASI";
BA_ "Channel" BO_ 2583625761 "can1";
BA_ "VssMsg" BO_ 2583626017 "Mch.MCU.AAAI";
BA_ "Channel" BO_ 2583626017 "can1";
BA_ "VssMsg" BO_ 2583626273 "Mch.MCU.ADSI";
BA_ "Channel" BO_ 2583626273 "can1";
BA_ "VssMsg" BO_ 2583626529 "Mch.MCU.ADAI";
BA_ "Channel" BO_ 2583626529 "can1";
BA_ "GenMsgCycleTime" BO_ 2566884897 200;
BA_ "VssMsg" BO_ 2566884897 "Mch.MCU.TIG1";
BA_ "Channel" BO_ 2566884897 "can1";
BA_ "GenMsgCycleTime" BO_ 2566885153 200;
BA_ "VssMsg" BO_ 2566885153 "Mch.MCU.TIG2";
BA_ "Channel" BO_ 2566885153 "can1";
BA_ "VssMsg" BO_ 2566885409 "Mch.MCU.QRCI";
BA_ "Channel" BO_ 2566885409 "can1";
BA_ "VssMsg" BO_ 2566885665 "Mch.MCU.ECORI";
BA_ "Channel" BO_ 2566885665 "can1";
BA_ "GenMsgCycleTime" BO_ 2566886586 100;
BA_ "VssMsg" BO_ 2566886586 "Mch.RDRR.ROZI";
BA_ "Channel" BO_ 2566886586 "can2";
BA_ "GenMsgCycleTime" BO_ 2566886587 100;
BA_ "VssMsg" BO_ 2566886587 "Mch.RDLH.ROZI";
BA_ "Channel" BO_ 2566886587 "can2";
BA_ "GenMsgCycleTime" BO_ 2566886588 100;
BA_ "VssMsg" BO_ 2566886588 "Mch.RDRH.ROZI";
BA_ "Channel" BO_ 2566886588 "can2";
BA_ "GenMsgCycleTime" BO_ 2566886842 100;
BA_ "VssMsg" BO_ 2566886842 "Mch.RDRR.ROI";
BA_ "Channel" BO_ 2566886842 "can2";
BA_ "GenMsgCycleTime" BO_ 2566886843 100;
BA_ "VssMsg" BO_ 2566886843 "Mch.RDLH.ROI";
BA_ "Channel" BO_ 2566886843 "can2";
BA_ "GenMsgCycleTime" BO_ 2566886844 100;
BA_ "VssMsg" BO_ 2566886844 "Mch.RDRH.ROI";
BA_ "Channel" BO_ 2566886844 "can2";
BA_ "GenMsgCycleTime" BO_ 2566886952 100;
BA_ "VssMsg" BO_ 2566886952 "Mch.GP.AVMVM";
BA_ "Channel" BO_ 2566886952 "can2";
BA_ "VssMsg" BO_ 2566887223 "Mch.AVM.AVMSI";
BA_ "Channel" BO_ 2566887223 "can2";
BA_ "GenMsgCycleTime" BO_ 2566887479 50;
BA_ "VssMsg" BO_ 2566887479 "Mch.AVM.AVMUS";
BA_ "Channel" BO_ 2566887479 "can2";
BA_ "GenMsgCycleTime" BO_ 2566887720 1000;
BA_ "VssMsg" BO_ 2566887720 "Mch.GP.AVMRM";
BA_ "Channel" BO_ 2566887720 "can1";
BA_ "VssMsg" BO_ 2566887991 "Mch.AVM.AVMSM";
BA_ "Channel" BO_ 2566887991 "can2";
BA_ "VssMsg" BO_ 2566888503 "Mch.AVM.AVMCP";
BA_ "Channel" BO_ 2566888503 "can1";
BA_ "VssMsg" BO_ 2566888759 "Mch.AVM.AVMVER";
BA_ "Channel" BO_ 2566888759 "can1";
BA_ "VssMsg" BO_ 2566889388 "Mch.CHMSL.CHMSLI";
BA_ "Channel" BO_ 2566889388 "can1";
BA_ "GenMsgCycleTime" BO_ 2566889512 100;
BA_ "VssMsg" BO_ 2566889512 "Mch.GP.GPCMD";
BA_ "Channel" BO_ 2566889512 "can1";
BA_ "GenMsgCycleTime" BO_ 2566889768 1000;
BA_ "VssMsg" BO_ 2566889768 "Mch.GP.GPTD";
BA_ "Channel" BO_ 2566889768 "can1";
BA_ "VssMsg" BO_ 2566890024 "Mch.GP.SVGP";
BA_ "Channel" BO_ 2566890024 "can1";
BA_ "GenMsgCycleTime" BO_ 2566890280 200;
BA_ "VssMsg" BO_ 2566890280 "Mch.GP.ATTFC";
BA_ "Channel" BO_ 2566890280 "can1";
BA_ "GenMsgCycleTime" BO_ 2566890536 50;
BA_ "VssMsg" BO_ 2566890536 "Mch.GP.MG2DBC";
BA_ "Channel" BO_ 2566890536 "can1";
BA_ "GenMsgCycleTime" BO_ 2566890561 50;
BA_ "VssMsg" BO_ 2566890561 "Mch.GW.MG2DBC";
BA_ "Channel" BO_ 2566890561 "can1";
BA_ "GenMsgCycleTime" BO_ 2566890792 100;
BA_ "VssMsg" BO_ 2566890792 "Mch.GP.GPCCS";
BA_ "Channel" BO_ 2566890792 "can1";
BA_ "GenMsgCycleTime" BO_ 2566891041 100;
BA_ "VssMsg" BO_ 2566891041 "Mch.MCU.ZFIMP";
BA_ "Channel" BO_ 2566891041 "can1";
BA_ "GenMsgCycleTime" BO_ 2566891688 100;
BA_ "VssMsg" BO_ 2566891688 "Mch.CTC.CAV";
BA_ "Channel" BO_ 2566891688 "can1";
BA_ "VssMsg" BO_ 2566892072 "Mch.GP.DCAP";
BA_ "Channel" BO_ 2566892072 "can1";
BA_ "VssMsg" BO_ 2566892448 "Mch.Audio.APLGP";
BA_ "Channel" BO_ 2566892448 "can1";
BA_ "VssMsg" BO_ 2566892704 "Mch.Audio.ALITGP";
BA_ "Channel" BO_ 2566892704 "can1";
BA_ "VssMsg" BO_ 2566892960 "Mch.Audio.ADLSGP";
BA_ "Channel" BO_ 2566892960 "can1";
BA_ "VssMsg" BO_ 2566893216 "Mch.Audio.AICTGP";
BA_ "Channel" BO_ 2566893216 "can1";
BA_ "VssMsg" BO_ 2566893472 "Mch.Audio.ATG";
BA_ "Channel" BO_ 2566893472 "can1";
BA_ "GenMsgCycleTime" BO_ 2566893620 100;
BA_ "VssMsg" BO_ 2566893620 "Mch.SMK.SMKC";
BA_ "Channel" BO_ 2566893620 "can1";
BA_ "VssMsg" BO_ 2566893876 "Mch.SMK.SMKFOB";
BA_ "Channel" BO_ 2566893876 "can1";
BA_ "VssMsg" BO_ 2566894154 "Mch.TGU.SMKCMD";
BA_ "Channel" BO_ 2566894154 "can1";
BA_ "GenMsgCycleTime" BO_ 2566894388 1000;
BA_ "VssMsg" BO_ 2566894388 "Mch.SMK.SMKI";
BA_ "Channel" BO_ 2566894388 "can1";
BA_ "GenMsgCycleTime" BO_ 2566896131 100;
BA_ "VssMsg" BO_ 2566896131 "Mch.TCU.TM5V";
BA_ "Channel" BO_ 2566896131 "can1";
BA_ "GenMsgCycleTime" BO_ 2566896387 100;
BA_ "VssMsg" BO_ 2566896387 "Mch.TCU.TM4V";
BA_ "Channel" BO_ 2566896387 "can1";
BA_ "VssMsg" BO_ 2566896643 "Mch.TCU.TCUHG";
BA_ "Channel" BO_ 2566896643 "can1";
BA_ "GenMsgCycleTime" BO_ 2365570307 100;
BA_ "VssMsg" BO_ 2365570307 "Mch.TCU.TM1V";
BA_ "Channel" BO_ 2365570307 "can1";
BA_ "GenMsgCycleTime" BO_ 2566897155 100;
BA_ "VssMsg" BO_ 2566897155 "Mch.TCU.TM2V";
BA_ "Channel" BO_ 2566897155 "can1";
BA_ "GenMsgCycleTime" BO_ 2566897411 10;
BA_ "VssMsg" BO_ 2566897411 "Mch.TCU.TM3V";
BA_ "Channel" BO_ 2566897411 "can1";
BA_ "GenMsgCycleTime" BO_ 2365571105 100;
BA_ "VssMsg" BO_ 2365571105 "Mch.MCU.VM1T";
BA_ "Channel" BO_ 2365571105 "can1";
BA_ "GenMsgCycleTime" BO_ 2365571361 100;
BA_ "VssMsg" BO_ 2365571361 "Mch.MCU.VM2T";
BA_ "Channel" BO_ 2365571361 "can1";
BA_ "GenMsgCycleTime" BO_ 2365572608 10;
BA_ "VssMsg" BO_ 2365572608 "Mch.ECU.VGTPosCmd";
BA_ "Channel" BO_ 2365572608 "can1";
BA_ "VssMsg" BO_ 2566901763 "Mch.TCU.HSDI";
BA_ "Channel" BO_ 2566901763 "can1";
BA_ "VssMsg" BO_ 2566901793 "Mch.MCU.HSDI";
BA_ "Channel" BO_ 2566901793 "can1";
BA_ "VssMsg" BO_ 2566902049 "Mch.MCU.FSDI";
BA_ "Channel" BO_ 2566902049 "can1";
BA_ "VssSig" SG_ 2566879562 ProdDt "Mch.TGU.TGUID.ProdDt";
BA_ "VssSig" SG_ 2566879562 TguId "Mch.TGU.TGUID.TguId";
BA_ "VssSig" SG_ 2566879562 TypeCd "Mch.TGU.TGUID.TypeCd";
BA_ "VssSig" SG_ 2583645002 GpsSt "Mch.TGU.GPSINFO.GpsSt";
BA_ "VssSig" SG_ 2583645002 NoOfGpsSat "Mch.TGU.GPSINFO.NoOfGpsSat";
BA_ "VssSig" SG_ 2583645002 Z "Mch.TGU.GPSINFO.Z";
BA_ "VssSig" SG_ 2583645002 Y "Mch.TGU.GPSINFO.Y";
BA_ "VssSig" SG_ 2583645002 X "Mch.TGU.GPSINFO.X";
BA_ "VssSig" SG_ 2583644490 GsmdBm "Mch.TGU.CINFO.GsmdBm";
BA_ "VssSig" SG_ 2583644490 GsmType "Mch.TGU.CINFO.GsmType";
BA_ "VssSig" SG_ 2583644490 CurNw "Mch.TGU.CINFO.CurNw";
BA_ "VssSig" SG_ 2583644490 TmnIpAdr "Mch.TGU.CINFO.TmnIpAdr";
BA_ "VssSig" SG_ 2583644490 ServerAdr "Mch.TGU.CINFO.ServerAdr";
BA_ "VssSig" SG_ 2583644490 Apn "Mch.TGU.CINFO.Apn";
BA_ "VssSig" SG_ 2583644490 Imei "Mch.TGU.CINFO.Imei";
BA_ "VssSig" SG_ 2583644490 SimIccid "Mch.TGU.CINFO.SimIccid";
BA_ "VssSig" SG_ 2566878282 Install "Mch.TGU.SAT.Install";
BA_ "VssSig" SG_ 2566878282 Imei "Mch.TGU.SAT.Imei";
BA_ "VssSig" SG_ 2566878282 Rssi "Mch.TGU.SAT.Rssi";
BA_ "VssSig" SG_ 2566878282 Type "Mch.TGU.SAT.Type";
BA_ "VssSig" SG_ 2566878282 Enable "Mch.TGU.SAT.Enable";
BA_ "VssSig" SG_ 2566878794 ActnDrSec "Mch.TGU.TSEC.ActnDrSec";
BA_ "VssSig" SG_ 2566878794 WifiAntSt "Mch.TGU.TSEC.WifiAntSt";
BA_ "VssSig" SG_ 2566878794 CellAntSt "Mch.TGU.TSEC.CellAntSt";
BA_ "VssSig" SG_ 2566878794 GpsAntSt "Mch.TGU.TSEC.GpsAntSt";
BA_ "VssSig" SG_ 2566878794 SecCmd "Mch.TGU.TSEC.SecCmd";
BA_ "VssSig" SG_ 2583644746 UtcTm "Mch.TGU.TGUTM.UtcTm";
BA_ "VssSig" SG_ 2583644746 LocalTmOffset "Mch.TGU.TGUTM.LocalTmOffset";
BA_ "VssSig" SG_ 2566879818 Dkey "Mch.TGU.DKLI.Dkey";
BA_ "VssSig" SG_ 2566879818 KeyType "Mch.TGU.DKLI.KeyType";
BA_ "VssSig" SG_ 2566879818 LogIn "Mch.TGU.DKLI.LogIn";
BA_ "VssSig" SG_ 2566880074 DkeyList "Mch.TGU.DKLD.DkeyList";
BA_ "VssSig" SG_ 2566880074 Cnt "Mch.TGU.DKLD.Cnt";
BA_ "VssSig" SG_ 2566880296 DigitalKey "Mch.GP.DKSEL.DigitalKey";
BA_ "VssSig" SG_ 2566880296 SelType "Mch.GP.DKSEL.SelType";
BA_ "VssSig" SG_ 2566880586 Ack "Mch.TGU.TACK.Ack";
BA_ "VssSig" SG_ 2566880842 TmsPmntUnlockCd "Mch.TGU.TMSPUC.TmsPmntUnlockCd";
BA_ "VssSig" SG_ 2566883328 EmsObdIndFail "Mch.ECU.SCR2.EmsObdIndFail";
BA_ "VssSig" SG_ 2566883328 UreaLvAlm "Mch.ECU.SCR2.UreaLvAlm";
BA_ "VssSig" SG_ 2566883328 Scr2RegInfo "Mch.ECU.SCR2.Scr2RegInfo";
BA_ "VssSig" SG_ 2566883328 EmsObdIndSt "Mch.ECU.SCR2.EmsObdIndSt";
BA_ "VssSig" SG_ 2566883328 UreaLvBzSt "Mch.ECU.SCR2.UreaLvBzSt";
BA_ "VssSig" SG_ 2583625761 RrSspnLhSsPrs "Mch.MCU.AASI.RrSspnLhSsPrs";
BA_ "VssSig" SG_ 2583625761 RrSspnRhSsPrs "Mch.MCU.AASI.RrSspnRhSsPrs";
BA_ "VssSig" SG_ 2583625761 AcpSsPrs "Mch.MCU.AASI.AcpSsPrs";
BA_ "VssSig" SG_ 2583625761 BatVlt "Mch.MCU.AASI.BatVlt";
BA_ "VssSig" SG_ 2583625761 AltVlt "Mch.MCU.AASI.AltVlt";
BA_ "VssSig" SG_ 2583625761 Rr2BrkSsPrs "Mch.MCU.AASI.Rr2BrkSsPrs";
BA_ "VssSig" SG_ 2583625761 BoomCylRodSsPrs "Mch.MCU.AASI.BoomCylRodSsPrs";
BA_ "VssSig" SG_ 2583625761 BoomCylHeadSsPrs "Mch.MCU.AASI.BoomCylHeadSsPrs";
BA_ "VssSig" SG_ 2583625761 CtrPinAngSs1Vlt "Mch.MCU.AASI.CtrPinAngSs1Vlt";
BA_ "VssSig" SG_ 2583625761 AccPdlSs2Vlt "Mch.MCU.AASI.AccPdlSs2Vlt";
BA_ "VssSig" SG_ 2583625761 DumpBedAngSs2Vlt "Mch.MCU.AASI.DumpBedAngSs2Vlt";
BA_ "VssSig" SG_ 2583625761 DumpBedAngSs1Vlt "Mch.MCU.AASI.DumpBedAngSs1Vlt";
BA_ "VssSig" SG_ 2583625761 BrkInchPdlSs1Vlt "Mch.MCU.AASI.BrkInchPdlSs1Vlt";
BA_ "VssSig" SG_ 2583625761 TipJoySs1Vlt "Mch.MCU.AASI.TipJoySs1Vlt";
BA_ "VssSig" SG_ 2583625761 RhCylSsPrs "Mch.MCU.AASI.RhCylSsPrs";
BA_ "VssSig" SG_ 2583625761 EmgStrSsPrs "Mch.MCU.AASI.EmgStrSsPrs";
BA_ "VssSig" SG_ 2583625761 AxleOilSsTmp "Mch.MCU.AASI.AxleOilSsTmp";
BA_ "VssSig" SG_ 2583625761 FuelSsLv "Mch.MCU.AASI.FuelSsLv";
BA_ "VssSig" SG_ 2583625761 Rr1BrkSsPrs "Mch.MCU.AASI.Rr1BrkSsPrs";
BA_ "VssSig" SG_ 2583625761 FrBrkSsPrs "Mch.MCU.AASI.FrBrkSsPrs";
BA_ "VssSig" SG_ 2583625761 AccPdlSs1Vlt "Mch.MCU.AASI.AccPdlSs1Vlt";
BA_ "VssSig" SG_ 2583625761 CtrPinAngSs2Vlt "Mch.MCU.AASI.CtrPinAngSs2Vlt";
BA_ "VssSig" SG_ 2583625761 TmsSecVlt "Mch.MCU.AASI.TmsSecVlt";
BA_ "VssSig" SG_ 2583625761 LhCylSsPrs "Mch.MCU.AASI.LhCylSsPrs";
BA_ "VssSig" SG_ 2583625761 Acc3SsPrs "Mch.MCU.AASI.Acc3SsPrs";
BA_ "VssSig" SG_ 2583625761 BrkInchPdlSs2Vlt "Mch.MCU.AASI.BrkInchPdlSs2Vlt";
BA_ "VssSig" SG_ 2583625761 CacFanSsPrs "Mch.MCU.AASI.CacFanSsPrs";
BA_ "VssSig" SG_ 2583625761 Acc2SsPrs "Mch.MCU.AASI.Acc2SsPrs";
BA_ "VssSig" SG_ 2583625761 TipJoySs2Vlt "Mch.MCU.AASI.TipJoySs2Vlt";
BA_ "VssSig" SG_ 2583625761 TocFanSsPrs "Mch.MCU.AASI.TocFanSsPrs";
BA_ "VssSig" SG_ 2583625761 Acc1SsPrs "Mch.MCU.AASI.Acc1SsPrs";
BA_ "VssSig" SG_ 2583625761 PrkBrkSsPrs "Mch.MCU.AASI.PrkBrkSsPrs";
BA_ "VssSig" SG_ 2583625761 MainSsPrs "Mch.MCU.AASI.MainSsPrs";
BA_ "VssSig" SG_ 2583625761 WifSsVlt "Mch.MCU.AASI.WifSsVlt";
BA_ "VssSig" SG_ 2583625761 HydOilSsTmp "Mch.MCU.AASI.HydOilSsTmp";
BA_ "VssSig" SG_ 2583626017 FanDrvTocEvc "Mch.MCU.AAAI.FanDrvTocEvc";
BA_ "VssSig" SG_ 2583626017 eFan2DutyRatio "Mch.MCU.AAAI.eFan2DutyRatio";
BA_ "VssSig" SG_ 2583626017 eFan3DutyRatio "Mch.MCU.AAAI.eFan3DutyRatio";
BA_ "VssSig" SG_ 2583626017 eBrkEvc "Mch.MCU.AAAI.eBrkEvc";
BA_ "VssSig" SG_ 2583626017 eFan1DutyRatio "Mch.MCU.AAAI.eFan1DutyRatio";
BA_ "VssSig" SG_ 2583626017 FanDrvRadCacEvc "Mch.MCU.AAAI.FanDrvRadCacEvc";
BA_ "VssSig" SG_ 2583626017 BodyDnEvc "Mch.MCU.AAAI.BodyDnEvc";
BA_ "VssSig" SG_ 2583626017 BodyUpEvc "Mch.MCU.AAAI.BodyUpEvc";
BA_ "VssSig" SG_ 2583626273 BrkholdSw "Mch.MCU.ADSI.BrkholdSw";
BA_ "VssSig" SG_ 2583626273 DhlMnSw "Mch.MCU.ADSI.DhlMnSw";
BA_ "VssSig" SG_ 2583626273 CoolTankLvSw "Mch.MCU.ADSI.CoolTankLvSw";
BA_ "VssSig" SG_ 2583626273 StartCrkSw "Mch.MCU.ADSI.StartCrkSw";
BA_ "VssSig" SG_ 2583626273 GrSelSw "Mch.MCU.ADSI.GrSelSw";
BA_ "VssSig" SG_ 2583626273 GrSelNtrlSw "Mch.MCU.ADSI.GrSelNtrlSw";
BA_ "VssSig" SG_ 2583626273 PrkSw "Mch.MCU.ADSI.PrkSw";
BA_ "VssSig" SG_ 2583626273 GrSelRvsSw "Mch.MCU.ADSI.GrSelRvsSw";
BA_ "VssSig" SG_ 2583626273 GrSelShftDnSw "Mch.MCU.ADSI.GrSelShftDnSw";
BA_ "VssSig" SG_ 2583626273 GrSelShftUpSw "Mch.MCU.ADSI.GrSelShftUpSw";
BA_ "VssSig" SG_ 2583626273 GrSelFwdSw "Mch.MCU.ADSI.GrSelFwdSw";
BA_ "VssSig" SG_ 2583626273 DustIndSw "Mch.MCU.ADSI.DustIndSw";
BA_ "VssSig" SG_ 2583626273 StartAccSw "Mch.MCU.ADSI.StartAccSw";
BA_ "VssSig" SG_ 2583626273 AtsForceRgnSw "Mch.MCU.ADSI.AtsForceRgnSw";
BA_ "VssSig" SG_ 2583626273 AtsRgnIhbsw "Mch.MCU.ADSI.AtsRgnIhbsw";
BA_ "VssSig" SG_ 2583626273 eFan3ErrSt "Mch.MCU.ADSI.eFan3ErrSt";
BA_ "VssSig" SG_ 2583626273 KeyBrSw "Mch.MCU.ADSI.KeyBrSw";
BA_ "VssSig" SG_ 2583626273 TipJoySw "Mch.MCU.ADSI.TipJoySw";
BA_ "VssSig" SG_ 2583626273 AgsSw "Mch.MCU.ADSI.AgsSw";
BA_ "VssSig" SG_ 2583626273 eFan2ErrSt "Mch.MCU.ADSI.eFan2ErrSt";
BA_ "VssSig" SG_ 2583626273 eFan1ErrSt "Mch.MCU.ADSI.eFan1ErrSt";
BA_ "VssSig" SG_ 2583626273 SeatBeltSt "Mch.MCU.ADSI.SeatBeltSt";
BA_ "VssSig" SG_ 2583626273 FrWiperStpSw "Mch.MCU.ADSI.FrWiperStpSw";
BA_ "VssSig" SG_ 2583626529 RrSspnRhDn "Mch.MCU.ADAI.RrSspnRhDn";
BA_ "VssSig" SG_ 2583626529 RrSspnRhUp "Mch.MCU.ADAI.RrSspnRhUp";
BA_ "VssSig" SG_ 2583626529 RrSspnLhDn "Mch.MCU.ADAI.RrSspnLhDn";
BA_ "VssSig" SG_ 2583626529 RrSspnLhUp "Mch.MCU.ADAI.RrSspnLhUp";
BA_ "VssSig" SG_ 2583626529 SusRhDn "Mch.MCU.ADAI.SusRhDn";
BA_ "VssSig" SG_ 2583626529 TocRvs "Mch.MCU.ADAI.TocRvs";
BA_ "VssSig" SG_ 2583626529 TurnSigRhRly "Mch.MCU.ADAI.TurnSigRhRly";
BA_ "VssSig" SG_ 2583626529 TurnSigLhRly "Mch.MCU.ADAI.TurnSigLhRly";
BA_ "VssSig" SG_ 2583626529 SusRhUp "Mch.MCU.ADAI.SusRhUp";
BA_ "VssSig" SG_ 2583626529 EgRunOutSig "Mch.MCU.ADAI.EgRunOutSig";
BA_ "VssSig" SG_ 2583626529 SusLhDn "Mch.MCU.ADAI.SusLhDn";
BA_ "VssSig" SG_ 2583626529 UreaSuperChgWrnSig "Mch.MCU.ADAI.UreaSuperChgWrnSig";
BA_ "VssSig" SG_ 2583626529 FanStpSv "Mch.MCU.ADAI.FanStpSv";
BA_ "VssSig" SG_ 2583626529 SusLhUp "Mch.MCU.ADAI.SusLhUp";
BA_ "VssSig" SG_ 2583626529 PrkBrkRlsSv "Mch.MCU.ADAI.PrkBrkRlsSv";
BA_ "VssSig" SG_ 2583626529 AxleOilCoolSv "Mch.MCU.ADAI.AxleOilCoolSv";
BA_ "VssSig" SG_ 2583626529 TocUnloading "Mch.MCU.ADAI.TocUnloading";
BA_ "VssSig" SG_ 2583626529 AccRly "Mch.MCU.ADAI.AccRly";
BA_ "VssSig" SG_ 2583626529 LiftArmFlt "Mch.MCU.ADAI.LiftArmFlt";
BA_ "VssSig" SG_ 2583626529 AutoShutOffRly "Mch.MCU.ADAI.AutoShutOffRly";
BA_ "VssSig" SG_ 2583626529 BrkChgSv "Mch.MCU.ADAI.BrkChgSv";
BA_ "VssSig" SG_ 2566884897 RrRhTirePrs "Mch.MCU.TIG1.RrRhTirePrs";
BA_ "VssSig" SG_ 2566884897 RrLhTirePrs "Mch.MCU.TIG1.RrLhTirePrs";
BA_ "VssSig" SG_ 2566884897 CtrRhTirePrs "Mch.MCU.TIG1.CtrRhTirePrs";
BA_ "VssSig" SG_ 2566884897 CtrLhTirePrs "Mch.MCU.TIG1.CtrLhTirePrs";
BA_ "VssSig" SG_ 2566884897 FronRhTirePrs "Mch.MCU.TIG1.FronRhTirePrs";
BA_ "VssSig" SG_ 2566884897 FrLhTirePrs "Mch.MCU.TIG1.FrLhTirePrs";
BA_ "VssSig" SG_ 2566885153 RrRhTireTmp "Mch.MCU.TIG2.RrRhTireTmp";
BA_ "VssSig" SG_ 2566885153 RrLhTireTmp "Mch.MCU.TIG2.RrLhTireTmp";
BA_ "VssSig" SG_ 2566885153 CtrRhTireTmp "Mch.MCU.TIG2.CtrRhTireTmp";
BA_ "VssSig" SG_ 2566885153 CtrLhTireTmp "Mch.MCU.TIG2.CtrLhTireTmp";
BA_ "VssSig" SG_ 2566885153 FronRhTireTmp "Mch.MCU.TIG2.FronRhTireTmp";
BA_ "VssSig" SG_ 2566885153 FrLhTireTmp "Mch.MCU.TIG2.FrLhTireTmp";
BA_ "VssSig" SG_ 2566885409 PartNo "Mch.MCU.QRCI.PartNo";
BA_ "VssSig" SG_ 2566885409 SerialNo "Mch.MCU.QRCI.SerialNo";
BA_ "VssSig" SG_ 2566885409 MnftCode "Mch.MCU.QRCI.MnftCode";
BA_ "VssSig" SG_ 2566885409 ComCode "Mch.MCU.QRCI.ComCode";
BA_ "VssSig" SG_ 2566885409 Year "Mch.MCU.QRCI.Year";
BA_ "VssSig" SG_ 2566885409 Day "Mch.MCU.QRCI.Day";
BA_ "VssSig" SG_ 2566885409 Month "Mch.MCU.QRCI.Month";
BA_ "VssSig" SG_ 2566885409 SwVer "Mch.MCU.QRCI.SwVer";
BA_ "VssSig" SG_ 2566885665 TotAvgReliefOprPct "Mch.MCU.ECORI.TotAvgReliefOprPct";
BA_ "VssSig" SG_ 2566885665 TotAvgLwIdleOprPct "Mch.MCU.ECORI.TotAvgLwIdleOprPct";
BA_ "VssSig" SG_ 2566885665 TotAvgHhIdleOprPct "Mch.MCU.ECORI.TotAvgHhIdleOprPct";
BA_ "VssSig" SG_ 2566885665 Day7ReliefOprPct "Mch.MCU.ECORI.Day7ReliefOprPct";
BA_ "VssSig" SG_ 2566885665 Day7LwIdleOprPct "Mch.MCU.ECORI.Day7LwIdleOprPct";
BA_ "VssSig" SG_ 2566885665 Day7HhIdleOprPct "Mch.MCU.ECORI.Day7HhIdleOprPct";
BA_ "VssSig" SG_ 2566885665 Day6ReliefOprPct "Mch.MCU.ECORI.Day6ReliefOprPct";
BA_ "VssSig" SG_ 2566885665 Day6LwIdleOprPct "Mch.MCU.ECORI.Day6LwIdleOprPct";
BA_ "VssSig" SG_ 2566885665 Day6HhIdleOprPct "Mch.MCU.ECORI.Day6HhIdleOprPct";
BA_ "VssSig" SG_ 2566885665 Day5ReliefOprPct "Mch.MCU.ECORI.Day5ReliefOprPct";
BA_ "VssSig" SG_ 2566885665 Day5LwIdleOprPct "Mch.MCU.ECORI.Day5LwIdleOprPct";
BA_ "VssSig" SG_ 2566885665 Day5HhIdleOprPct "Mch.MCU.ECORI.Day5HhIdleOprPct";
BA_ "VssSig" SG_ 2566885665 Day4ReliefOprPct "Mch.MCU.ECORI.Day4ReliefOprPct";
BA_ "VssSig" SG_ 2566885665 Day4LwIdleOprPct "Mch.MCU.ECORI.Day4LwIdleOprPct";
BA_ "VssSig" SG_ 2566885665 Day4HhIdleOprPct "Mch.MCU.ECORI.Day4HhIdleOprPct";
BA_ "VssSig" SG_ 2566885665 Day3ReliefOprPct "Mch.MCU.ECORI.Day3ReliefOprPct";
BA_ "VssSig" SG_ 2566885665 Day3LwIdleOprPct "Mch.MCU.ECORI.Day3LwIdleOprPct";
BA_ "VssSig" SG_ 2566885665 Day3HhIdleOprPct "Mch.MCU.ECORI.Day3HhIdleOprPct";
BA_ "VssSig" SG_ 2566885665 Day2ReliefOprPct "Mch.MCU.ECORI.Day2ReliefOprPct";
BA_ "VssSig" SG_ 2566885665 Day2LwIdleOprPct "Mch.MCU.ECORI.Day2LwIdleOprPct";
BA_ "VssSig" SG_ 2566885665 Day2HhIdleOprPct "Mch.MCU.ECORI.Day2HhIdleOprPct";
BA_ "VssSig" SG_ 2566885665 Day1ReliefOprPct "Mch.MCU.ECORI.Day1ReliefOprPct";
BA_ "VssSig" SG_ 2566885665 Day1LwIdleOprPct "Mch.MCU.ECORI.Day1LwIdleOprPct";
BA_ "VssSig" SG_ 2566885665 Day1HhIdleOprPct "Mch.MCU.ECORI.Day1HhIdleOprPct";
BA_ "VssSig" SG_ 2566885665 NowReliefOprLv "Mch.MCU.ECORI.NowReliefOprLv";
BA_ "VssSig" SG_ 2566885665 NowLwIdleOprLv "Mch.MCU.ECORI.NowLwIdleOprLv";
BA_ "VssSig" SG_ 2566885665 NowHhIdleOprLv "Mch.MCU.ECORI.NowHhIdleOprLv";
BA_ "VssSig" SG_ 2566885665 NowReliefOprPct "Mch.MCU.ECORI.NowReliefOprPct";
BA_ "VssSig" SG_ 2566885665 NowLwIdleOprPct "Mch.MCU.ECORI.NowLwIdleOprPct";
BA_ "VssSig" SG_ 2566885665 NowHhIdleOprPct "Mch.MCU.ECORI.NowHhIdleOprPct";
BA_ "VssSig" SG_ 2566886586 Objinzone6 "Mch.RDRR.ROZI.Objinzone6";
BA_ "VssSig" SG_ 2566886586 Objinzone5 "Mch.RDRR.ROZI.Objinzone5";
BA_ "VssSig" SG_ 2566886586 Objinzone4 "Mch.RDRR.ROZI.Objinzone4";
BA_ "VssSig" SG_ 2566886586 Objinzone3 "Mch.RDRR.ROZI.Objinzone3";
BA_ "VssSig" SG_ 2566886586 Objinzone2 "Mch.RDRR.ROZI.Objinzone2";
BA_ "VssSig" SG_ 2566886586 Objinzone1 "Mch.RDRR.ROZI.Objinzone1";
BA_ "VssSig" SG_ 2566886587 Objinzone6 "Mch.RDLH.ROZI.Objinzone6";
BA_ "VssSig" SG_ 2566886587 Objinzone5 "Mch.RDLH.ROZI.Objinzone5";
BA_ "VssSig" SG_ 2566886587 Objinzone4 "Mch.RDLH.ROZI.Objinzone4";
BA_ "VssSig" SG_ 2566886587 Objinzone3 "Mch.RDLH.ROZI.Objinzone3";
BA_ "VssSig" SG_ 2566886587 Objinzone2 "Mch.RDLH.ROZI.Objinzone2";
BA_ "VssSig" SG_ 2566886587 Objinzone1 "Mch.RDLH.ROZI.Objinzone1";
BA_ "VssSig" SG_ 2566886588 Objinzone6 "Mch.RDRH.ROZI.Objinzone6";
BA_ "VssSig" SG_ 2566886588 Objinzone5 "Mch.RDRH.ROZI.Objinzone5";
BA_ "VssSig" SG_ 2566886588 Objinzone4 "Mch.RDRH.ROZI.Objinzone4";
BA_ "VssSig" SG_ 2566886588 Objinzone3 "Mch.RDRH.ROZI.Objinzone3";
BA_ "VssSig" SG_ 2566886588 Objinzone2 "Mch.RDRH.ROZI.Objinzone2";
BA_ "VssSig" SG_ 2566886588 Objinzone1 "Mch.RDRH.ROZI.Objinzone1";
BA_ "VssSig" SG_ 2566886842 ObjSeq "Mch.RDRR.ROI.ObjSeq";
BA_ "VssSig" SG_ 2566886842 PwrOfObj "Mch.RDRR.ROI.PwrOfObj";
BA_ "VssSig" SG_ 2566886842 YDirVelocity "Mch.RDRR.ROI.YDirVelocity";
BA_ "VssSig" SG_ 2566886842 XDirVelocity "Mch.RDRR.ROI.XDirVelocity";
BA_ "VssSig" SG_ 2566886842 ZDirPos "Mch.RDRR.ROI.ZDirPos";
BA_ "VssSig" SG_ 2566886842 YDirPos "Mch.RDRR.ROI.YDirPos";
BA_ "VssSig" SG_ 2566886842 XDirPos "Mch.RDRR.ROI.XDirPos";
BA_ "VssSig" SG_ 2566886843 ObjSeq "Mch.RDLH.ROI.ObjSeq";
BA_ "VssSig" SG_ 2566886843 PwrOfObj "Mch.RDLH.ROI.PwrOfObj";
BA_ "VssSig" SG_ 2566886843 YDirVelocity "Mch.RDLH.ROI.YDirVelocity";
BA_ "VssSig" SG_ 2566886843 XDirVelocity "Mch.RDLH.ROI.XDirVelocity";
BA_ "VssSig" SG_ 2566886843 ZDirPos "Mch.RDLH.ROI.ZDirPos";
BA_ "VssSig" SG_ 2566886843 YDirPos "Mch.RDLH.ROI.YDirPos";
BA_ "VssSig" SG_ 2566886843 XDirPos "Mch.RDLH.ROI.XDirPos";
BA_ "VssSig" SG_ 2566886844 ObjSeq "Mch.RDRH.ROI.ObjSeq";
BA_ "VssSig" SG_ 2566886844 PwrOfObj "Mch.RDRH.ROI.PwrOfObj";
BA_ "VssSig" SG_ 2566886844 YDirVelocity "Mch.RDRH.ROI.YDirVelocity";
BA_ "VssSig" SG_ 2566886844 XDirVelocity "Mch.RDRH.ROI.XDirVelocity";
BA_ "VssSig" SG_ 2566886844 ZDirPos "Mch.RDRH.ROI.ZDirPos";
BA_ "VssSig" SG_ 2566886844 YDirPos "Mch.RDRH.ROI.YDirPos";
BA_ "VssSig" SG_ 2566886844 XDirPos "Mch.RDRH.ROI.XDirPos";
BA_ "VssSig" SG_ 2566886952 RrVwPriMd "Mch.GP.AVMVM.RrVwPriMd";
BA_ "VssSig" SG_ 2566886952 VwMd "Mch.GP.AVMVM.VwMd";
BA_ "VssSig" SG_ 2566887223 Tb2ToleranceCompSt "Mch.AVM.AVMSI.Tb2ToleranceCompSt";
BA_ "VssSig" SG_ 2566887223 Tb2ToleranceCompSetApp "Mch.AVM.AVMSI.Tb2ToleranceCompSetApp";
BA_ "VssSig" SG_ 2566887223 RrVwPriMd "Mch.AVM.AVMSI.RrVwPriMd";
BA_ "VssSig" SG_ 2566887223 AvmWrnGud "Mch.AVM.AVMSI.AvmWrnGud";
BA_ "VssSig" SG_ 2566887223 AvmSt "Mch.AVM.AVMSI.AvmSt";
BA_ "VssSig" SG_ 2566887223 AvmUltraBz "Mch.AVM.AVMSI.AvmUltraBz";
BA_ "VssSig" SG_ 2566887223 AvmTonSize "Mch.AVM.AVMSI.AvmTonSize";
BA_ "VssSig" SG_ 2566887223 AvmDisplayMsg "Mch.AVM.AVMSI.AvmDisplayMsg";
BA_ "VssSig" SG_ 2566887223 AvmOutType "Mch.AVM.AVMSI.AvmOutType";
BA_ "VssSig" SG_ 2566887223 AvmVw "Mch.AVM.AVMSI.AvmVw";
BA_ "VssSig" SG_ 2566887223 AvmLanguagePack "Mch.AVM.AVMSI.AvmLanguagePack";
BA_ "VssSig" SG_ 2566887479 UltsSigL6 "Mch.AVM.AVMUS.UltsSigL6";
BA_ "VssSig" SG_ 2566887479 UltsSigR6 "Mch.AVM.AVMUS.UltsSigR6";
BA_ "VssSig" SG_ 2566887479 UltsSigL5 "Mch.AVM.AVMUS.UltsSigL5";
BA_ "VssSig" SG_ 2566887479 UltsSigR5 "Mch.AVM.AVMUS.UltsSigR5";
BA_ "VssSig" SG_ 2566887479 UltsSigL4 "Mch.AVM.AVMUS.UltsSigL4";
BA_ "VssSig" SG_ 2566887479 UltsSigR4 "Mch.AVM.AVMUS.UltsSigR4";
BA_ "VssSig" SG_ 2566887479 UltsSigL3 "Mch.AVM.AVMUS.UltsSigL3";
BA_ "VssSig" SG_ 2566887479 UltsSigR3 "Mch.AVM.AVMUS.UltsSigR3";
BA_ "VssSig" SG_ 2566887479 UltsSigL2 "Mch.AVM.AVMUS.UltsSigL2";
BA_ "VssSig" SG_ 2566887479 UltsSigR2 "Mch.AVM.AVMUS.UltsSigR2";
BA_ "VssSig" SG_ 2566887479 UltsSigL1 "Mch.AVM.AVMUS.UltsSigL1";
BA_ "VssSig" SG_ 2566887479 UltsSigR1 "Mch.AVM.AVMUS.UltsSigR1";
BA_ "VssSig" SG_ 2566887720 CamPrmtCorCompleteSt "Mch.GP.AVMRM.CamPrmtCorCompleteSt";
BA_ "VssSig" SG_ 2566887720 CamPrmtVerMsb "Mch.GP.AVMRM.CamPrmtVerMsb";
BA_ "VssSig" SG_ 2566887720 CamPrmtVerLsb "Mch.GP.AVMRM.CamPrmtVerLsb";
BA_ "VssSig" SG_ 2566887720 Language "Mch.GP.AVMRM.Language";
BA_ "VssSig" SG_ 2566887720 ToleranceCorMenuentryCmd "Mch.GP.AVMRM.ToleranceCorMenuentryCmd";
BA_ "VssSig" SG_ 2566887720 WrnGudSetCmd "Mch.GP.AVMRM.WrnGudSetCmd";
BA_ "VssSig" SG_ 2566887720 UltsSs08Cmd "Mch.GP.AVMRM.UltsSs08Cmd";
BA_ "VssSig" SG_ 2566887720 UltsSs07Cmd "Mch.GP.AVMRM.UltsSs07Cmd";
BA_ "VssSig" SG_ 2566887720 UltsSs06Cmd "Mch.GP.AVMRM.UltsSs06Cmd";
BA_ "VssSig" SG_ 2566887720 UltsSs05Cmd "Mch.GP.AVMRM.UltsSs05Cmd";
BA_ "VssSig" SG_ 2566887720 UltsSs04Cmd "Mch.GP.AVMRM.UltsSs04Cmd";
BA_ "VssSig" SG_ 2566887720 UltsSs03Cmd "Mch.GP.AVMRM.UltsSs03Cmd";
BA_ "VssSig" SG_ 2566887720 UltsSs02Cmd "Mch.GP.AVMRM.UltsSs02Cmd";
BA_ "VssSig" SG_ 2566887720 UltsSs01Cmd "Mch.GP.AVMRM.UltsSs01Cmd";
BA_ "VssSig" SG_ 2566887720 UltsSs12Cmd "Mch.GP.AVMRM.UltsSs12Cmd";
BA_ "VssSig" SG_ 2566887720 UltsSs11Cmd "Mch.GP.AVMRM.UltsSs11Cmd";
BA_ "VssSig" SG_ 2566887720 UltsSs10Cmd "Mch.GP.AVMRM.UltsSs10Cmd";
BA_ "VssSig" SG_ 2566887720 UltsSs09Cmd "Mch.GP.AVMRM.UltsSs09Cmd";
BA_ "VssSig" SG_ 2566887720 SetApplicationCmd "Mch.GP.AVMRM.SetApplicationCmd";
BA_ "VssSig" SG_ 2566887720 ToleranceCorCmd "Mch.GP.AVMRM.ToleranceCorCmd";
BA_ "VssSig" SG_ 2566887720 FactoryReCmd "Mch.GP.AVMRM.FactoryReCmd";
BA_ "VssSig" SG_ 2566887720 UltsSsOpt "Mch.GP.AVMRM.UltsSsOpt";
BA_ "VssSig" SG_ 2566887720 UltsBuzzerStopSig "Mch.GP.AVMRM.UltsBuzzerStopSig";
BA_ "VssSig" SG_ 2566887720 BoomCamOpt "Mch.GP.AVMRM.BoomCamOpt";
BA_ "VssSig" SG_ 2566887720 UltsBzOffSig "Mch.GP.AVMRM.UltsBzOffSig";
BA_ "VssSig" SG_ 2566887720 UltsRecognitionDistanceSet "Mch.GP.AVMRM.UltsRecognitionDistanceSet";
BA_ "VssSig" SG_ 2566887720 VhcType2 "Mch.GP.AVMRM.VhcType2";
BA_ "VssSig" SG_ 2566887720 VhcType1 "Mch.GP.AVMRM.VhcType1";
BA_ "VssSig" SG_ 2566887720 TonsOftheTensDigit "Mch.GP.AVMRM.TonsOftheTensDigit";
BA_ "VssSig" SG_ 2566887720 TonsOftheUnitsDigit "Mch.GP.AVMRM.TonsOftheUnitsDigit";
BA_ "VssSig" SG_ 2566887720 FactoryType "Mch.GP.AVMRM.FactoryType";
BA_ "VssSig" SG_ 2566887720 VwMd "Mch.GP.AVMRM.VwMd";
BA_ "VssSig" SG_ 2566887991 CamPrmtCorCompleteSt "Mch.AVM.AVMSM.CamPrmtCorCompleteSt";
BA_ "VssSig" SG_ 2566887991 CamPrmtVerMsb "Mch.AVM.AVMSM.CamPrmtVerMsb";
BA_ "VssSig" SG_ 2566887991 CamPrmtVerLsb "Mch.AVM.AVMSM.CamPrmtVerLsb";
BA_ "VssSig" SG_ 2566887991 Language "Mch.AVM.AVMSM.Language";
BA_ "VssSig" SG_ 2566887991 ToleranceCorMenuentryCmd "Mch.AVM.AVMSM.ToleranceCorMenuentryCmd";
BA_ "VssSig" SG_ 2566887991 WrnGudSetCmd "Mch.AVM.AVMSM.WrnGudSetCmd";
BA_ "VssSig" SG_ 2566887991 UltsSs08Cmd "Mch.AVM.AVMSM.UltsSs08Cmd";
BA_ "VssSig" SG_ 2566887991 UltsSs07Cmd "Mch.AVM.AVMSM.UltsSs07Cmd";
BA_ "VssSig" SG_ 2566887991 UltsSs06Cmd "Mch.AVM.AVMSM.UltsSs06Cmd";
BA_ "VssSig" SG_ 2566887991 UltsSs05Cmd "Mch.AVM.AVMSM.UltsSs05Cmd";
BA_ "VssSig" SG_ 2566887991 UltsSs04Cmd "Mch.AVM.AVMSM.UltsSs04Cmd";
BA_ "VssSig" SG_ 2566887991 UltsSs03Cmd "Mch.AVM.AVMSM.UltsSs03Cmd";
BA_ "VssSig" SG_ 2566887991 UltsSs02Cmd "Mch.AVM.AVMSM.UltsSs02Cmd";
BA_ "VssSig" SG_ 2566887991 UltsSs01Cmd "Mch.AVM.AVMSM.UltsSs01Cmd";
BA_ "VssSig" SG_ 2566887991 UltsSs12Cmd "Mch.AVM.AVMSM.UltsSs12Cmd";
BA_ "VssSig" SG_ 2566887991 UltsSs11Cmd "Mch.AVM.AVMSM.UltsSs11Cmd";
BA_ "VssSig" SG_ 2566887991 UltsSs10Cmd "Mch.AVM.AVMSM.UltsSs10Cmd";
BA_ "VssSig" SG_ 2566887991 UltsSs09Cmd "Mch.AVM.AVMSM.UltsSs09Cmd";
BA_ "VssSig" SG_ 2566887991 SetAppCmd "Mch.AVM.AVMSM.SetAppCmd";
BA_ "VssSig" SG_ 2566887991 ToleranceCorCmd "Mch.AVM.AVMSM.ToleranceCorCmd";
BA_ "VssSig" SG_ 2566887991 FactoryResetCmd "Mch.AVM.AVMSM.FactoryResetCmd";
BA_ "VssSig" SG_ 2566887991 UltsSsOpt "Mch.AVM.AVMSM.UltsSsOpt";
BA_ "VssSig" SG_ 2566887991 UltsBzStopSig "Mch.AVM.AVMSM.UltsBzStopSig";
BA_ "VssSig" SG_ 2566887991 BoomCamOpt "Mch.AVM.AVMSM.BoomCamOpt";
BA_ "VssSig" SG_ 2566887991 UltsBzOffSig "Mch.AVM.AVMSM.UltsBzOffSig";
BA_ "VssSig" SG_ 2566887991 UltsRecognitionDistanceSet "Mch.AVM.AVMSM.UltsRecognitionDistanceSet";
BA_ "VssSig" SG_ 2566887991 VhcType2 "Mch.AVM.AVMSM.VhcType2";
BA_ "VssSig" SG_ 2566887991 VhcType1 "Mch.AVM.AVMSM.VhcType1";
BA_ "VssSig" SG_ 2566887991 TonsOftheTensDigit "Mch.AVM.AVMSM.TonsOftheTensDigit";
BA_ "VssSig" SG_ 2566887991 TonsOftheUnitsDigit "Mch.AVM.AVMSM.TonsOftheUnitsDigit";
BA_ "VssSig" SG_ 2566887991 FactoryType "Mch.AVM.AVMSM.FactoryType";
BA_ "VssSig" SG_ 2566887991 VwMd "Mch.AVM.AVMSM.VwMd";
BA_ "VssSig" SG_ 2566888759 AvmVerYear "Mch.AVM.AVMVER.AvmVerYear";
BA_ "VssSig" SG_ 2566888759 AvmVerMonth "Mch.AVM.AVMVER.AvmVerMonth";
BA_ "VssSig" SG_ 2566888759 AvmVerDate "Mch.AVM.AVMVER.AvmVerDate";
BA_ "VssSig" SG_ 2566888759 AvmVer "Mch.AVM.AVMVER.AvmVer";
BA_ "VssSig" SG_ 2566889512 RvsWarnSt "Mch.GP.GPCMD.RvsWarnSt";
BA_ "VssSig" SG_ 2566889512 MirrorHtOprtgSig "Mch.GP.GPCMD.MirrorHtOprtgSig";
BA_ "VssSig" SG_ 2566889512 EvMdCmd "Mch.GP.GPCMD.EvMdCmd";
BA_ "VssSig" SG_ 2566889512 ObjectSsChmsl "Mch.GP.GPCMD.ObjectSsChmsl";
BA_ "VssSig" SG_ 2566889512 KeylessCrankEnbSt "Mch.GP.GPCMD.KeylessCrankEnbSt";
BA_ "VssSig" SG_ 2566889512 DaacmdSt "Mch.GP.GPCMD.DaacmdSt";
BA_ "VssSig" SG_ 2566889512 QuickCoolMdSt "Mch.GP.GPCMD.QuickCoolMdSt";
BA_ "VssSig" SG_ 2566889512 DzAstMdSt "Mch.GP.GPCMD.DzAstMdSt";
BA_ "VssSig" SG_ 2566889512 KeyPadPri "Mch.GP.GPCMD.KeyPadPri";
BA_ "VssSig" SG_ 2566889512 RpmCmdbyJD "Mch.GP.GPCMD.RpmCmdbyJD";
BA_ "VssSig" SG_ 2566889512 TractionMdSt "Mch.GP.GPCMD.TractionMdSt";
BA_ "VssSig" SG_ 2566889512 ExternalSoundCmd "Mch.GP.GPCMD.ExternalSoundCmd";
BA_ "VssSig" SG_ 2566889512 EgLckSt "Mch.GP.GPCMD.EgLckSt";
BA_ "VssSig" SG_ 2566889512 JduseStforRpm "Mch.GP.GPCMD.JduseStforRpm";
BA_ "VssSig" SG_ 2566889512 AutoIdleMdSt "Mch.GP.GPCMD.AutoIdleMdSt";
BA_ "VssSig" SG_ 2566889512 WrkMdSt "Mch.GP.GPCMD.WrkMdSt";
BA_ "VssSig" SG_ 2566889512 PwrMdSt "Mch.GP.GPCMD.PwrMdSt";
BA_ "VssSig" SG_ 2566889768 LocalHrOfs "Mch.GP.GPTD.LocalHrOfs";
BA_ "VssSig" SG_ 2566889768 LocalMinOfs "Mch.GP.GPTD.LocalMinOfs";
BA_ "VssSig" SG_ 2566889768 Year "Mch.GP.GPTD.Year";
BA_ "VssSig" SG_ 2566889768 Day "Mch.GP.GPTD.Day";
BA_ "VssSig" SG_ 2566889768 Mon "Mch.GP.GPTD.Mon";
BA_ "VssSig" SG_ 2566889768 Hrs "Mch.GP.GPTD.Hrs";
BA_ "VssSig" SG_ 2566889768 Mins "Mch.GP.GPTD.Mins";
BA_ "VssSig" SG_ 2566889768 Secs "Mch.GP.GPTD.Secs";
BA_ "VssSig" SG_ 2566890024 AvmSwVer "Mch.GP.SVGP.AvmSwVer";
BA_ "VssSig" SG_ 2566890024 AvmSwVerYear "Mch.GP.SVGP.AvmSwVerYear";
BA_ "VssSig" SG_ 2566890024 AvmSwVerDay "Mch.GP.SVGP.AvmSwVerDay";
BA_ "VssSig" SG_ 2566890024 AvmSwVerMon "Mch.GP.SVGP.AvmSwVerMon";
BA_ "VssSig" SG_ 2566890024 GpOsSwVer "Mch.GP.SVGP.GpOsSwVer";
BA_ "VssSig" SG_ 2566890024 GpOsSwVerYear "Mch.GP.SVGP.GpOsSwVerYear";
BA_ "VssSig" SG_ 2566890024 GpOsSwVerDay "Mch.GP.SVGP.GpOsSwVerDay";
BA_ "VssSig" SG_ 2566890024 GpOsSwVerMon "Mch.GP.SVGP.GpOsSwVerMon";
BA_ "VssSig" SG_ 2566890024 GpAppSwVer "Mch.GP.SVGP.GpAppSwVer";
BA_ "VssSig" SG_ 2566890024 GpAppSwVerYear "Mch.GP.SVGP.GpAppSwVerYear";
BA_ "VssSig" SG_ 2566890024 GpAppSwVerDay "Mch.GP.SVGP.GpAppSwVerDay";
BA_ "VssSig" SG_ 2566890024 GpAppSwVerMon "Mch.GP.SVGP.GpAppSwVerMon";
BA_ "VssSig" SG_ 2566890280 AttSetFlowVal "Mch.GP.ATTFC.AttSetFlowVal";
BA_ "VssSig" SG_ 2566890280 AttSetSaveFlag "Mch.GP.ATTFC.AttSetSaveFlag";
BA_ "VssSig" SG_ 2566890280 AttNo "Mch.GP.ATTFC.AttNo";
BA_ "VssSig" SG_ 2566890280 AttType "Mch.GP.ATTFC.AttType";
BA_ "VssSig" SG_ 2566890536 MgSoundGudStep "Mch.GP.MG2DBC.MgSoundGudStep";
BA_ "VssSig" SG_ 2566890536 AlmSt "Mch.GP.MG2DBC.AlmSt";
BA_ "VssSig" SG_ 2566890561 MgSoundGudStep "Mch.GW.MG2DBC.MgSoundGudStep";
BA_ "VssSig" SG_ 2566890561 AlmSt "Mch.GW.MG2DBC.AlmSt";
BA_ "VssSig" SG_ 2566890792 MsgChecksum "Mch.GP.GPCCS.MsgChecksum";
BA_ "VssSig" SG_ 2566890792 MsgCounter "Mch.GP.GPCCS.MsgCounter";
BA_ "VssSig" SG_ 2566890792 OptSetJoyPatternChange "Mch.GP.GPCCS.OptSetJoyPatternChange";
BA_ "VssSig" SG_ 2566892072 ReqCallIndex "Mch.GP.DCAP.ReqCallIndex";
BA_ "VssSig" SG_ 2566892072 PairingReq "Mch.GP.DCAP.PairingReq";
BA_ "VssSig" SG_ 2566892072 HangUpBtn "Mch.GP.DCAP.HangUpBtn";
BA_ "VssSig" SG_ 2566892072 DabSel "Mch.GP.DCAP.DabSel";
BA_ "VssSig" SG_ 2566892072 MdSel "Mch.GP.DCAP.MdSel";
BA_ "VssSig" SG_ 2566892072 AdoVolDownSel "Mch.GP.DCAP.AdoVolDownSel";
BA_ "VssSig" SG_ 2566892072 AdoVolUpSel "Mch.GP.DCAP.AdoVolUpSel";
BA_ "VssSig" SG_ 2566892072 BandSel "Mch.GP.DCAP.BandSel";
BA_ "VssSig" SG_ 2566892072 TalkBtn "Mch.GP.DCAP.TalkBtn";
BA_ "VssSig" SG_ 2566892072 AdoTuneDownSel "Mch.GP.DCAP.AdoTuneDownSel";
BA_ "VssSig" SG_ 2566892072 AdoCallListPopupSt "Mch.GP.DCAP.AdoCallListPopupSt";
BA_ "VssSig" SG_ 2566892072 AdoMenuSel "Mch.GP.DCAP.AdoMenuSel";
BA_ "VssSig" SG_ 2566892072 AdoPowerSel "Mch.GP.DCAP.AdoPowerSel";
BA_ "VssSig" SG_ 2566892072 AdoP5Sel "Mch.GP.DCAP.AdoP5Sel";
BA_ "VssSig" SG_ 2566892072 AdoP6Sel "Mch.GP.DCAP.AdoP6Sel";
BA_ "VssSig" SG_ 2566892072 AdoTuneSel "Mch.GP.DCAP.AdoTuneSel";
BA_ "VssSig" SG_ 2566892072 AdoTuneUpSel "Mch.GP.DCAP.AdoTuneUpSel";
BA_ "VssSig" SG_ 2566892072 AdoP1Sel "Mch.GP.DCAP.AdoP1Sel";
BA_ "VssSig" SG_ 2566892072 AdoP2Sel "Mch.GP.DCAP.AdoP2Sel";
BA_ "VssSig" SG_ 2566892072 AdoP3Sel "Mch.GP.DCAP.AdoP3Sel";
BA_ "VssSig" SG_ 2566892072 AdoP4Sel "Mch.GP.DCAP.AdoP4Sel";
BA_ "VssSig" SG_ 2566892072 AdoAmSel "Mch.GP.DCAP.AdoAmSel";
BA_ "VssSig" SG_ 2566892072 AdoFmSel "Mch.GP.DCAP.AdoFmSel";
BA_ "VssSig" SG_ 2566892072 AdoUsbSel "Mch.GP.DCAP.AdoUsbSel";
BA_ "VssSig" SG_ 2566892072 AdoAuxSel "Mch.GP.DCAP.AdoAuxSel";
BA_ "VssSig" SG_ 2566892448 PhoneBookListText "Mch.Audio.APLGP.PhoneBookListText";
BA_ "VssSig" SG_ 2566892704 LargeIndexText "Mch.Audio.ALITGP.LargeIndexText";
BA_ "VssSig" SG_ 2566892960 DabDlsMsg "Mch.Audio.ADLSGP.DabDlsMsg";
BA_ "VssSig" SG_ 2566893216 IncomingCallText "Mch.Audio.AICTGP.IncomingCallText";
BA_ "VssSig" SG_ 2566893620 Id "Mch.SMK.SMKC.Id";
BA_ "VssSig" SG_ 2566893620 SwVer "Mch.SMK.SMKC.SwVer";
BA_ "VssSig" SG_ 2566893620 WrnFobImmo "Mch.SMK.SMKC.WrnFobImmo";
BA_ "VssSig" SG_ 2566893620 WrnFobLowBat "Mch.SMK.SMKC.WrnFobLowBat";
BA_ "VssSig" SG_ 2566893620 WrnNoFob "Mch.SMK.SMKC.WrnNoFob";
BA_ "VssSig" SG_ 2566893620 FobCnt "Mch.SMK.SMKC.FobCnt";
BA_ "VssSig" SG_ 2566893620 FobRgstFdbk "Mch.SMK.SMKC.FobRgstFdbk";
BA_ "VssSig" SG_ 2566893620 PreheatSt "Mch.SMK.SMKC.PreheatSt";
BA_ "VssSig" SG_ 2566893620 LampSt "Mch.SMK.SMKC.LampSt";
BA_ "VssSig" SG_ 2566893620 VentTmpSet "Mch.SMK.SMKC.VentTmpSet";
BA_ "VssSig" SG_ 2566893620 HvacSt "Mch.SMK.SMKC.HvacSt";
BA_ "VssSig" SG_ 2566893620 DoorLckSt "Mch.SMK.SMKC.DoorLckSt";
BA_ "VssSig" SG_ 2566894154 RmEgIdleTm "Mch.TGU.SMKCMD.RmEgIdleTm";
BA_ "VssSig" SG_ 2566894154 RmEgIdleMn "Mch.TGU.SMKCMD.RmEgIdleMn";
BA_ "VssSig" SG_ 2566894154 Beacon "Mch.TGU.SMKCMD.Beacon";
BA_ "VssSig" SG_ 2566894154 Horn "Mch.TGU.SMKCMD.Horn";
BA_ "VssSig" SG_ 2566894154 DoorRls "Mch.TGU.SMKCMD.DoorRls";
BA_ "VssSig" SG_ 2566894154 Lamp "Mch.TGU.SMKCMD.Lamp";
BA_ "VssSig" SG_ 2566894154 RmCrank "Mch.TGU.SMKCMD.RmCrank";
BA_ "VssSig" SG_ 2566894154 VentTmpSet "Mch.TGU.SMKCMD.VentTmpSet";
BA_ "VssSig" SG_ 2566894154 Hvac "Mch.TGU.SMKCMD.Hvac";
BA_ "VssSig" SG_ 2566894154 DoorLck "Mch.TGU.SMKCMD.DoorLck";
BA_ "VssSig" SG_ 2566894388 Acc10mUserCheck "Mch.SMK.SMKI.Acc10mUserCheck";
BA_ "VssSig" SG_ 2566894388 WelcomeSoundSetSt "Mch.SMK.SMKI.WelcomeSoundSetSt";
BA_ "VssSig" SG_ 2566894388 ResRmCrank "Mch.SMK.SMKI.ResRmCrank";
BA_ "VssSig" SG_ 2566894388 NotWorkinCdt "Mch.SMK.SMKI.NotWorkinCdt";
BA_ "VssSig" SG_ 2566894388 CabTmp "Mch.SMK.SMKI.CabTmp";
BA_ "VssSig" SG_ 2566894388 RmCrankSt "Mch.SMK.SMKI.RmCrankSt";
BA_ "VssSig" SG_ 2566894388 BeaconSt "Mch.SMK.SMKI.BeaconSt";
BA_ "VssSig" SG_ 2566894388 MtDoorSt "Mch.SMK.SMKI.MtDoorSt";
BA_ "VssSig" SG_ 2566894388 CabDoorSt "Mch.SMK.SMKI.CabDoorSt";
BA_ "VssSig" SG_ 2566894388 FobBatSt "Mch.SMK.SMKI.FobBatSt";
BA_ "VssSig" SG_ 2566894388 MchTonage "Mch.SMK.SMKI.MchTonage";
BA_ "VssSig" SG_ 2566894388 MchModel "Mch.SMK.SMKI.MchModel";
BA_ "VssSig" SG_ 2566894388 FobDtt "Mch.SMK.SMKI.FobDtt";
BA_ "VssSig" SG_ 2566894388 KeySt "Mch.SMK.SMKI.KeySt";
BA_ "VssSig" SG_ 2566896131 CTLLhRvsTrvlPmpVv "Mch.TCU.TM5V.CTLLhRvsTrvlPmpVv";
BA_ "VssSig" SG_ 2566896131 CTLLhFwdTrvlPmpVv "Mch.TCU.TM5V.CTLLhFwdTrvlPmpVv";
BA_ "VssSig" SG_ 2566896131 CTLRhRvsTrvlPmpVv "Mch.TCU.TM5V.CTLRhRvsTrvlPmpVv";
BA_ "VssSig" SG_ 2566896131 CTLRhFwdTrvlPmpVv "Mch.TCU.TM5V.CTLRhFwdTrvlPmpVv";
BA_ "VssSig" SG_ 2566896387 TrkLdTypeAutoShift "Mch.TCU.TM4V.TrkLdTypeAutoShift";
BA_ "VssSig" SG_ 2566896387 LPumpAngSsCh2 "Mch.TCU.TM4V.LPumpAngSsCh2";
BA_ "VssSig" SG_ 2566896387 LPumpAngSsCh1 "Mch.TCU.TM4V.LPumpAngSsCh1";
BA_ "VssSig" SG_ 2566896387 RPumpAngSsCh2 "Mch.TCU.TM4V.RPumpAngSsCh2";
BA_ "VssSig" SG_ 2566896387 RPumpAngSsCh1 "Mch.TCU.TM4V.RPumpAngSsCh1";
BA_ "VssSig" SG_ 2566896387 TrkLdTypeSyb2Spd "Mch.TCU.TM4V.TrkLdTypeSyb2Spd";
BA_ "VssSig" SG_ 2566896387 HstCutOffSVSt "Mch.TCU.TM4V.HstCutOffSVSt";
BA_ "VssSig" SG_ 2566896387 TwoSpdSVSt "Mch.TCU.TM4V.TwoSpdSVSt";
BA_ "VssSig" SG_ 2566896387 TrkLdTypeSybCreep "Mch.TCU.TM4V.TrkLdTypeSybCreep";
BA_ "VssSig" SG_ 2566896643 TrvlSpdPreset4RvsExtd "Mch.TCU.TCUHG.TrvlSpdPreset4RvsExtd";
BA_ "VssSig" SG_ 2566896643 TrvlSpdPreset4FwdExtd "Mch.TCU.TCUHG.TrvlSpdPreset4FwdExtd";
BA_ "VssSig" SG_ 2566896643 TrvlSpdPreset3RvsExtd "Mch.TCU.TCUHG.TrvlSpdPreset3RvsExtd";
BA_ "VssSig" SG_ 2566896643 TrvlSpdPreset3FwdExtd "Mch.TCU.TCUHG.TrvlSpdPreset3FwdExtd";
BA_ "VssSig" SG_ 2566896643 TrvlSpdPreset2RvsExtd "Mch.TCU.TCUHG.TrvlSpdPreset2RvsExtd";
BA_ "VssSig" SG_ 2566896643 TrvlSpdPreset2FwdExtd "Mch.TCU.TCUHG.TrvlSpdPreset2FwdExtd";
BA_ "VssSig" SG_ 2566896643 TrvlSpdPreset1RvsExtd "Mch.TCU.TCUHG.TrvlSpdPreset1RvsExtd";
BA_ "VssSig" SG_ 2566896643 TrvlSpdPreset1FwdExtd "Mch.TCU.TCUHG.TrvlSpdPreset1FwdExtd";
BA_ "VssSig" SG_ 2566896643 JoyStrSsAdj "Mch.TCU.TCUHG.JoyStrSsAdj";
BA_ "VssSig" SG_ 2566896643 TrvlSpdPrmtCor "Mch.TCU.TCUHG.TrvlSpdPrmtCor";
BA_ "VssSig" SG_ 2566896643 SetMaxSpdLimit "Mch.TCU.TCUHG.SetMaxSpdLimit";
BA_ "VssSig" SG_ 2566896643 SetStrDriftCompensation "Mch.TCU.TCUHG.SetStrDriftCompensation";
BA_ "VssSig" SG_ 2566896643 SetCreepMaxSpd "Mch.TCU.TCUHG.SetCreepMaxSpd";
BA_ "VssSig" SG_ 2566896643 SetJoyTrvlRLTrk "Mch.TCU.TCUHG.SetJoyTrvlRLTrk";
BA_ "VssSig" SG_ 2566896643 TrvlSpdPreset4Rvs "Mch.TCU.TCUHG.TrvlSpdPreset4Rvs";
BA_ "VssSig" SG_ 2566896643 TrvlSpdPreset4Fwd "Mch.TCU.TCUHG.TrvlSpdPreset4Fwd";
BA_ "VssSig" SG_ 2566896643 TrvlSpdPreset3Rvs "Mch.TCU.TCUHG.TrvlSpdPreset3Rvs";
BA_ "VssSig" SG_ 2566896643 TrvlSpdPreset3Fwd "Mch.TCU.TCUHG.TrvlSpdPreset3Fwd";
BA_ "VssSig" SG_ 2566896643 TrvlSpdPreset2Rvs "Mch.TCU.TCUHG.TrvlSpdPreset2Rvs";
BA_ "VssSig" SG_ 2566896643 TrvlSpdPreset2Fwd "Mch.TCU.TCUHG.TrvlSpdPreset2Fwd";
BA_ "VssSig" SG_ 2566896643 TrvlSpdPreset1Rvs "Mch.TCU.TCUHG.TrvlSpdPreset1Rvs";
BA_ "VssSig" SG_ 2566896643 TrvlSpdPreset1Fwd "Mch.TCU.TCUHG.TrvlSpdPreset1Fwd";
BA_ "VssSig" SG_ 2566896643 TrvlSpdSet "Mch.TCU.TCUHG.TrvlSpdSet";
BA_ "VssSig" SG_ 2566896643 BrkPdlDecel "Mch.TCU.TCUHG.BrkPdlDecel";
BA_ "VssSig" SG_ 2365570307 LhTrvlMotorEpprVv "Mch.TCU.TM1V.LhTrvlMotorEpprVv";
BA_ "VssSig" SG_ 2365570307 RhTrvlMotorEpprVv "Mch.TCU.TM1V.RhTrvlMotorEpprVv";
BA_ "VssSig" SG_ 2365570307 LhRvsTrvlPmpEpprVv "Mch.TCU.TM1V.LhRvsTrvlPmpEpprVv";
BA_ "VssSig" SG_ 2365570307 LhFwdTrvlPmpEpprVv "Mch.TCU.TM1V.LhFwdTrvlPmpEpprVv";
BA_ "VssSig" SG_ 2365570307 RhRvsTrvlPmpEpprVv "Mch.TCU.TM1V.RhRvsTrvlPmpEpprVv";
BA_ "VssSig" SG_ 2365570307 RhFwdTrvlPmpEpprVv "Mch.TCU.TM1V.RhFwdTrvlPmpEpprVv";
BA_ "VssSig" SG_ 2365570307 VhcSpd "Mch.TCU.TM1V.VhcSpd";
BA_ "VssSig" SG_ 2365570307 CurRvsMaxSpd "Mch.TCU.TM1V.CurRvsMaxSpd";
BA_ "VssSig" SG_ 2365570307 CurFwdMaxSpd "Mch.TCU.TM1V.CurFwdMaxSpd";
BA_ "VssSig" SG_ 2365570307 Fnr "Mch.TCU.TM1V.Fnr";
BA_ "VssSig" SG_ 2566897155 LhTrvlMotorSpdSs "Mch.TCU.TM2V.LhTrvlMotorSpdSs";
BA_ "VssSig" SG_ 2566897155 RhTrvlMotorSpdSs "Mch.TCU.TM2V.RhTrvlMotorSpdSs";
BA_ "VssSig" SG_ 2566897155 LhRvsTrvlPmpPrsSs "Mch.TCU.TM2V.LhRvsTrvlPmpPrsSs";
BA_ "VssSig" SG_ 2566897155 LhFwdTrvlPmpPrsSs "Mch.TCU.TM2V.LhFwdTrvlPmpPrsSs";
BA_ "VssSig" SG_ 2566897155 RhRvsTrvlPmpPrsSs "Mch.TCU.TM2V.RhRvsTrvlPmpPrsSs";
BA_ "VssSig" SG_ 2566897155 RhFwdtPmpPrsSs "Mch.TCU.TM2V.RhFwdtPmpPrsSs";
BA_ "VssSig" SG_ 2566897411 ParkingBrkReqSt "Mch.TCU.TM3V.ParkingBrkReqSt";
BA_ "VssSig" SG_ 2566897411 CurPwrMd "Mch.TCU.TM3V.CurPwrMd";
BA_ "VssSig" SG_ 2566897411 CurRvsMaxSpd "Mch.TCU.TM3V.CurRvsMaxSpd";
BA_ "VssSig" SG_ 2566897411 CurFwdMaxSpd "Mch.TCU.TM3V.CurFwdMaxSpd";
BA_ "VssSig" SG_ 2566897411 BrkAngSs2Pct "Mch.TCU.TM3V.BrkAngSs2Pct";
BA_ "VssSig" SG_ 2566897411 BrkAngSs1Pct "Mch.TCU.TM3V.BrkAngSs1Pct";
BA_ "VssSig" SG_ 2566897411 FootPdlPct "Mch.TCU.TM3V.FootPdlPct";
BA_ "VssSig" SG_ 2566897411 BrkAngSs2Vlt "Mch.TCU.TM3V.BrkAngSs2Vlt";
BA_ "VssSig" SG_ 2566897411 BrkAngSs1Vlt "Mch.TCU.TM3V.BrkAngSs1Vlt";
BA_ "VssSig" SG_ 2566897411 EgCtrlDVlt "Mch.TCU.TM3V.EgCtrlDVlt";
BA_ "VssSig" SG_ 2365571105 MsgChecksum "Mch.MCU.VM1T.MsgChecksum";
BA_ "VssSig" SG_ 2365571105 MsgCnt "Mch.MCU.VM1T.MsgCnt";
BA_ "VssSig" SG_ 2365571105 LwIdleUpMd "Mch.MCU.VM1T.LwIdleUpMd";
BA_ "VssSig" SG_ 2365571105 TwoSpdReadySt "Mch.MCU.VM1T.TwoSpdReadySt";
BA_ "VssSig" SG_ 2365571105 EgDeratingCtrl "Mch.MCU.VM1T.EgDeratingCtrl";
BA_ "VssSig" SG_ 2365571105 DmsActCmd "Mch.MCU.VM1T.DmsActCmd";
BA_ "VssSig" SG_ 2365571105 CstSpdCtrlReqSpd "Mch.MCU.VM1T.CstSpdCtrlReqSpd";
BA_ "VssSig" SG_ 2365571105 HydTmp "Mch.MCU.VM1T.HydTmp";
BA_ "VssSig" SG_ 2365571105 FootPdlPct "Mch.MCU.VM1T.FootPdlPct";
BA_ "VssSig" SG_ 2365571105 RpmReqMd "Mch.MCU.VM1T.RpmReqMd";
BA_ "VssSig" SG_ 2365571105 ReqRvsMaxSpd "Mch.MCU.VM1T.ReqRvsMaxSpd";
BA_ "VssSig" SG_ 2365571105 ReqFwdMaxSpd "Mch.MCU.VM1T.ReqFwdMaxSpd";
BA_ "VssSig" SG_ 2365571105 PowMd "Mch.MCU.VM1T.PowMd";
BA_ "VssSig" SG_ 2365571105 IsParking "Mch.MCU.VM1T.IsParking";
BA_ "VssSig" SG_ 2365571105 TractionCtrl "Mch.MCU.VM1T.TractionCtrl";
BA_ "VssSig" SG_ 2365571361 MsgChecksum "Mch.MCU.VM2T.MsgChecksum";
BA_ "VssSig" SG_ 2365571361 MsgCounter "Mch.MCU.VM2T.MsgCounter";
BA_ "VssSig" SG_ 2365571361 OprtPresenceSt "Mch.MCU.VM2T.OprtPresenceSt";
BA_ "VssSig" SG_ 2365571361 EgCtrlDialVlt "Mch.MCU.VM2T.EgCtrlDialVlt";
BA_ "VssSig" SG_ 2365572608 VgtCmdSt "Mch.ECU.VGTPosCmd.VgtCmdSt";
BA_ "VssSig" SG_ 2365572608 VgtNzPos "Mch.ECU.VGTPosCmd.VgtNzPos";
BA_ "VssSig" SG_ 2566901763 RandomVal "Mch.TCU.HSDI.RandomVal";
BA_ "VssSig" SG_ 2566901793 RandomVal "Mch.MCU.HSDI.RandomVal";
BA_ "VssSig" SG_ 2566902049 DacTiltAutoMdSel "Mch.MCU.FSDI.DacTiltAutoMdSel";
BA_ "VssSig" SG_ 2566902049 DacLiftAutoMdSel "Mch.MCU.FSDI.DacLiftAutoMdSel";
BA_ "VssSig" SG_ 2566902049 BladeLoadTgSet "Mch.MCU.FSDI.BladeLoadTgSet";
BA_ "VssSig" SG_ 2566902049 OverturnWarn "Mch.MCU.FSDI.OverturnWarn";
BA_ "VssSig" SG_ 2566902049 EmcvBckSsSet "Mch.MCU.FSDI.EmcvBckSsSet";
BA_ "VssSig" SG_ 2566902049 MaxFlwRateofElecPwrStrSet "Mch.MCU.FSDI.MaxFlwRateofElecPwrStrSet";
BA_ "VssSig" SG_ 2566902049 EmcvArmSsSet "Mch.MCU.FSDI.EmcvArmSsSet";
BA_ "VssSig" SG_ 2566902049 ElecPwrStrSsSet "Mch.MCU.FSDI.ElecPwrStrSsSet";
BA_ "VssSig" SG_ 2566902049 PriLogicValve "Mch.MCU.FSDI.PriLogicValve";
BA_ "VssSig" SG_ 2566902049 AdvancedWgh "Mch.MCU.FSDI.AdvancedWgh";
BA_ "VssSig" SG_ 2566902049 HydAux2 "Mch.MCU.FSDI.HydAux2		";
BA_ "VssSig" SG_ 2566902049 HhSpdDrvMd "Mch.MCU.FSDI.HhSpdDrvMd";
BA_ "VssSig" SG_ 2566902049 SocChgLmt "Mch.MCU.FSDI.SocChgLmt";
BA_ "VssSig" SG_ 2566902049 HeavyAtt "Mch.MCU.FSDI.HeavyAtt";
BA_ "VssSig" SG_ 2566902049 AutoReturntoDig "Mch.MCU.FSDI.AutoReturntoDig";
BA_ "VssSig" SG_ 2566902049 ExtraOilCool "Mch.MCU.FSDI.ExtraOilCool";
BA_ "VssSig" SG_ 2566902049 ArmDumpSplCmdOffset "Mch.MCU.FSDI.ArmDumpSplCmdOffset";
BA_ "VssSig" SG_ 2566902049 ArmCrowdSplCmdOffset "Mch.MCU.FSDI.ArmCrowdSplCmdOffset";
BA_ "VssSig" SG_ 2566902049 BckDumpSplCmdOffset "Mch.MCU.FSDI.BckDumpSplCmdOffset";
BA_ "VssSig" SG_ 2566902049 BckCrowdSplCmdOffset "Mch.MCU.FSDI.BckCrowdSplCmdOffset";
BA_ "VssSig" SG_ 2566902049 BoomDnSplCmdOffset "Mch.MCU.FSDI.BoomDnSplCmdOffset";
BA_ "VssSig" SG_ 2566902049 BoomUpSplCmdOffset "Mch.MCU.FSDI.BoomUpSplCmdOffset";
BA_ "VssSig" SG_ 2566902049 NonStdTireWhlSizeMn "Mch.MCU.FSDI.NonStdTireWhlSizeMn";
BA_ "VssSig" SG_ 2566902049 StdTireSizeSel "Mch.MCU.FSDI.StdTireSizeSel";
BA_ "VssSig" SG_ 2566902049 TireMaker "Mch.MCU.FSDI.TireMaker";
BA_ "VssSig" SG_ 2566902049 FourthCstFlwStep "Mch.MCU.FSDI.FourthCstFlwStep";
BA_ "VssSig" SG_ 2566902049 ParallelLiftSsSet "Mch.MCU.FSDI.ParallelLiftSsSet";
BA_ "VssSig" SG_ 2566902049 RlsofFlwRstrforCombiOpr "Mch.MCU.FSDI.RlsofFlwRstrforCombiOpr";
BA_ "VssSig" SG_ 2566902049 RedPrsRmv "Mch.MCU.FSDI.RedPrsRmv";
BA_ "VssSig" SG_ 2566902049 GreenBeacon "Mch.MCU.FSDI.GreenBeacon";
BA_ "VssSig" SG_ 2566902049 LockValve "Mch.MCU.FSDI.LockValve";
BA_ "VssSig" SG_ 2566902049 TiltRttExtra2Ivt "Mch.MCU.FSDI.TiltRttExtra2Ivt";
BA_ "VssSig" SG_ 2566902049 TiltRttExtra1Ivt "Mch.MCU.FSDI.TiltRttExtra1Ivt";
BA_ "VssSig" SG_ 2566902049 TiltRttIvt "Mch.MCU.FSDI.TiltRttIvt";
BA_ "VssSig" SG_ 2566902049 TiltRttTiltIvt "Mch.MCU.FSDI.TiltRttTiltIvt";
BA_ "VssSig" SG_ 2566902049 AutoDig "Mch.MCU.FSDI.AutoDig";
BA_ "VssSig" SG_ 2566902049 ShtShiftAst "Mch.MCU.FSDI.ShtShiftAst";
BA_ "VssSig" SG_ 2566902049 OptShtShiftAst "Mch.MCU.FSDI.OptShtShiftAst";
BA_ "VssSig" SG_ 2566902049 Actjoy "Mch.MCU.FSDI.Actjoy";
BA_ "VssSig" SG_ 2566902049 MultiFncBtnSelforWld "Mch.MCU.FSDI.MultiFncBtnSelforWld";
BA_ "VssSig" SG_ 2566902049 KickDnShiftMd "Mch.MCU.FSDI.KickDnShiftMd";
BA_ "VssSig" SG_ 2566902049 BckShake "Mch.MCU.FSDI.BckShake";
BA_ "VssSig" SG_ 2566902049 ElecExcvCableType "Mch.MCU.FSDI.ElecExcvCableType";
BA_ "VssSig" SG_ 2566902049 EStop "Mch.MCU.FSDI.EStop";
BA_ "VssSig" SG_ 2566902049 LineRedPrsRmvSet "Mch.MCU.FSDI.LineRedPrsRmvSet";
BA_ "VssSig" SG_ 2566902049 OutTrgFR "Mch.MCU.FSDI.OutTrgFR";
BA_ "VssSig" SG_ 2566902049 OutTrgFL "Mch.MCU.FSDI.OutTrgFL";
BA_ "VssSig" SG_ 2566902049 RrDz "Mch.MCU.FSDI.RrDz";
BA_ "VssSig" SG_ 2566902049 FrDz "Mch.MCU.FSDI.FrDz";
BA_ "VssSig" SG_ 2566902049 RrDzorOutTrg "Mch.MCU.FSDI.RrDzorOutTrg";
BA_ "VssSig" SG_ 2566902049 FrDzorOutTrg "Mch.MCU.FSDI.FrDzorOutTrg";
BA_ "VssSig" SG_ 2566902049 APMdPwrRngMax "Mch.MCU.FSDI.APMdPwrRngMax";
BA_ "VssSig" SG_ 2566902049 APMdPwrRngMin "Mch.MCU.FSDI.APMdPwrRngMin";
BA_ "VssSig" SG_ 2566902049 AgsIntervalTm "Mch.MCU.FSDI.AgsIntervalTm";
BA_ "VssSig" SG_ 2566902049 AgsOprTm "Mch.MCU.FSDI.AgsOprTm";
BA_ "VssSig" SG_ 2566902049 RrAxleTirePrsTh "Mch.MCU.FSDI.RrAxleTirePrsTh";
BA_ "VssSig" SG_ 2566902049 FrAxleTirePrsTh "Mch.MCU.FSDI.FrAxleTirePrsTh";
BA_ "VssSig" SG_ 2566902049 OutTrgRR "Mch.MCU.FSDI.OutTrgRR";
BA_ "VssSig" SG_ 2566902049 OutTrgRL "Mch.MCU.FSDI.OutTrgRL";
BA_ "VssSig" SG_ 2566902049 CTLCanopy "Mch.MCU.FSDI.CTLCanopy";
BA_ "VssSig" SG_ 2566902049 Radar "Mch.MCU.FSDI.Radar";
BA_ "VssSig" SG_ 2566902049 Savm "Mch.MCU.FSDI.Savm";
BA_ "VssSig" SG_ 2566902049 FineSwg "Mch.MCU.FSDI.FineSwg";
BA_ "VssSig" SG_ 2566902049 HhlandOpt "Mch.MCU.FSDI.HhlandOpt";
BA_ "VssSig" SG_ 2566902049 SmartAssist "Mch.MCU.FSDI.SmartAssist";
BA_ "VssSig" SG_ 2566902049 PhmPremium "Mch.MCU.FSDI.PhmPremium";
BA_ "VssSig" SG_ 2566902049 PhmBasic "Mch.MCU.FSDI.PhmBasic";
BA_ "VssSig" SG_ 2566902049 RrSspnAutoMd "Mch.MCU.FSDI.RrSspnAutoMd";
BA_ "VssSig" SG_ 2566902049 FrSspnMd "Mch.MCU.FSDI.FrSspnMd";
BA_ "VssSig" SG_ 2566902049 AdtMaxCriterionWghVal "Mch.MCU.FSDI.AdtMaxCriterionWghVal";
BA_ "VssSig" SG_ 2566902049 SetOwdActn "Mch.MCU.FSDI.SetOwdActn";
BA_ "VssSig" SG_ 2566902049 RvsFanDurationTmData "Mch.MCU.FSDI.RvsFanDurationTmData";
BA_ "VssSig" SG_ 2566902049 OptSetMaterialHandlerFr "Mch.MCU.FSDI.OptSetMaterialHandlerFr";
BA_ "VssSig" SG_ 2566902049 LHJoyStrSet "Mch.MCU.FSDI.LHJoyStrSet";
BA_ "VssSig" SG_ 2566902049 AutoHold "Mch.MCU.FSDI.AutoHold";
BA_ "VssSig" SG_ 2566902049 SetStickStr "Mch.MCU.FSDI.SetStickStr";
BA_ "VssSig" SG_ 2566902049 OptSetCdsRvsFanAutoPrd "Mch.MCU.FSDI.OptSetCdsRvsFanAutoPrd";
BA_ "VssSig" SG_ 2566902049 OptSetTrailer "Mch.MCU.FSDI.OptSetTrailer";
BA_ "VssSig" SG_ 2566902049 OptSetEscortWrkLmp "Mch.MCU.FSDI.OptSetEscortWrkLmp";
BA_ "VssSig" SG_ 2566902049 OptSetCdsRvsFanMd "Mch.MCU.FSDI.OptSetCdsRvsFanMd";
BA_ "VssSig" SG_ 2566902049 OptSetRttDir "Mch.MCU.FSDI.OptSetRttDir";
BA_ "VssSig" SG_ 2566902049 OptSetAdvLv "Mch.MCU.FSDI.OptSetAdvLv";
BA_ "VssSig" SG_ 2566902049 OptSetGndSaw "Mch.MCU.FSDI.OptSetGndSaw";
BA_ "VssSig" SG_ 2566902049 OptSetTpms "Mch.MCU.FSDI.OptSetTpms";
BA_ "VssSig" SG_ 2566902049 OptSetAutoBrkrSens "Mch.MCU.FSDI.OptSetAutoBrkrSens";
BA_ "VssSig" SG_ 2566902049 OptSetAntiBlankFire "Mch.MCU.FSDI.OptSetAntiBlankFire";
BA_ "VssSig" SG_ 2566902049 OptSetJoyBoom "Mch.MCU.FSDI.OptSetJoyBoom";
BA_ "VssSig" SG_ 2566902049 OptSetJoyTilt "Mch.MCU.FSDI.OptSetJoyTilt";
BA_ "VssSig" SG_ 2566902049 OptSetCoolFanType "Mch.MCU.FSDI.OptSetCoolFanType";
BA_ "VssSig" SG_ 2566902049 FourthCstFlwSet "Mch.MCU.FSDI.FourthCstFlwSet";
BA_ "VssSig" SG_ 2566902049 OptParallelLiftActn "Mch.MCU.FSDI.OptParallelLiftActn";
BA_ "VssSig" SG_ 2566902049 OptSetHhFw "Mch.MCU.FSDI.OptSetHhFw";
BA_ "VssSig" SG_ 2566902049 OptSet3DMgMc3rd "Mch.MCU.FSDI.OptSet3DMgMc3rd";
BA_ "VssSig" SG_ 2566902049 OptSetRrCabLmp "Mch.MCU.FSDI.OptSetRrCabLmp";
BA_ "VssSig" SG_ 2566902049 OptSetDzMc "Mch.MCU.FSDI.OptSetDzMc";
BA_ "VssSig" SG_ 2566902049 OptSetTrqCvtLckUp "Mch.MCU.FSDI.OptSetTrqCvtLckUp";
BA_ "VssSig" SG_ 2566902049 OptSetTwThwDir "Mch.MCU.FSDI.OptSetTwThwDir";
BA_ "VssSig" SG_ 2566902049 OptSetOptPdlType2 "Mch.MCU.FSDI.OptSetOptPdlType2";
BA_ "VssSig" SG_ 2566902049 OptSetMaxTrvlSpd "Mch.MCU.FSDI.OptSetMaxTrvlSpd";
BA_ "VssSig" SG_ 2566902049 OptSetRollSlope "Mch.MCU.FSDI.OptSetRollSlope";
BA_ "VssSig" SG_ 2566902049 OptSetDaac "Mch.MCU.FSDI.OptSetDaac";
BA_ "VssSig" SG_ 2566902049 OptSetRvsLmpFuncAct "Mch.MCU.FSDI.OptSetRvsLmpFuncAct";
BA_ "VssSig" SG_ 2566902049 OptSetBladeAngSens "Mch.MCU.FSDI.OptSetBladeAngSens";
BA_ "VssSig" SG_ 2566902049 OptSetRaiseDnSens "Mch.MCU.FSDI.OptSetRaiseDnSens";
BA_ "VssSig" SG_ 2566902049 OptSetBladeTiltSens "Mch.MCU.FSDI.OptSetBladeTiltSens";
BA_ "VssSig" SG_ 2566902049 OptSetPchSlope "Mch.MCU.FSDI.OptSetPchSlope";
BA_ "VssSig" SG_ 2566902049 OptSetMrrHt "Mch.MCU.FSDI.OptSetMrrHt";
BA_ "VssSig" SG_ 2566902049 OptSetQckCoolMd "Mch.MCU.FSDI.OptSetQckCoolMd";
BA_ "VssSig" SG_ 2566902049 RttOptSet "Mch.MCU.FSDI.RttOptSet";
BA_ "VssSig" SG_ 2566902049 OptSetTrvlStrgtPdl "Mch.MCU.FSDI.OptSetTrvlStrgtPdl";
BA_ "VssSig" SG_ 2566902049 OptSetJoyType "Mch.MCU.FSDI.OptSetJoyType";
BA_ "VssSig" SG_ 2566902049 OptSetAttCtrl "Mch.MCU.FSDI.OptSetAttCtrl";
BA_ "VssSig" SG_ 2566902049 OptSetTiltRttType "Mch.MCU.FSDI.OptSetTiltRttType";
BA_ "VssSig" SG_ 2566902049 OptSetArtiBoom "Mch.MCU.FSDI.OptSetArtiBoom";
BA_ "VssSig" SG_ 2566902049 OptSetDzBlade "Mch.MCU.FSDI.OptSetDzBlade";
BA_ "VssSig" SG_ 2566902049 OptSetHhLift "Mch.MCU.FSDI.OptSetHhLift";
BA_ "VssSig" SG_ 2566902049 OptSetJoyPtnChange "Mch.MCU.FSDI.OptSetJoyPtnChange";
BA_ "VssSig" SG_ 2566902049 OptSetTrqCvtLookUp "Mch.MCU.FSDI.OptSetTrqCvtLookUp";
BA_ "VssSig" SG_ 2566902049 OptSetDhlAuto "Mch.MCU.FSDI.OptSetDhlAuto";
BA_ "VssSig" SG_ 2566902049 OptSet3DMG "Mch.MCU.FSDI.OptSet3DMG";
BA_ "VssSig" SG_ 2566902049 OptSetTrvlSwgAlm "Mch.MCU.FSDI.OptSetTrvlSwgAlm";
BA_ "VssSig" SG_ 2566902049 OptSetLaserReceiver "Mch.MCU.FSDI.OptSetLaserReceiver";
BA_ "VssSig" SG_ 2566902049 OptSetMgMc "Mch.MCU.FSDI.OptSetMgMc";
BA_ "VssSig" SG_ 2566902049 OptSetDKey "Mch.MCU.FSDI.OptSetDKey";
BA_ "VssSig" SG_ 2566902049 WghWith3D "Mch.MCU.FSDI.WghWith3D";
BA_ "VssSig" SG_ 2566902049 OptSetWirelessChg "Mch.MCU.FSDI.OptSetWirelessChg";
BA_ "VssSig" SG_ 2566902049 OptSetAgs "Mch.MCU.FSDI.OptSetAgs";
BA_ "VssSig" SG_ 2566902049 OptSetCamLmp "Mch.MCU.FSDI.OptSetCamLmp";
BA_ "VssSig" SG_ 2566902049 OptSetWiperType "Mch.MCU.FSDI.OptSetWiperType";
BA_ "VssSig" SG_ 2566902049 OptSetPrsCtrl "Mch.MCU.FSDI.OptSetPrsCtrl";
BA_ "VssSig" SG_ 2566902049 OptSetRollOvr "Mch.MCU.FSDI.OptSetRollOvr";
BA_ "VssSig" SG_ 2566902049 OptSet4WhlStr "Mch.MCU.FSDI.OptSet4WhlStr";
BA_ "VssSig" SG_ 2566902049 OptSetSpool4 "Mch.MCU.FSDI.OptSetSpool4";
BA_ "VssSig" SG_ 2566902049 ThirdCstFlwSet "Mch.MCU.FSDI.ThirdCstFlwSet";
BA_ "VssSig" SG_ 2566902049 ThirdCstFlwStep "Mch.MCU.FSDI.ThirdCstFlwStep";
BA_ "VssSig" SG_ 2566902049 OptSetLisRvsOprSpd "Mch.MCU.FSDI.OptSetLisRvsOprSpd";
BA_ "VssSig" SG_ 2566902049 OptSetFrCabLmp "Mch.MCU.FSDI.OptSetFrCabLmp";
BA_ "VssSig" SG_ 2566902049 OptSetOutRr "Mch.MCU.FSDI.OptSetOutRr";
BA_ "VssSig" SG_ 2566902049 OptSetOutRlRrDz "Mch.MCU.FSDI.OptSetOutRlRrDz";
BA_ "VssSig" SG_ 2566902049 OptSetOutFr "Mch.MCU.FSDI.OptSetOutFr";
BA_ "VssSig" SG_ 2566902049 OptSetOutFlFrDz "Mch.MCU.FSDI.OptSetOutFlFrDz";
BA_ "VssSig" SG_ 2566902049 OptSetJoyStr "Mch.MCU.FSDI.OptSetJoyStr";
BA_ "VssSig" SG_ 2566902049 OptSetRvsTrvlSpdLmt "Mch.MCU.FSDI.OptSetRvsTrvlSpdLmt";
BA_ "VssSig" SG_ 2566902049 OptSetEmcvBoomDnImpactPrevent "Mch.MCU.FSDI.OptSetEmcvBoomDnImpactPrevent";
BA_ "VssSig" SG_ 2566902049 OptSetEmcvBoomUpImpactPrevent "Mch.MCU.FSDI.OptSetEmcvBoomUpImpactPrevent";
BA_ "VssSig" SG_ 2566902049 OptSetEmcvBckDumpImpactPrevent "Mch.MCU.FSDI.OptSetEmcvBckDumpImpactPrevent";
BA_ "VssSig" SG_ 2566902049 OptSetEmcvBckCrowdImpactPrevent "Mch.MCU.FSDI.OptSetEmcvBckCrowdImpactPrevent";
BA_ "VssSig" SG_ 2566902049 OptSetEmcvBckSens "Mch.MCU.FSDI.OptSetEmcvBckSens";
BA_ "VssSig" SG_ 2566902049 OptSetEmcvBoomSens "Mch.MCU.FSDI.OptSetEmcvBoomSens";
BA_ "VssSig" SG_ 2566902049 OptSetEstrJoySens "Mch.MCU.FSDI.OptSetEstrJoySens";
BA_ "VssSig" SG_ 2566902049 OptSetWrkLis "Mch.MCU.FSDI.OptSetWrkLis";
BA_ "VssSig" SG_ 2566902049 OptSetLcInVal "Mch.MCU.FSDI.OptSetLcInVal";
BA_ "VssSig" SG_ 2566902049 OptSetR2InVal "Mch.MCU.FSDI.OptSetR2InVal";
BA_ "VssSig" SG_ 2566902049 OptSetR1InVal "Mch.MCU.FSDI.OptSetR1InVal";
BA_ "VssSig" SG_ 2566902049 OptSetBckWghInVlue "Mch.MCU.FSDI.OptSetBckWghInVlue";
BA_ "VssSig" SG_ 2566902049 OptSetBoomWghInVal "Mch.MCU.FSDI.OptSetBoomWghInVal";
BA_ "VssSig" SG_ 2566902049 OptSetMaxCritWghVal "Mch.MCU.FSDI.OptSetMaxCritWghVal";
BA_ "VssSig" SG_ 2566902049 OptSetHalfCritWghVal "Mch.MCU.FSDI.OptSetHalfCritWghVal";
BA_ "VssSig" SG_ 2566902049 OptSetElecStr "Mch.MCU.FSDI.OptSetElecStr";
BA_ "VssSig" SG_ 2566902049 OptSetRvsFan "Mch.MCU.FSDI.OptSetRvsFan";
BA_ "VssSig" SG_ 2566902049 OptSetRcw "Mch.MCU.FSDI.OptSetRcw";
BA_ "VssSig" SG_ 2566902049 OptSetQckCoupler "Mch.MCU.FSDI.OptSetQckCoupler";
BA_ "VssSig" SG_ 2566902049 OptSetTrvlOrSwgAlm "Mch.MCU.FSDI.OptSetTrvlOrSwgAlm";
BA_ "VssSig" SG_ 2566902049 OptSetSmk "Mch.MCU.FSDI.OptSetSmk";
BA_ "VssSig" SG_ 2566902049 OptSetOwd "Mch.MCU.FSDI.OptSetOwd";
BA_ "VssSig" SG_ 2566902049 OptSetMchNameInit "Mch.MCU.FSDI.OptSetMchNameInit";
BA_ "VssSig" SG_ 2566902049 OptSetEmvcPmcv "Mch.MCU.FSDI.OptSetEmvcPmcv";
BA_ "VssSig" SG_ 2566902049 OptSetAebReq "Mch.MCU.FSDI.OptSetAebReq";
BA_ "VssSig" SG_ 2566902049 OptSetRvsFanOn "Mch.MCU.FSDI.OptSetRvsFanOn";
BA_ "VssSig" SG_ 2566902049 OptSetRvsFanMd "Mch.MCU.FSDI.OptSetRvsFanMd";
BA_ "VssSig" SG_ 2566902049 OptSetWhgWld "Mch.MCU.FSDI.OptSetWhgWld";
BA_ "VssSig" SG_ 2566902049 OptSetHydrostatCalbCmd "Mch.MCU.FSDI.OptSetHydrostatCalbCmd";
BA_ "VssSig" SG_ 2566902049 OptSetClutchCalbCmd "Mch.MCU.FSDI.OptSetClutchCalbCmd";
BA_ "VssSig" SG_ 2566902049 OptSetEmgMd "Mch.MCU.FSDI.OptSetEmgMd";
BA_ "VssSig" SG_ 2566902049 OptSetCreepAct "Mch.MCU.FSDI.OptSetCreepAct";
BA_ "VssSig" SG_ 2566902049 OptSetThw "Mch.MCU.FSDI.OptSetThw";
BA_ "VssSig" SG_ 2566902049 OptSetAxleOilCool "Mch.MCU.FSDI.OptSetAxleOilCool";
BA_ "VssSig" SG_ 2566902049 OptSetAngSs "Mch.MCU.FSDI.OptSetAngSs";
BA_ "VssSig" SG_ 2566902049 OptSetBrkPdlCalb "Mch.MCU.FSDI.OptSetBrkPdlCalb";
BA_ "VssSig" SG_ 2566902049 OptSetCreepGr "Mch.MCU.FSDI.OptSetCreepGr";
BA_ "VssSig" SG_ 2566902049 OptSetLisOprSpd "Mch.MCU.FSDI.OptSetLisOprSpd";
BA_ "VssSig" SG_ 2566902049 OptSetRvsFanTm "Mch.MCU.FSDI.OptSetRvsFanTm";
BA_ "VssSig" SG_ 2566902049 OptSetLis "Mch.MCU.FSDI.OptSetLis";
BA_ "VssSig" SG_ 2566902049 OptSetEmgStr "Mch.MCU.FSDI.OptSetEmgStr";
BA_ "VssSig" SG_ 2566902049 OptSetDhl "Mch.MCU.FSDI.OptSetDhl";
BA_ "VssSig" SG_ 2566902049 OptSetFnr2LeverType "Mch.MCU.FSDI.OptSetFnr2LeverType";
BA_ "VssSig" SG_ 2566902049 OptSetTrmsLmtGr "Mch.MCU.FSDI.OptSetTrmsLmtGr";
BA_ "VssSig" SG_ 2566902049 OptSetTransBck "Mch.MCU.FSDI.OptSetTransBck";
BA_ "VssSig" SG_ 2566902049 OptSetItgtFltBoom "Mch.MCU.FSDI.OptSetItgtFltBoom";
BA_ "VssSig" SG_ 2566902049 OptSetBeacon "Mch.MCU.FSDI.OptSetBeacon";
BA_ "VssSig" SG_ 2566902049 OptSetMultiFuncBtnSel "Mch.MCU.FSDI.OptSetMultiFuncBtnSel";
BA_ "VssSig" SG_ 2566902049 OptSetAutoIdle "Mch.MCU.FSDI.OptSetAutoIdle";
BA_ "VssSig" SG_ 2566902049 MchNo11 "Mch.MCU.FSDI.MchNo11";
BA_ "VssSig" SG_ 2566902049 MchNo10 "Mch.MCU.FSDI.MchNo10";
BA_ "VssSig" SG_ 2566902049 MchNo9 "Mch.MCU.FSDI.MchNo9";
BA_ "VssSig" SG_ 2566902049 MchNo8 "Mch.MCU.FSDI.MchNo8";
BA_ "VssSig" SG_ 2566902049 MchNo7 "Mch.MCU.FSDI.MchNo7";
BA_ "VssSig" SG_ 2566902049 MchNo6 "Mch.MCU.FSDI.MchNo6";
BA_ "VssSig" SG_ 2566902049 MchNo5 "Mch.MCU.FSDI.MchNo5";
BA_ "VssSig" SG_ 2566902049 MchNo4 "Mch.MCU.FSDI.MchNo4";
BA_ "VssSig" SG_ 2566902049 MchNo3 "Mch.MCU.FSDI.MchNo3";
BA_ "VssSig" SG_ 2566902049 MchNo2 "Mch.MCU.FSDI.MchNo2";
BA_ "VssSig" SG_ 2566902049 MchNo1 "Mch.MCU.FSDI.MchNo1";
BA_ "VssSig" SG_ 2566902049 AutoIdleTm "Mch.MCU.FSDI.AutoIdleTm";
BA_ "VssSig" SG_ 2566902049 BrkrOprTm "Mch.MCU.FSDI.BrkrOprTm";
BA_ "VssSig" SG_ 2566902049 OptSetAutoShutOffTm "Mch.MCU.FSDI.OptSetAutoShutOffTm";
BA_ "VssSig" SG_ 2566902049 OptSetAutoShutOff "Mch.MCU.FSDI.OptSetAutoShutOff";
BA_ "VssSig" SG_ 2566902049 OptSetAutoShutOffCancel "Mch.MCU.FSDI.OptSetAutoShutOffCancel";
BA_ "VssSig" SG_ 2566902049 OptSetAutoIdleRpmTmp "Mch.MCU.FSDI.OptSetAutoIdleRpmTmp";
BA_ "VssSig" SG_ 2566902049 OptSetSpc "Mch.MCU.FSDI.OptSetSpc";
BA_ "VssSig" SG_ 2566902049 OptSetVoiceWrnCmd "Mch.MCU.FSDI.OptSetVoiceWrnCmd";
BA_ "VssSig" SG_ 2566902049 OptSetBoomSwgUSe "Mch.MCU.FSDI.OptSetBoomSwgUSe";
BA_ "VssSig" SG_ 2566902049 OptSetTrvl2PmpCmbRls "Mch.MCU.FSDI.OptSetTrvl2PmpCmbRls";
BA_ "VssSig" SG_ 2566902049 OptSetTrvl1PmpUse "Mch.MCU.FSDI.OptSetTrvl1PmpUse";
BA_ "VssSig" SG_ 2566902049 OptSetTrmsMaxSpdLmtChk "Mch.MCU.FSDI.OptSetTrmsMaxSpdLmtChk";
BA_ "VssSig" SG_ 2566902049 OptSetHhAlt "Mch.MCU.FSDI.OptSetHhAlt";
BA_ "VssSig" SG_ 2566902049 OptSetRipperOpt "Mch.MCU.FSDI.OptSetRipperOpt";
BA_ "VssSig" SG_ 2566902049 OptSetRttOpt "Mch.MCU.FSDI.OptSetRttOpt";
BA_ "VssSig" SG_ 2566902049 OptSetJoyThwRtt "Mch.MCU.FSDI.OptSetJoyThwRtt";
BA_ "VssSig" SG_ 2566902049 OptSetJoyThwTw "Mch.MCU.FSDI.OptSetJoyThwTw";
BA_ "VssSig" SG_ 2566902049 OptSetTw "Mch.MCU.FSDI.OptSetTw";
BA_ "VssSig" SG_ 2566902049 OptSetOptPdl "Mch.MCU.FSDI.OptSetOptPdl";
BA_ "VssSig" SG_ 2566902049 OptSetAttPdlJoySel "Mch.MCU.FSDI.OptSetAttPdlJoySel";
BA_ "VssSig" SG_ 2566902049 OptSet2Pmp "Mch.MCU.FSDI.OptSet2Pmp";
BA_ "VssSig" SG_ 2566902049 OptSetAttTw "Mch.MCU.FSDI.OptSetAttTw";
BA_ "VssSig" SG_ 2566902049 OptSetAttBrkr "Mch.MCU.FSDI.OptSetAttBrkr";
BA_ "VssSig" SG_ 2566902049 OptSetKeylessUse "Mch.MCU.FSDI.OptSetKeylessUse";
BA_ "VssSig" SG_ 2566902049 OptSetKeyless "Mch.MCU.FSDI.OptSetKeyless";
BA_ "VssSig" SG_ 2566902049 OptSetWiper "Mch.MCU.FSDI.OptSetWiper";
BA_ "VssSig" SG_ 2566902049 OptSetTrvlMotOvrHtWrn "Mch.MCU.FSDI.OptSetTrvlMotOvrHtWrn";
BA_ "VssSig" SG_ 2566902049 OptSetFnrDefault "Mch.MCU.FSDI.OptSetFnrDefault";
BA_ "VssSig" SG_ 2566902049 OptSetFnrSel "Mch.MCU.FSDI.OptSetFnrSel";
BA_ "VssSig" SG_ 2566902049 OptSetCanTypeCmbSw "Mch.MCU.FSDI.OptSetCanTypeCmbSw";
BA_ "VssSig" SG_ 2566902049 UserDtIdx "Mch.MCU.FSDI.UserDtIdx";
BA_ "VssSig" SG_ 2566902049 VhcSerialNo "Mch.MCU.FSDI.VhcSerialNo";
BA_ "VssSig" SG_ 2566902049 OptSetAttWghFactor "Mch.MCU.FSDI.OptSetAttWghFactor";
BA_ "VssSig" SG_ 2566902049 OptSetCanTypeFuelSs "Mch.MCU.FSDI.OptSetCanTypeFuelSs";
BA_ "VssSig" SG_ 2566902049 OptSetSubBrkLmp "Mch.MCU.FSDI.OptSetSubBrkLmp";
BA_ "VssSig" SG_ 2566902049 TiltRttMd "Mch.MCU.FSDI.TiltRttMd";
BA_ "VssSig" SG_ 2566902049 USerLckUnlockSt "Mch.MCU.FSDI.USerLckUnlockSt";
BA_ "VssSig" SG_ 2566902049 UserPw "Mch.MCU.FSDI.UserPw";
BA_ "VssSig" SG_ 2566902049 OptWgh2D "Mch.MCU.FSDI.OptWgh2D";
BA_ "VssSig" SG_ 2566902049 OptMC "Mch.MCU.FSDI.OptMC";
BA_ "VssSig" SG_ 2566902049 OptEgPostHtAct "Mch.MCU.FSDI.OptEgPostHtAct";
BA_ "VssSig" SG_ 2566902049 Opt2DMG "Mch.MCU.FSDI.Opt2DMG";
BA_ "VssSig" SG_ 2566902049 AdminUse2 "Mch.MCU.FSDI.AdminUse2";
BA_ "VssSig" SG_ 2566902049 AdminUse1 "Mch.MCU.FSDI.AdminUse1";
BA_ "VssSig" SG_ 2566902049 AdminUse0 "Mch.MCU.FSDI.AdminUse0";
BA_ "VssSig" SG_ 2566902049 OwnerPw0UpTm "Mch.MCU.FSDI.OwnerPw0UpTm";
BA_ "VssSig" SG_ 2566902049 OwnerPw0Use "Mch.MCU.FSDI.OwnerPw0Use";
BA_ "VssSig" SG_ 2566902049 OwnerPw0 "Mch.MCU.FSDI.OwnerPw0";
VAL_ 2583645002 GpsSt 0 "UNKNOWN" 1 "NO_FIX" 2 "2D" 3 "3D" ;
VAL_ 2583644490 GsmType 0 "GPRS" 1 "EDGE" 3 "UMTS" 4 "HSDPA" 5 "HSUPA" 6 "HSDPA_HSUPA" 7 "1XRTT" 8 "1XEVDO" 9 "1XEVDO_REVA" 10 "1XEVDO_REVB" 11 "1XEVDV" 12 "3XRTT" 13 "UMB" 14 "LTE" 15 "5G_NSA" 16 "5G_SA" ;
VAL_ 2566878282 Type 0 "NONE" 1 "IRIDIUM" ;
VAL_ 2566878282 Enable 0 "FALSE" 1 "TRUE" 2 "ERROR" 3 "NOT_AVAILABLE" ;
VAL_ 2566878794 ActnDrSec 0 "INACTIVE" 1 "ACTIVE" 2 "RESERVED" 3 "NOT_AVAILABLE" ;
VAL_ 2566878794 WifiAntSt 0 "NORMAL" 1 "ERROR1" 2 "ERROR2" 3 "ERROR3" ;
VAL_ 2566878794 CellAntSt 0 "NORMAL" 1 "ERROR1" 2 "ERROR2" 3 "ERROR3" ;
VAL_ 2566878794 GpsAntSt 0 "NORMAL" 1 "ERROR1" 2 "ERROR2" 3 "NOT_AVAILABLE" ;
VAL_ 2566878794 SecCmd 0 "NORMAL" 1 "RPM_LIMIT" 2 "ENGINE_LOCK" 3 "NOT_AVAILABLE" ;
VAL_ 2566879818 KeyType 0 "NONE" 1 "FOB" 2 "DIGITAL_KEY" 3 "KEYLESS" 4 "REMOTE" ;
VAL_ 2566879818 LogIn 0 "FALSE" 1 "TRUE" 2 "ERROR" 3 "NOT_AVAILABLE" ;
VAL_ 2566880296 SelType 0 "NONE" 1 "FOB" 2 "DIGITAL_KEY" 3 "KEYLESS" 4 "REMOTE" ;
VAL_ 2566880586 Ack 0 "FALSE" 1 "TRUE" 2 "ERROR" 3 "NOT_AVAILABLE" ;
VAL_ 2566883328 UreaLvBzSt 0 "OFF" 1 "ON" 2 "ERROR" 3 "NOT_AVAILABLE" ;
VAL_ 2583626273 StartCrkSw 0 "OFF" 1 "ON" 2 "ERROR" 3 "NOT_AVAILABLE" ;
VAL_ 2583626273 GrSelSw 0 "OFF" 1 "ON" 2 "ERROR" 3 "NOT_AVAILABLE" ;
VAL_ 2583626273 GrSelNtrlSw 0 "OFF" 1 "ON" 2 "ERROR" 3 "NOT_AVAILABLE" ;
VAL_ 2583626273 PrkSw 0 "OFF" 1 "ON" 2 "ERROR" 3 "NOT_AVAILABLE" ;
VAL_ 2583626273 GrSelRvsSw 0 "OFF" 1 "ON" 2 "ERROR" 3 "NOT_AVAILABLE" ;
VAL_ 2583626273 GrSelShftDnSw 0 "OFF" 1 "ON" 2 "ERROR" 3 "NOT_AVAILABLE" ;
VAL_ 2583626273 GrSelShftUpSw 0 "OFF" 1 "ON" 2 "ERROR" 3 "NOT_AVAILABLE" ;
VAL_ 2583626273 GrSelFwdSw 0 "OFF" 1 "ON" 2 "ERROR" 3 "NOT_AVAILABLE" ;
VAL_ 2583626273 DustIndSw 0 "OFF" 1 "ON" 2 "ERROR" 3 "NOT_AVAILABLE" ;
VAL_ 2583626273 StartAccSw 0 "OFF" 1 "ON" 2 "ERROR" 3 "NOT_AVAILABLE" ;
VAL_ 2583626273 AtsForceRgnSw 0 "OFF" 1 "ON" 2 "ERROR" 3 "NOT_AVAILABLE" ;
VAL_ 2583626273 AtsRgnIhbsw 0 "OFF" 1 "ON" 2 "ERROR" 3 "NOT_AVAILABLE" ;
VAL_ 2583626273 eFan3ErrSt 0 "OFF" 1 "ON" 2 "ERROR" 3 "NOT_AVAILABLE" ;
VAL_ 2583626273 KeyBrSw 0 "OFF" 1 "ON" 2 "ERROR" 3 "NOT_AVAILABLE" ;
VAL_ 2583626273 TipJoySw 0 "OFF" 1 "ON" 2 "ERROR" 3 "NOT_AVAILABLE" ;
VAL_ 2583626273 AgsSw 0 "OFF" 1 "ON" 2 "ERROR" 3 "NOT_AVAILABLE" ;
VAL_ 2583626273 eFan2ErrSt 0 "OFF" 1 "ON" 2 "ERROR" 3 "NOT_AVAILABLE" ;
VAL_ 2583626273 eFan1ErrSt 0 "OFF" 1 "ON" 2 "ERROR" 3 "NOT_AVAILABLE" ;
VAL_ 2583626273 SeatBeltSt 0 "OFF" 1 "ON" 2 "ERROR" 3 "NOT_AVAILABLE" ;
VAL_ 2583626273 FrWiperStpSw 0 "OFF" 1 "ON" 2 "ERROR" 3 "NOT_AVAILABLE" ;
VAL_ 2583626529 SusRhDn 0 "OFF" 1 "ON" 2 "ERROR" 3 "NOT_AVAILABLE" ;
VAL_ 2583626529 TocRvs 0 "OFF" 1 "ON" 2 "ERROR" 3 "NOT_AVAILABLE" ;
VAL_ 2583626529 TurnSigRhRly 0 "OFF" 1 "ON" 2 "ERROR" 3 "NOT_AVAILABLE" ;
VAL_ 2583626529 TurnSigLhRly 0 "OFF" 1 "ON" 2 "ERROR" 3 "NOT_AVAILABLE" ;
VAL_ 2583626529 SusRhUp 0 "OFF" 1 "ON" 2 "ERROR" 3 "NOT_AVAILABLE" ;
VAL_ 2583626529 EgRunOutSig 0 "OFF" 1 "ON" 2 "ERROR" 3 "NOT_AVAILABLE" ;
VAL_ 2583626529 SusLhDn 0 "OFF" 1 "ON" 2 "ERROR" 3 "NOT_AVAILABLE" ;
VAL_ 2583626529 UreaSuperChgWrnSig 0 "OFF" 1 "ON" 2 "ERROR" 3 "NOT_AVAILABLE" ;
VAL_ 2583626529 FanStpSv 0 "OFF" 1 "ON" 2 "ERROR" 3 "NOT_AVAILABLE" ;
VAL_ 2583626529 SusLhUp 0 "OFF" 1 "ON" 2 "ERROR" 3 "NOT_AVAILABLE" ;
VAL_ 2583626529 PrkBrkRlsSv 0 "OFF" 1 "ON" 2 "ERROR" 3 "NOT_AVAILABLE" ;
VAL_ 2583626529 AxleOilCoolSv 0 "OFF" 1 "ON" 2 "ERROR" 3 "NOT_AVAILABLE" ;
VAL_ 2583626529 TocUnloading 0 "OFF" 1 "ON" 2 "ERROR" 3 "NOT_AVAILABLE" ;
VAL_ 2583626529 AccRly 0 "OFF" 1 "ON" 2 "ERROR" 3 "NOT_AVAILABLE" ;
VAL_ 2583626529 LiftArmFlt 0 "OFF" 1 "ON" 2 "ERROR" 3 "NOT_AVAILABLE" ;
VAL_ 2583626529 AutoShutOffRly 0 "OFF" 1 "ON" 2 "ERROR" 3 "NOT_AVAILABLE" ;
VAL_ 2583626529 BrkChgSv 0 "OFF" 1 "ON" 2 "ERROR" 3 "NOT_AVAILABLE" ;
VAL_ 2566886586 Objinzone6 0 "NO_OBJECT_IN_ZONE" 1 "LEVEL_C" 2 "LEVEL_B" 3 "LEVEL_A" 7 "NOT_AVAILABLE" ;
VAL_ 2566886586 Objinzone5 0 "NO_OBJECT_IN_ZONE" 1 "LEVEL_C" 2 "LEVEL_B" 3 "LEVEL_A" 7 "NOT_AVAILABLE" ;
VAL_ 2566886586 Objinzone4 0 "NO_OBJECT_IN_ZONE" 1 "LEVEL_C" 2 "LEVEL_B" 3 "LEVEL_A" 7 "NOT_AVAILABLE" ;
VAL_ 2566886586 Objinzone3 0 "NO_OBJECT_IN_ZONE" 1 "LEVEL_C" 2 "LEVEL_B" 3 "LEVEL_A" 7 "NOT_AVAILABLE" ;
VAL_ 2566886586 Objinzone2 0 "NO_OBJECT_IN_ZONE" 1 "LEVEL_C" 2 "LEVEL_B" 3 "LEVEL_A" 7 "NOT_AVAILABLE" ;
VAL_ 2566886586 Objinzone1 0 "NO_OBJECT_IN_ZONE" 1 "LEVEL_C" 2 "LEVEL_B" 3 "LEVEL_A" 7 "NOT_AVAILABLE" ;
VAL_ 2566886587 Objinzone6 0 "NO_OBJECT_IN_ZONE" 1 "LEVEL_C" 2 "LEVEL_B" 3 "LEVEL_A" 7 "NOT_AVAILABLE" ;
VAL_ 2566886587 Objinzone5 0 "NO_OBJECT_IN_ZONE" 1 "LEVEL_C" 2 "LEVEL_B" 3 "LEVEL_A" 7 "NOT_AVAILABLE" ;
VAL_ 2566886587 Objinzone4 0 "NO_OBJECT_IN_ZONE" 1 "LEVEL_C" 2 "LEVEL_B" 3 "LEVEL_A" 7 "NOT_AVAILABLE" ;
VAL_ 2566886587 Objinzone3 0 "NO_OBJECT_IN_ZONE" 1 "LEVEL_C" 2 "LEVEL_B" 3 "LEVEL_A" 7 "NOT_AVAILABLE" ;
VAL_ 2566886587 Objinzone2 0 "NO_OBJECT_IN_ZONE" 1 "LEVEL_C" 2 "LEVEL_B" 3 "LEVEL_A" 7 "NOT_AVAILABLE" ;
VAL_ 2566886587 Objinzone1 0 "NO_OBJECT_IN_ZONE" 1 "LEVEL_C" 2 "LEVEL_B" 3 "LEVEL_A" 7 "NOT_AVAILABLE" ;
VAL_ 2566886588 Objinzone6 0 "NO_OBJECT_IN_ZONE" 1 "LEVEL_C" 2 "LEVEL_B" 3 "LEVEL_A" 7 "NOT_AVAILABLE" ;
VAL_ 2566886588 Objinzone5 0 "NO_OBJECT_IN_ZONE" 1 "LEVEL_C" 2 "LEVEL_B" 3 "LEVEL_A" 7 "NOT_AVAILABLE" ;
VAL_ 2566886588 Objinzone4 0 "NO_OBJECT_IN_ZONE" 1 "LEVEL_C" 2 "LEVEL_B" 3 "LEVEL_A" 7 "NOT_AVAILABLE" ;
VAL_ 2566886588 Objinzone3 0 "NO_OBJECT_IN_ZONE" 1 "LEVEL_C" 2 "LEVEL_B" 3 "LEVEL_A" 7 "NOT_AVAILABLE" ;
VAL_ 2566886588 Objinzone2 0 "NO_OBJECT_IN_ZONE" 1 "LEVEL_C" 2 "LEVEL_B" 3 "LEVEL_A" 7 "NOT_AVAILABLE" ;
VAL_ 2566886588 Objinzone1 0 "NO_OBJECT_IN_ZONE" 1 "LEVEL_C" 2 "LEVEL_B" 3 "LEVEL_A" 7 "NOT_AVAILABLE" ;
VAL_ 2566886842 ObjSeq 0 "OBJECT1" 1 "OBJECT2" 2 "OBJECT3" 3 "OBJECT4" 4 "OBJECT5" 5 "OBJECT6" 6 "OBJECT7" 7 "OBJECT8" 8 "OBJECT9" 9 "OBJECT10" ;
VAL_ 2566886843 ObjSeq 0 "OBJECT1" 1 "OBJECT2" 2 "OBJECT3" 3 "OBJECT4" 4 "OBJECT5" 5 "OBJECT6" 6 "OBJECT7" 7 "OBJECT8" 8 "OBJECT9" 9 "OBJECT10" ;
VAL_ 2566886844 ObjSeq 0 "OBJECT1" 1 "OBJECT2" 2 "OBJECT3" 3 "OBJECT4" 4 "OBJECT5" 5 "OBJECT6" 6 "OBJECT7" 7 "OBJECT8" 8 "OBJECT9" 9 "OBJECT10" ;
VAL_ 2566886952 RrVwPriMd 0 "NORMAL_MODE" 1 "PRIORITY_MODE" ;
VAL_ 2566886952 VwMd 0 "TOP" 1 "REAR" 2 "RIGHT" 3 "TOPPLUSREAR" 4 "3D" 5 "BOOM" 15 "NOT_AVAILABLE" ;
VAL_ 2566887223 Tb2ToleranceCompSt 0 "BEFORE_TOLERANCE_CORRECTION" 1 "TOLERANCE_CORRECTING" 2 "TOLERANCE_CORRECTION_COMPLETED" 3 "TOLERANCE_CORRECTION_FAIL" ;
VAL_ 2566887223 Tb2ToleranceCompSetApp 0 "DISABLE" 1 "ENABLE" ;
VAL_ 2566887223 RrVwPriMd 0 "NORMAL_MODE" 1 "PRIORITY_MODE" ;
VAL_ 2566887223 AvmWrnGud 0 "NOT_USED" 1 "AVM_WARNING_GUIDE_LINE_OFF" 2 "AVM_WARNING_GUIDE_LINE_ON" 6 "ERROR" 7 "INVALID" ;
VAL_ 2566887223 AvmSt 0 "NOT_USED" 1 "AVM_NOT_READY_IGN_OFF" 2 "AVM_NORMAL_IGN_ON" 3 "AVM_FAIL" 30 "ERROR" 31 "INVALID" ;
VAL_ 2566887223 AvmUltraBz 0 "ULTRASONIC_ALL_OFF" 1 "LEFT_ACTIVATION" 2 "RIGHR_ACTIVATION" 3 "REAR_ACTIVATION" 4 "LEFT_REAR_ACTIVATION" 5 "LEFT_RIGHT_ACTIVATION" 6 "RIGHT_REAR_ACTIVATION" 7 "LEFT_RIGHT_REAR_ACTIVATION" 14 "ERROR" 15 "INVALID" ;
VAL_ 2566887223 AvmTonSize 0 "NOT_USED" 1 "5T_CRAWLER" 2 "5T_WHEEL" 3 "14T_WHEEL" 4 "21T_WHEEL" 5 "30T_CRAWLER" 14 "ERROR" 15 "INVALID" ;
VAL_ 2566887223 AvmDisplayMsg 0 "NOT_USED" 1 "NO_MESSAGE" 2 "INCAMERACALIBARION_MODE" 62 "WARNING_CHECK_FRONT_RIGHT_LEFT" 63 "WARNING_CHECK_BACK_RIGHT_LEFT" 254 "ERROR" 255 "INVALID" ;
VAL_ 2566887223 AvmOutType 0 "NOT_USED" 1 "AVM_OUTPUT_TYPE_NTSC" 2 "AVM_OUTPUT_TYPE_LVDS" 6 "ERROR" 7 "INVALID" ;
VAL_ 2566887223 AvmVw 0 "TOPVIEW" 1 "REAR_WIDE" 2 "TOP_PLUS_RIGHT" 3 "REAR_PLUS_CORNER" 4 "3D" 5 "BOOM_OPTION" 15 "NOT_AVAILABLE" ;
VAL_ 2566887223 AvmLanguagePack 0 "NOTUSED" 1 "KOREAN_DEFAULT" 2 "ENGLISH" 3 "CHINESE_PRC" 4 "FRENCH_FRANCE" 5 "GERMAN_GERMANY" 6 "DUTCH_NETHERLANDS" 7 "ITALIAN_ITALY" 8 "PORTUGUESE_PORTUGAL" 9 "SPANISH_INTERNATIONAL" 10 "FINNISH" 11 "SWEDISH" 12 "NORWEGIAN_BOKMAL" 13 "DANISH" 14 "JAPANESE" 15 "TURKISH" 16 "INDONESIAN" 17 "POLISH" 18 "RUSSIAN" 19 "ARABIC_SAUDI_ARABIA" 20 "FARSI_PERSIAN" 21 "HINDI" 22 "THAI" 23 "GREEK" 24 "VIETNAMESE" ;
VAL_ 2566887479 UltsSigL6 0 "OFF" 1 "LEVEL_1" 2 "LEVEL_2" 3 "LEVEL_3" 4 "FAULT" 5 "NOISE_ERROR" 14 "ERROR" 15 "INVALID" ;
VAL_ 2566887479 UltsSigR6 0 "OFF" 1 "LEVEL_1" 2 "LEVEL_2" 3 "LEVEL_3" 4 "FAULT" 5 "NOISE_ERROR" 14 "ERROR" 15 "INVALID" ;
VAL_ 2566887479 UltsSigL5 0 "OFF" 1 "LEVEL_1" 2 "LEVEL_2" 3 "LEVEL_3" 4 "FAULT" 5 "NOISE_ERROR" 14 "ERROR" 15 "INVALID" ;
VAL_ 2566887479 UltsSigR5 0 "OFF" 1 "LEVEL_1" 2 "LEVEL_2" 3 "LEVEL_3" 4 "FAULT" 5 "NOISE_ERROR" 14 "ERROR" 15 "INVALID" ;
VAL_ 2566887479 UltsSigL4 0 "OFF" 1 "LEVEL_1" 2 "LEVEL_2" 3 "LEVEL_3" 4 "FAULT" 5 "NOISE_ERROR" 14 "ERROR" 15 "INVALID" ;
VAL_ 2566887479 UltsSigR4 0 "OFF" 1 "LEVEL_1" 2 "LEVEL_2" 3 "LEVEL_3" 4 "FAULT" 5 "NOISE_ERROR" 14 "ERROR" 15 "INVALID" ;
VAL_ 2566887479 UltsSigL3 0 "OFF" 1 "LEVEL_1" 2 "LEVEL_2" 3 "LEVEL_3" 4 "FAULT" 5 "NOISE_ERROR" 14 "ERROR" 15 "INVALID" ;
VAL_ 2566887479 UltsSigR3 0 "OFF" 1 "LEVEL_1" 2 "LEVEL_2" 3 "LEVEL_3" 4 "FAULT" 5 "NOISE_ERROR" 14 "ERROR" 15 "INVALID" ;
VAL_ 2566887479 UltsSigL2 0 "OFF" 1 "LEVEL_1" 2 "LEVEL_2" 3 "LEVEL_3" 4 "FAULT" 5 "NOISE_ERROR" 14 "ERROR" 15 "INVALID" ;
VAL_ 2566887479 UltsSigR2 0 "OFF" 1 "LEVEL_1" 2 "LEVEL_2" 3 "LEVEL_3" 4 "FAULT" 5 "NOISE_ERROR" 14 "ERROR" 15 "INVALID" ;
VAL_ 2566887479 UltsSigL1 0 "OFF" 1 "LEVEL_1" 2 "LEVEL_2" 3 "LEVEL_3" 4 "FAULT" 5 "NOISE_ERROR" 14 "ERROR" 15 "INVALID" ;
VAL_ 2566887479 UltsSigR1 0 "OFF" 1 "LEVEL_1" 2 "LEVEL_2" 3 "LEVEL_3" 4 "FAULT" 5 "NOISE_ERROR" 14 "ERROR" 15 "INVALID" ;
VAL_ 2566887720 CamPrmtCorCompleteSt 0 "NOT_CORRECTED" 1 "CORRECTION_COMPLETED" ;
VAL_ 2566887720 ToleranceCorMenuentryCmd 0 "NO_TOLERANCE_CORRECTION_MENU" 1 "ENTER_TOLERANCE_CORRECTION" ;
VAL_ 2566887720 WrnGudSetCmd 0 "OFF" 1 "ON" 2 "ERROR" 3 "NOT_AVAILABLE" ;
VAL_ 2566887720 UltsSs08Cmd 0 "OFF" 1 "ON" 2 "ERROR" 3 "NOT_AVAILABLE" ;
VAL_ 2566887720 UltsSs07Cmd 0 "OFF" 1 "ON" 2 "ERROR" 3 "NOT_AVAILABLE" ;
VAL_ 2566887720 UltsSs06Cmd 0 "OFF" 1 "ON" 2 "ERROR" 3 "NOT_AVAILABLE" ;
VAL_ 2566887720 UltsSs05Cmd 0 "OFF" 1 "ON" 2 "ERROR" 3 "NOT_AVAILABLE" ;
VAL_ 2566887720 UltsSs04Cmd 0 "OFF" 1 "ON" 2 "ERROR" 3 "NOT_AVAILABLE" ;
VAL_ 2566887720 UltsSs03Cmd 0 "OFF" 1 "ON" 2 "ERROR" 3 "NOT_AVAILABLE" ;
VAL_ 2566887720 UltsSs02Cmd 0 "OFF" 1 "ON" 2 "ERROR" 3 "NOT_AVAILABLE" ;
VAL_ 2566887720 UltsSs01Cmd 0 "OFF" 1 "ON" 2 "ERROR" 3 "NOT_AVAILABLE" ;
VAL_ 2566887720 UltsSs12Cmd 0 "OFF" 1 "ON" 2 "ERROR" 3 "NOT_AVAILABLE" ;
VAL_ 2566887720 UltsSs11Cmd 0 "OFF" 1 "ON" 2 "ERROR" 3 "NOT_AVAILABLE" ;
VAL_ 2566887720 UltsSs10Cmd 0 "OFF" 1 "ON" 2 "ERROR" 3 "NOT_AVAILABLE" ;
VAL_ 2566887720 UltsSs09Cmd 0 "OFF" 1 "ON" 2 "ERROR" 3 "NOT_AVAILABLE" ;
VAL_ 2566887720 SetApplicationCmd 0 "DISABLE" 1 "ENABLE" ;
VAL_ 2566887720 ToleranceCorCmd 0 "BEFORE_TOLERANCE_CORRECTION" 1 "TOLERANCE_CORRECTING" 2 "TOLERANCE_CORRECTION_COMPLETED" 3 "TOLERANCE_CORRECTION_FAIL" ;
VAL_ 2566887720 FactoryReCmd 0 "DISABLE" 1 "ENABLE" ;
VAL_ 2566887720 UltsSsOpt 0 "OPTION_DISABLED" 1 "OPTION_EABLED" ;
VAL_ 2566887720 UltsBuzzerStopSig 0 "ON" 1 "OFF" ;
VAL_ 2566887720 BoomCamOpt 0 "BOOM_CAMERA_DISABLED" 1 "BOOM_CAMERA_ENABLED" ;
VAL_ 2566887720 UltsBzOffSig 0 "ON" 1 "OFF" ;
VAL_ 2566887720 UltsRecognitionDistanceSet 0 "ALL" 1 "UPPER_BODY" ;
VAL_ 2566887720 VhcType2 0 "LC" 1 "LCR" 2 "LL" 3 "NOT_DEFINED" ;
VAL_ 2566887720 VhcType1 0 "WHEEL" 1 "CRAWLER" ;
VAL_ 2566887720 FactoryType 0 "FACTORY_1" 1 "FACTORY_2" 2 "FACTORY_3" 3 "FACTORY_4" ;
VAL_ 2566887720 VwMd 0 "TOP" 1 "REAR" 2 "RIGHT" 3 "TOPPLUSREAR" 4 "3D" 5 "BOOM" 15 "NOT_AVAILABLE" ;
VAL_ 2566887991 CamPrmtCorCompleteSt 0 "NOT_CORRECTED" 1 "CORRECTION_COMPLETED" ;
VAL_ 2566887991 ToleranceCorMenuentryCmd 0 "NO_TOLERANCE_CORRECTION_MENU" 1 "ENTER_TOLERANCE_CORRECTION" ;
VAL_ 2566887991 WrnGudSetCmd 0 "OFF" 1 "ON" 2 "ERROR" 3 "NOT_AVAILABLE" ;
VAL_ 2566887991 UltsSs08Cmd 0 "OFF" 1 "ON" 2 "ERROR" 3 "NOT_AVAILABLE" ;
VAL_ 2566887991 UltsSs07Cmd 0 "OFF" 1 "ON" 2 "ERROR" 3 "NOT_AVAILABLE" ;
VAL_ 2566887991 UltsSs06Cmd 0 "OFF" 1 "ON" 2 "ERROR" 3 "NOT_AVAILABLE" ;
VAL_ 2566887991 UltsSs05Cmd 0 "OFF" 1 "ON" 2 "ERROR" 3 "NOT_AVAILABLE" ;
VAL_ 2566887991 UltsSs04Cmd 0 "OFF" 1 "ON" 2 "ERROR" 3 "NOT_AVAILABLE" ;
VAL_ 2566887991 UltsSs03Cmd 0 "OFF" 1 "ON" 2 "ERROR" 3 "NOT_AVAILABLE" ;
VAL_ 2566887991 UltsSs02Cmd 0 "OFF" 1 "ON" 2 "ERROR" 3 "NOT_AVAILABLE" ;
VAL_ 2566887991 UltsSs01Cmd 0 "OFF" 1 "ON" 2 "ERROR" 3 "NOT_AVAILABLE" ;
VAL_ 2566887991 UltsSs12Cmd 0 "OFF" 1 "ON" 2 "ERROR" 3 "NOT_AVAILABLE" ;
VAL_ 2566887991 UltsSs11Cmd 0 "OFF" 1 "ON" 2 "ERROR" 3 "NOT_AVAILABLE" ;
VAL_ 2566887991 UltsSs10Cmd 0 "OFF" 1 "ON" 2 "ERROR" 3 "NOT_AVAILABLE" ;
VAL_ 2566887991 UltsSs09Cmd 0 "OFF" 1 "ON" 2 "ERROR" 3 "NOT_AVAILABLE" ;
VAL_ 2566887991 SetAppCmd 0 "DISABLE" 1 "ENABLE" ;
VAL_ 2566887991 ToleranceCorCmd 0 "BEFORE_TOLERANCE_CORRECTION" 1 "TOLERANCE_CORRECTING" 2 "TOLERANCE_CORRECTION_COMPLETED" 3 "TOLERANCE_CORRECTION_FAIL" ;
VAL_ 2566887991 FactoryResetCmd 0 "DISABLE" 1 "ENABLE" ;
VAL_ 2566887991 UltsSsOpt 0 "OPTION_DISABLED" 1 "OPTION_EABLED" ;
VAL_ 2566887991 UltsBzStopSig 0 "ON" 1 "OFF" ;
VAL_ 2566887991 BoomCamOpt 0 "BOOM_CAMERA_DISABLED" 1 "BOOM_CAMERA_ENABLED" ;
VAL_ 2566887991 UltsBzOffSig 0 "ON" 1 "OFF" ;
VAL_ 2566887991 UltsRecognitionDistanceSet 0 "ALL" 1 "UPPER_BODY" ;
VAL_ 2566887991 VhcType2 0 "LC" 1 "LCR" 2 "LL" 3 "NOT_DEFINED" ;
VAL_ 2566887991 VhcType1 0 "WHEEL" 1 "CRAWLER" ;
VAL_ 2566887991 FactoryType 0 "FACTORY_1" 1 "FACTORY_2" 2 "FACTORY_3" 3 "FACTORY_4" ;
VAL_ 2566887991 VwMd 0 "TOP" 1 "REAR" 2 "RIGHT" 3 "TOPPLUSREAR" 4 "3D" 5 "BOOM" 15 "NOT_AVAILABLE" ;
VAL_ 2566889512 RvsWarnSt 0 "OFF" 1 "ON" 2 "ERROR" 3 "NOT_AVAILABLE" ;
VAL_ 2566889512 MirrorHtOprtgSig 0 "OFF" 1 "ON" 2 "ERROR" 3 "NOT_AVAILABLE" ;
VAL_ 2566889512 EvMdCmd 0 "NORMAL_MODE" 1 "EV_MODE" 2 "NOT_AVAILABLE" 3 "NOT_AVAILABLE1" ;
VAL_ 2566889512 ObjectSsChmsl 0 "OFF" 1 "ON" 2 "ERROR" 3 "NOT_AVAILABLE" ;
VAL_ 2566889512 KeylessCrankEnbSt 0 "OFF" 1 "ON" 2 "ERROR" 3 "NOT_AVAILABLE" ;
VAL_ 2566889512 DaacmdSt 0 "OFF" 1 "ON" 2 "ERROR" 3 "NOT_AVAILABLE" ;
VAL_ 2566889512 QuickCoolMdSt 0 "OFF" 1 "ON" 2 "ERROR" 3 "NOT_AVAILABLE" ;
VAL_ 2566889512 DzAstMdSt 0 "OFF" 1 "ON" 2 "ERROR" 3 "NOT_AVAILABLE" ;
VAL_ 2566889512 KeyPadPri 0 "KEYPAD" 1 "VIRTUAL_KEPAD" ;
VAL_ 2566889512 TractionMdSt 0 "MAX" 1 "A_3" 2 "B_2" 3 "C_1" 4 "AUTO" ;
VAL_ 2566889512 EgLckSt 0 "UNLOCK_" 1 "LOCK" ;
VAL_ 2566889512 JduseStforRpm 0 "OFF" 1 "ON" 2 "ERROR" 3 "NOT_AVAILABLE" ;
VAL_ 2566889512 AutoIdleMdSt 0 "OFF" 1 "ON" 2 "ERROR" 3 "NOT_AVAILABLE" ;
VAL_ 2566889512 WrkMdSt 0 "DIG" 1 "LIFT" 2 "BREAKER" 3 "TRVMODECR" ;
VAL_ 2566889512 PwrMdSt 0 "STANDARD_MODE" 1 "ECONOMY_MODE" 2 "POWER_PLUS_MODE" 3 "POWER_MODE" ;
VAL_ 2566890280 AttSetSaveFlag 0 "DISABLE" 1 "ENABLE" ;
VAL_ 2566890280 AttType 0 "BREAKER" 1 "TWO_WAY" ;
VAL_ 2566890536 MgSoundGudStep 0 "ALARM_OFF" 1 "ALARM__1" 2 "ALARM__2" 3 "ALARM__3" 4 "ALARM__4" 5 "ALARM__5" 6 "ALARM__6" 7 "ALARM__7" 8 "ALARM__8" 9 "ALARM__9" ;
VAL_ 2566890536 AlmSt 0 "ALARM_OFF" 1 "ALARM__1" 2 "ALARM__2" 3 "ALARM__3" 4 "ALARM__4" 5 "ALARM__5" ;
VAL_ 2566890561 MgSoundGudStep 0 "ALARM_OFF" 1 "ALARM__1" 2 "ALARM__2" 3 "ALARM__3" 4 "ALARM__4" 5 "ALARM__5" 6 "ALARM__6" 7 "ALARM__7" 8 "ALARM__8" 9 "ALARM__9" ;
VAL_ 2566890561 AlmSt 0 "ALARM_OFF" 1 "ALARM__1" 2 "ALARM__2" 3 "ALARM__3" 4 "ALARM__4" 5 "ALARM__5" ;
VAL_ 2566890792 OptSetJoyPatternChange 0 "ISO_FOR_CTL_EXC" 1 "BHL_FOR_CTL_BACKHOE" 2 "MHI" 3 "KOBE" 4 "SCM" 5 "CTL_ISO" 6 "CTL_H" ;
VAL_ 2566892072 ReqCallIndex 0 "NONE" 1 "1ST_INDEX" 2 "2ND_INDEX" 3 "3RD_INDEX" 4 "4TH_INDEX" 5 "5TH_INDEX" 6 "6TH_INDEX" 7 "7TH_INDEX" 8 "8TH_INDEX" 9 "9TH_INDEX" 10 "10TH_INDEX" ;
VAL_ 2566892072 PairingReq 0 "OFF" 1 "ON" 2 "ERROR" 3 "NOT_AVAILABLE" ;
VAL_ 2566892072 HangUpBtn 0 "OFF" 1 "ON" 2 "ERROR" 3 "NOT_AVAILABLE" ;
VAL_ 2566892072 DabSel 0 "OFF" 1 "ON" 2 "ERROR" 3 "NOT_AVAILABLE" ;
VAL_ 2566892072 MdSel 0 "OFF" 1 "ON" 2 "ERROR" 3 "NOT_AVAILABLE" ;
VAL_ 2566892072 AdoVolDownSel 0 "OFF" 1 "ON" 2 "ERROR" 3 "NOT_AVAILABLE" ;
VAL_ 2566892072 AdoVolUpSel 0 "OFF" 1 "ON" 2 "ERROR" 3 "NOT_AVAILABLE" ;
VAL_ 2566892072 BandSel 0 "OFF" 1 "ON" 2 "ERROR" 3 "NOT_AVAILABLE" ;
VAL_ 2566892072 TalkBtn 0 "OFF" 1 "ON" 2 "ERROR" 3 "NOT_AVAILABLE" ;
VAL_ 2566892072 AdoTuneDownSel 0 "OFF" 1 "ON" 2 "ERROR" 3 "NOT_AVAILABLE" ;
VAL_ 2566892072 AdoCallListPopupSt 0 "OFF" 1 "ON" 2 "ERROR" 3 "NOT_AVAILABLE" ;
VAL_ 2566892072 AdoMenuSel 0 "OFF" 1 "ON" 2 "ERROR" 3 "NOT_AVAILABLE" ;
VAL_ 2566892072 AdoPowerSel 0 "OFF" 1 "ON" 2 "ERROR" 3 "NOT_AVAILABLE" ;
VAL_ 2566892072 AdoP5Sel 0 "OFF" 1 "ON" 2 "ERROR" 3 "NOT_AVAILABLE" ;
VAL_ 2566892072 AdoP6Sel 0 "OFF" 1 "ON" 2 "ERROR" 3 "NOT_AVAILABLE" ;
VAL_ 2566892072 AdoTuneSel 0 "OFF" 1 "ON" 2 "ERROR" 3 "NOT_AVAILABLE" ;
VAL_ 2566892072 AdoTuneUpSel 0 "OFF" 1 "ON" 2 "ERROR" 3 "NOT_AVAILABLE" ;
VAL_ 2566892072 AdoP1Sel 0 "OFF" 1 "ON" 2 "ERROR" 3 "NOT_AVAILABLE" ;
VAL_ 2566892072 AdoP2Sel 0 "OFF" 1 "ON" 2 "ERROR" 3 "NOT_AVAILABLE" ;
VAL_ 2566892072 AdoP3Sel 0 "OFF" 1 "ON" 2 "ERROR" 3 "NOT_AVAILABLE" ;
VAL_ 2566892072 AdoP4Sel 0 "OFF" 1 "ON" 2 "ERROR" 3 "NOT_AVAILABLE" ;
VAL_ 2566892072 AdoFmSel 0 "OFF" 1 "ON" 2 "ERROR" 3 "NOT_AVAILABLE" ;
VAL_ 2566892072 AdoUsbSel 0 "OFF" 1 "ON" 2 "ERROR" 3 "NOT_AVAILABLE" ;
VAL_ 2566892072 AdoAuxSel 0 "OFF" 1 "ON" 2 "ERROR" 3 "NOT_AVAILABLE" ;
VAL_ 2566893620 WrnFobImmo 0 "OFF" 1 "ON_NO_BLINKING" 2 "ON_NORMAL_BLINKING" 3 "ON_SLOW_BLINKING" ;
VAL_ 2566893620 WrnFobLowBat 0 "OFF" 1 "ON_NO_BLINKING" 2 "ON_NORMAL_BLINKING" 3 "ON_SLOW_BLINKING" ;
VAL_ 2566893620 WrnNoFob 0 "OFF" 1 "ON_NO_BLINKING" 2 "ON_NORMAL_BLINKING" 3 "ON_SLOW_BLINKING" ;
VAL_ 2566893620 FobRgstFdbk 0 "NONE" 1 "NOT_DETECTION" 2 "DETECTION_COMPLETED" 3 "NOT_AVAILABLE" ;
VAL_ 2566893620 PreheatSt 0 "NONE" 1 "ON" 2 "OFF" 3 "FAILED" ;
VAL_ 2566893620 LampSt 0 "NONE" 1 "ON" 2 "OFF" 3 "FAILED" ;
VAL_ 2566893620 HvacSt 0 "NONE" 1 "ON" 2 "OFF" 3 "FAILED" ;
VAL_ 2566893620 DoorLckSt 0 "NONE" 1 "LOCK" 2 "UNLOCK" 3 "NOT_AVAILABLE" ;
VAL_ 2566894154 RmEgIdleMn 0 "5MIN_DEFAULT" 1 "10MIN" 2 "15MIN" 3 "20MIN" 4 "25MIN" 5 "30MIN" 6 "NOT_AVAILABLE" 7 "NONE" ;
VAL_ 2566894154 Beacon 0 "NONE" 1 "ON" 2 "OFF" 3 "FAILED" ;
VAL_ 2566894154 Horn 0 "NONE" 1 "ON" 2 "OFF" 3 "FAILED" ;
VAL_ 2566894154 DoorRls 0 "NONE" 1 "ON" 2 "OFF" 3 "FAILED" ;
VAL_ 2566894154 Lamp 0 "NONE" 1 "ON" 2 "OFF" 3 "FAILED" ;
VAL_ 2566894154 RmCrank 0 "NONE" 1 "ENGINE_ON" 2 "ENGINE_OFF" 3 "KEY_ON" ;
VAL_ 2566894154 Hvac 0 "NONE" 1 "ON" 2 "OFF" 3 "FAILED" ;
VAL_ 2566894154 DoorLck 0 "NONE" 1 "LOCK" 2 "UNLOCK" 3 "NOT_AVAILABLE" ;
VAL_ 2566894388 Acc10mUserCheck 0 "NORMAL_STATUS" 1 "ON" ;
VAL_ 2566894388 WelcomeSoundSetSt 0 "OFF" 1 "ON" 2 "ERROR" 3 "NOT_AVAILABLE" ;
VAL_ 2566894388 ResRmCrank 0 "NONE_TRY" 1 "SUCCESS" 2 "OPEN_MTDOOR" 3 "OPEN_CABDOOR" 4 "NO_PARK" 5 "NO_NEUTRAL" 6 "NO_CUTOFF" 7 "UNKNOWN_FAIL" ;
VAL_ 2566894388 NotWorkinCdt 0 "NOT_ACTIVE" 1 "ACK" 2 "NACK" ;
VAL_ 2566894388 RmCrankSt 0 "NORMAL_STATUS" 1 "REMOTE_START" ;
VAL_ 2566894388 BeaconSt 0 "ON" 1 "OFF" ;
VAL_ 2566894388 MtDoorSt 0 "OPEN" 1 "CLOSE" ;
VAL_ 2566894388 CabDoorSt 0 "OPEN" 1 "CLOSE" ;
VAL_ 2566894388 FobDtt 0 "FALSE" 1 "TRUE" 2 "ERROR" 3 "NOT_AVAILABLE" ;
VAL_ 2566894388 KeySt 0 "KEY_OFF" 1 "ACC" 2 "KEY_ON" 3 "CRANK_RUN" ;
VAL_ 2566896387 TrkLdTypeAutoShift 0 "AUTO_LOW_SPEED" 1 "AUTO_HIGH_SPEED" ;
VAL_ 2566896387 TrkLdTypeSyb2Spd 0 "LOW_SPEED" 1 "HIGH_SPEED" 2 "AUTO_SPEED" 3 "NOT_AVAILABLE" ;
VAL_ 2566896387 HstCutOffSVSt 0 "OFF" 1 "ON" 2 "CONDITION_GREEN" 3 "CONDITION_YELLOW" ;
VAL_ 2566896387 TwoSpdSVSt 0 "OFF" 1 "ON" 2 "CONDITION_GREEN" 3 "CONDITION_YELLOW" ;
VAL_ 2566896387 TrkLdTypeSybCreep 0 "OFF" 1 "ON" 2 "CONDITION_GREEN" 3 "CONDITION_YELLOW" ;
VAL_ 2566896643 SetJoyTrvlRLTrk 0 "SMOOTH" 1 "NORMAL" 2 "FAST" 3 "NOT_DEFINED" ;
VAL_ 2566896643 TrvlSpdPreset4Rvs 0 "SPEED_0" 1 "SPEED_0.5" 2 "SPEED_1" 3 "SPEED_1.5" 4 "SPEED_2" 5 "SPEED_2.5" 6 "SPEED_3" 7 "SPEED_3.5" 8 "SPEED_4" 9 "SPEED_4.5" 10 "SPEED_5" ;
VAL_ 2566896643 TrvlSpdPreset4Fwd 0 "SPEED_0" 1 "SPEED_0.5" 2 "SPEED_1" 3 "SPEED_1.5" 4 "SPEED_2" 5 "SPEED_2.5" 6 "SPEED_3" 7 "SPEED_3.5" 8 "SPEED_4" 9 "SPEED_4.5" 10 "SPEED_5" ;
VAL_ 2566896643 TrvlSpdPreset3Rvs 0 "SPEED_0" 1 "SPEED_0.5" 2 "SPEED_1" 3 "SPEED_1.5" 4 "SPEED_2" 5 "SPEED_2.5" 6 "SPEED_3" 7 "SPEED_3.5" 8 "SPEED_4" 9 "SPEED_4.5" 10 "SPEED_5" ;
VAL_ 2566896643 TrvlSpdPreset3Fwd 0 "SPEED_0" 1 "SPEED_0.5" 2 "SPEED_1" 3 "SPEED_1.5" 4 "SPEED_2" 5 "SPEED_2.5" 6 "SPEED_3" 7 "SPEED_3.5" 8 "SPEED_4" 9 "SPEED_4.5" 10 "SPEED_5" ;
VAL_ 2566896643 TrvlSpdPreset2Rvs 0 "SPEED_0" 1 "SPEED_0.5" 2 "SPEED_1" 3 "SPEED_1.5" 4 "SPEED_2" 5 "SPEED_2.5" 6 "SPEED_3" 7 "SPEED_3.5" 8 "SPEED_4" 9 "SPEED_4.5" 10 "SPEED_5" ;
VAL_ 2566896643 TrvlSpdPreset2Fwd 0 "SPEED_0" 1 "SPEED_0.5" 2 "SPEED_1" 3 "SPEED_1.5" 4 "SPEED_2" 5 "SPEED_2.5" 6 "SPEED_3" 7 "SPEED_3.5" 8 "SPEED_4" 9 "SPEED_4.5" 10 "SPEED_5" ;
VAL_ 2566896643 TrvlSpdPreset1Rvs 0 "SPEED_0" 1 "SPEED_0.5" 2 "SPEED_1" 3 "SPEED_1.5" 4 "SPEED_2" 5 "SPEED_2.5" 6 "SPEED_3" 7 "SPEED_3.5" 8 "SPEED_4" 9 "SPEED_4.5" 10 "SPEED_5" ;
VAL_ 2566896643 TrvlSpdPreset1Fwd 0 "SPEED_0" 1 "SPEED_0.5" 2 "SPEED_1" 3 "SPEED_1.5" 4 "SPEED_2" 5 "SPEED_2.5" 6 "SPEED_3" 7 "SPEED_3.5" 8 "SPEED_4" 9 "SPEED_4.5" 10 "SPEED_5" ;
VAL_ 2566896643 TrvlSpdSet 0 "PRESET_1" 1 "PRESET_2" 2 "PRESET_3" 3 "PRESET_4" ;
VAL_ 2566896643 BrkPdlDecel 0 "DISABLE" 1 "ENABLE" ;
VAL_ 2365570307 CurRvsMaxSpd 0 "NEUTRAL" 1 "SPEED_1" 2 "SPEED_2" 3 "SPEED_3" 4 "SPEED_4" 5 "SPEED_5" ;
VAL_ 2365570307 CurFwdMaxSpd 0 "NEUTRAL" 1 "SPEED_1" 2 "SPEED_2" 3 "SPEED_3" 4 "SPEED_4" 5 "SPEED_5" ;
VAL_ 2566897411 ParkingBrkReqSt 0 "OFF" 1 "ON" 2 "ERROR" 3 "NOT_AVAILABLE" ;
VAL_ 2566897411 CurPwrMd 0 "ECO" 1 "STD" 2 "PWR" 3 "NOT_AVAILABLE" ;
VAL_ 2566897411 CurFwdMaxSpd 0 "SPEED_0" 1 "SPEED_0.5" 2 "SPEED_1" 3 "SPEED_1.5" 4 "SPEED_2" 5 "SPEED_2.5" 6 "SPEED_3" 7 "SPEED_3.5" 8 "SPEED_4" 9 "SPEED_4.5" 10 "SPEED_5" ;
VAL_ 2365571105 LwIdleUpMd 0 "OFF" 1 "ON" 2 "ERROR" 3 "NOT_AVAILABLE" ;
VAL_ 2365571105 TwoSpdReadySt 0 "OFF" 1 "ON" 2 "ERROR" 3 "NOT_AVAILABLE" ;
VAL_ 2365571105 EgDeratingCtrl 0 "DERATING_CONTROL_OFF" 1 "DERATING_CONTROL_ON" 2 "ERROR" 3 "NOT_AVAILABLE" ;
VAL_ 2365571105 DmsActCmd 0 "OFF" 1 "ON" 2 "ERROR" 3 "NOT_AVAILABLE" ;
VAL_ 2365571105 RpmReqMd 0 "AUTOIDLE" 1 "LIMPHOME" 3 "NONE" ;
VAL_ 2365571105 ReqRvsMaxSpd 0 "NEUTRAL" 1 "SPEED_1" 2 "SPEED_2" 3 "SPEED_3" 4 "SPEED_4" 5 "SPEED_5" ;
VAL_ 2365571105 ReqFwdMaxSpd 0 "NEUTRAL" 1 "SPEED_1" 2 "SPEED_2" 3 "SPEED_3" 4 "SPEED_4" 5 "SPEED_5" ;
VAL_ 2365571105 PowMd 0 "ECO" 1 "STD" 2 "PWR" 3 "NOT_AVAILABLE" ;
VAL_ 2365571105 IsParking 0 "FALSE" 1 "TRUE" 2 "ERROR" 3 "NOT_AVAILABLE" ;
VAL_ 2365571105 TractionCtrl 0 "OFF" 1 "LOW" 2 "MEDIUM" 3 "HIGH" 4 "AUTO" ;
VAL_ 2365571361 OprtPresenceSt 0 "OFF" 1 "ON" 2 "ERROR" 3 "NOT_AVAILABLE" ;
VAL_ 2566902049 PhmPremium 0 "DISABLE" 1 "ENABLE" ;
VAL_ 2566902049 PhmBasic 0 "DISABLE" 1 "ENABLE" ;
VAL_ 2566902049 SetOwdActn 0 "DISABLE" 1 "ENABLE" ;
VAL_ 2566902049 AutoHold 0 "JOYSTICK_LEVER" 1 "THUMBWHEEL_STEERING" ;
VAL_ 2566902049 SetStickStr 0 "DISABLE" 1 "ENABLE" ;
VAL_ 2566902049 OptSetRttDir 0 "NORMAL" 1 "REVERSE" ;
VAL_ 2566902049 OptSetAutoBrkrSens 125 "VERY_HIGH" 126 "HIGH" 127 "SLIGHTLY_HIGH" 128 "MEDIUM" 129 "SLIGHTLY_LOW" 130 "LOW" 131 "VERY_LOW" ;
VAL_ 2566902049 OptSetAntiBlankFire 0 "DISABLE" 1 "ENABLE" ;
VAL_ 2566902049 OptSetCoolFanType 0 "HYDRAULIC_FAN" 1 "FAN_CLUTCH" 2 "DIRECT_FAN" ;
VAL_ 2566902049 OptSetRrCabLmp 0 "DISABLE" 1 "ENABLE" ;
VAL_ 2566902049 OptSetTwThwDir 0 "NORMAL" 1 "REVERSE" ;
VAL_ 2566902049 OptSetOptPdlType2 0 "HYDRAULIC" 1 "ELECTRIC" 2 "ELECTRONIC" ;
VAL_ 2566902049 OptSetMrrHt 0 "DISABLE" 1 "ENABLE" ;
VAL_ 2566902049 OptSetTrvlStrgtPdl 0 "DISABLE" 1 "ENABLE" ;
VAL_ 2566902049 OptSetTiltRttType 0 "NOT_AVAILABLE" 1 "ENCON" 3 "STEELWRIST" 4 "ROTOTILT" ;
VAL_ 2566902049 OptSetArtiBoom 0 "DISABLE" 1 "ENABLE" ;
VAL_ 2566902049 OptSetDzBlade 0 "DISABLE" 1 "ENABLE" ;
VAL_ 2566902049 OptSetJoyPtnChange 0 "ISO_FOR_CTL_EXC" 1 "BHL_FOR_CTL_BACKHOE" 2 "MHI" 3 "KOBE" 4 "SCM" 5 "CTL_ISO" 6 "CTL_H" ;
VAL_ 2566902049 OptSetTrvlSwgAlm 0 "TRAVEL_SWING" 1 "TRAVEL" 2 "SWING" ;
VAL_ 2566902049 OptSetLaserReceiver 0 "DISABLE" 1 "ENABLE" ;
VAL_ 2566902049 OptSetMgMc 0 "NONE" 1 "2D_MACHINE_GUIDANCE" 2 "3D_MACHINE_GUIDANCE" 3 "2D_MACHINE_GUIDANCE_SMART_CTRL" 4 "3D_MACHINE_GUIDANCE_SMART_CTRL" ;
VAL_ 2566902049 OptSetDKey 0 "DISABLE" 1 "ENABLE" ;
VAL_ 2566902049 OptSetCamLmp 0 "DISABLE" 1 "ENABLE" ;
VAL_ 2566902049 OptSetWiperType 0 "PARALLEL_WIPER" 1 "BASIC_WIPER" 2 "BASIC_WIPER_LOW_WIPER" ;
VAL_ 2566902049 OptSetFrCabLmp 0 "DISABLE" 1 "ENABLE" ;
VAL_ 2566902049 OptSetRvsFan 0 "DISABLE" 1 "ENABLE" ;
VAL_ 2566902049 OptSetRcw 0 "DISABLE" 1 "ENABLE" ;
VAL_ 2566902049 OptSetQckCoupler 0 "DISABLE" 1 "ENABLE" ;
VAL_ 2566902049 OptSetTrvlOrSwgAlm 0 "DISABLE" 1 "ENABLE" ;
VAL_ 2566902049 OptSetSmk 0 "DISABLE" 1 "ENABLE" ;
VAL_ 2566902049 OptSetOwd 0 "DISABLE" 1 "ENABLE" ;
VAL_ 2566902049 OptSetMchNameInit 0 "INITIAL_STAGE" 1 "SET" ;
VAL_ 2566902049 OptSetItgtFltBoom 0 "DISABLE" 1 "ENABLE" ;
VAL_ 2566902049 OptSetBeacon 0 "DISABLE" 1 "ENABLE" ;
VAL_ 2566902049 OptSetMultiFuncBtnSel 0 "WIPER_ON" 1 "SMART_BOOM_CUT" 2 "CAMERA_VIEW_MODE_CHANGE" 3 "RAM_LOCK__STATUS_CHANGE" 4 "AUDIO_MUTE" 5 "AUTO_BREAKER" 6 "FRONT_LIMITATION" 7 "NOT_DEFINED" ;
VAL_ 2566902049 OptSetAutoShutOff 0 "DISABLE" 1 "ENABLE" ;
VAL_ 2566902049 OptSetSpc 0 "DISABLE" 1 "ENABLE" ;
VAL_ 2566902049 OptSetTrvl2PmpCmbRls 0 "DISABLE" 1 "ENABLE" ;
VAL_ 2566902049 OptSetTrmsMaxSpdLmtChk 0 "NONE" 1 "CHECK" ;
VAL_ 2566902049 OptSetHhAlt 0 "DISABLE" 1 "ENABLE" ;
VAL_ 2566902049 OptSetRipperOpt 0 "DISABLE" 1 "ENABLE" ;
VAL_ 2566902049 OptSetRttOpt 0 "DISABLE" 1 "ENABLE" ;
VAL_ 2566902049 OptSetJoyThwRtt 0 "SLOW" 1 "NORMAL" 2 "FAST" ;
VAL_ 2566902049 OptSetJoyThwTw 0 "SLOW" 1 "NORMAL" 2 "FAST" ;
VAL_ 2566902049 OptSetTw 0 "NOT_AVAILABLE" 1 "JOYSTICK" 2 "OPTION_PEDAL" ;
VAL_ 2566902049 OptSetOptPdl 0 "HYDRAULIC" 1 "ELECTRIC" 2 "ELECTRONIC" ;
VAL_ 2566902049 OptSetAttPdlJoySel 0 "NOT_AVAILABLE" 1 "JOYSTICK" 2 "OPTION_PEDAL" 3 "JOYSTICK_OPTION_PEDAL" ;
VAL_ 2566902049 OptSet2Pmp 0 "DISABLE" 1 "ENABLE" ;
VAL_ 2566902049 OptSetAttTw 0 "DISABLE" 1 "ENABLE" ;
VAL_ 2566902049 OptSetAttBrkr 0 "DISABLE" 1 "ENABLE" ;
VAL_ 2566902049 OptWgh2D 0 "DISABLE" 1 "ENABLE" ;
VAL_ 2566902049 AdminUse2 0 "NONE" 1 "IGNITION_LOCK" 2 "ATTACHMENT" 4 "ENTERTAINMENT_RESTRICT" ;
VAL_ 2566902049 AdminUse1 0 "NONE" 1 "IGNITION_LOCK" 2 "ATTACHMENT" 4 "ENTERTAINMENT_RESTRICT" ;
VAL_ 2566902049 AdminUse0 0 "NONE" 1 "IGNITION_LOCK" 2 "ATTACHMENT" 4 "ENTERTAINMENT_RESTRICT" ;
VAL_ 2566902049 OwnerPw0UpTm 0 "ALWAYS" 1 "1MIN" 2 "5MIN" 3 "NOT_AVAILABLE" ;
